VERSION ""

NS_ :

BS_:

BU_: Tester BMS VCU MCU_R MCU_F PDU_DCDC OBC IMM

BO_ 293 CombinedChargerUnit10msNo2: 20 VCU
 SG_ PowerETractSys1LimMotMax : 80|16@1+ (50,-1638300) [-1638300|1638450] "W"  MCU_R,MCU_F
 SG_ PowerETractSys1LimGenMax : 64|16@1+ (50,-1638300) [-1638300|1638450] "W"  MCU_R,MCU_F
 SG_ PowerETractSys2LimGenMax : 32|16@1+ (50,-1638300) [-1638300|1638450] "W"  MCU_R,MCU_F
 SG_ OperatingModeEANActualValue : 96|8@1+ (1,0) [0|255] ""  MCU_R,MCU_F
 SG_ PowerETractSys2LimMotMax : 48|16@1+ (50,-1638300) [-1638300|1638450] "W"  MCU_R,MCU_F
 SG_ RequestExtraBoostETractSys2 : 138|2@1+ (1,0) [0|3] ""  MCU_R,MCU_F
 SG_ RequestExtraBoostETractSys1 : 136|2@1+ (1,0) [0|3] ""  MCU_R,MCU_F

BO_ 296 BundleEAFlexrayToAECANFD10msNo1: 64 VCU
 SG_ TAR_RPM_MAX_FTAX : 336|16@1+ (0.01,0) [0|655.35] "rad/s"  MCU_R,MCU_F
 SG_ TAR_RPM_MIN_FTAX : 352|16@1+ (0.01,0) [0|655.35] "rad/s"  MCU_R,MCU_F
 SG_ ST_TAR_RPM_FTAX : 368|4@1+ (1,0) [0|15] ""  MCU_R,MCU_F
 SG_ CRC_StatusSlipThresholds : 456|8@1+ (1,0) [0|255] ""  MCU_R,MCU_F
 SG_ CHL_StatusSlipThresholds : 468|4@1+ (1,0) [0|15] ""  MCU_R,MCU_F
 SG_ StatusSlipThresholdsFrontAxle : 472|4@1+ (1,0) [0|15] ""  MCU_R,MCU_F
 SG_ StatusSlipThresholdsRearAxle : 476|4@1+ (1,0) [0|15] ""  MCU_R,MCU_F
 SG_ ALIV_StatusSlipThresholds : 464|4@1+ (1,0) [0|14] ""  MCU_R,MCU_F
 SG_ ALIV_RQ_RPM_FTAX : 328|4@1+ (1,0) [0|14] ""  MCU_R,MCU_F
 SG_ AVL_BRTORQ_WHL_FS_LH_EXT : 176|16@1+ (1,-32000) [-32000|33535] "Nm"  MCU_R,MCU_F
 SG_ AVL_BRTORQ_WHL_FS_RH_EXT : 192|16@1+ (1,-32000) [-32000|33535] "Nm"  MCU_R,MCU_F
 SG_ CHL_EXTS_ARB_INTF : 140|4@1+ (1,0) [0|15] ""  MCU_R,MCU_F
 SG_ CHL_RQ_RPM_FTAX : 332|4@1+ (1,0) [0|15] ""  MCU_R,MCU_F
 SG_ CRC_RQ_RPM_BAX : 256|8@1+ (1,0) [0|255] ""  MCU_R,MCU_F
 SG_ ALIV_EXTS_ARB_INTF : 136|4@1+ (1,0) [0|14] ""  MCU_R,MCU_F
 SG_ CRC_EXTS_ARB_INTF : 128|8@1+ (1,0) [0|255] ""  MCU_R,MCU_F
 SG_ ALIV_RQ_RPM_BAX : 264|4@1+ (1,0) [0|14] ""  MCU_R,MCU_F
 SG_ CHL_RQ_RPM_BAX : 268|4@1+ (1,0) [0|15] ""  MCU_R,MCU_F
 SG_ TAR_RPM_MAX_BAX : 272|16@1+ (0.01,0) [0|655.35] "rad/s"  MCU_R,MCU_F
 SG_ TAR_RPM_MIN_BAX : 288|16@1+ (0.01,0) [0|655.35] "rad/s"  MCU_R,MCU_F
 SG_ ST_TAR_RPM_BAX : 304|4@1+ (1,0) [0|15] ""  MCU_R,MCU_F
 SG_ TAR_STIF_SPCO : 308|4@1+ (1,0) [0|15] ""  MCU_R,MCU_F
 SG_ CRC_RQ_RPM_FTAX : 320|8@1+ (1,0) [0|255] ""  MCU_R,MCU_F
 SG_ AVL_BRTORQ_WHL_RS_RH_EXT : 160|16@1+ (1,-32000) [-32000|33535] "Nm"  MCU_R,MCU_F
 SG_ AVL_BRTORQ_WHL_RS_LH_EXT : 144|16@1+ (1,-32000) [-32000|33535] "Nm"  MCU_R,MCU_F

BO_ 297 BundleEAFlexrayToAECANFD20msNo2: 20 VCU
 SG_ CRC_ACLNX_COG : 0|8@1+ (1,0) [0|255] ""  MCU_R,MCU_F
 SG_ ALIV_ACLNY_COG : 56|4@1+ (1,0) [0|14] ""  MCU_R,MCU_F
 SG_ CRC_ACLNY_COG : 48|8@1+ (1,0) [0|255] ""  MCU_R,MCU_F
 SG_ ACLNY_COG : 64|16@1+ (0.002,-65) [-65|65] "m/s²"  MCU_R,MCU_F
 SG_ QU_ACLNY_COG : 92|4@1+ (1,0) [1|15] ""  MCU_R,MCU_F
 SG_ ALIV_ACLNX_COG : 8|4@1+ (1,0) [0|14] ""  MCU_R,MCU_F
 SG_ QU_ACLNX_COG : 44|4@1+ (1,0) [1|15] ""  MCU_R,MCU_F
 SG_ ACLNX_COG : 16|16@1+ (0.002,-65) [-65|65] "m/s²"  MCU_R,MCU_F

BO_ 314 TracEMacElectc1Time100msNo1: 32 MCU_R
 SG_ StatusETractSys1Degradation : 56|32@1+ (1,0) [0|4294967295] ""  VCU
 SG_ ALIV_TracEMacElectc1Time100msNo1 : 16|8@1+ (1,0) [0|254] ""  VCU
 SG_ TETractSys1InverterActVal : 200|8@1+ (1,-48) [-48|207] "°C"  VCU
 SG_ TETractSys1EmStatorActVal : 192|8@1+ (1,-48) [-48|207] "°C"  VCU
 SG_ ThermalStressLevelETractSys1 : 184|8@1+ (0.5,0) [0|127.5] "%"  VCU
 SG_ TETractSys1EmRotorActVal : 176|8@1+ (1,-48) [-48|207] "°C"  VCU
 SG_ StatusExtraBoostETractSys1 : 170|2@1+ (1,0) [0|3] ""  VCU
 SG_ PercentUsedExtraBoostETractSys1 : 160|10@1+ (0.1,0) [0|102.3] "%"  VCU
 SG_ TETractSys1GbxOilActVal : 208|8@1+ (1,-48) [-48|207] "°C"  VCU
 SG_ WhlRatElAxlEtractSys1ActVal : 144|16@1+ (0.001,0) [0|65.535] ""  VCU
 SG_ StatusETractSys1LossActive : 124|4@1+ (1,0) [0|15] ""  VCU
 SG_ OpModETractSys1ActVal : 116|8@1+ (1,0) [0|255] ""  VCU
 SG_ StatusETractSys1CoolingActVal : 112|4@1+ (1,0) [0|15] ""  VCU
 SG_ TETractSys1CoolantWaterInpActVal : 104|8@1+ (1,-48) [-48|207] "°C"  VCU
 SG_ ActStatMeclLossesGbxETractSys1 : 88|12@1+ (1,0) [0|4095] "W"  VCU
 SG_ StatusETractSys1Error : 24|32@1+ (1,0) [0|4294967295] ""  VCU
 SG_ PowerETractSys1MaximumLossActive : 128|10@1+ (50,0) [0|51150] "W"  VCU
 SG_ CRC_TracEMacElectc1Time100msNo1 : 0|16@1+ (1,0) [0|65535] ""  VCU

BO_ 326 TracEMacElectc2Time100msNo1: 32 MCU_F
 SG_ CRC_TracEMacElectc2Time100msNo1 : 0|16@1+ (1,0) [0|65535] ""  VCU
 SG_ StatusETractSys2Degradation : 56|32@1+ (1,0) [0|4294967295] ""  VCU
 SG_ ALIV_TracEMacElectc2Time100msNo1 : 16|8@1+ (1,0) [0|254] ""  VCU
 SG_ StatusETractSys2Error : 24|32@1+ (1,0) [0|4294967295] ""  VCU
 SG_ ActStatMeclLossesGbxETractSys2 : 88|12@1+ (1,0) [0|4095] "W"  VCU
 SG_ TETractSys2CoolantWaterInpActVal : 104|8@1+ (1,-48) [-48|207] "°C"  VCU
 SG_ OpModETractSys2ActVal : 116|8@1+ (1,0) [0|255] ""  VCU
 SG_ StatusETractSys2LossActive : 124|4@1+ (1,0) [0|15] ""  VCU
 SG_ PowerETractSys2MaximumLossActive : 128|10@1+ (50,0) [0|51150] "W"  VCU
 SG_ WhlRatElAxlEtractSys2ActVal : 144|16@1+ (0.001,0) [0|65.535] ""  VCU
 SG_ PercentUsedExtraBoostETractSys2 : 160|10@1+ (0.1,0) [0|102.3] "%"  VCU
 SG_ StatusETractSys2CoolingActVal : 112|4@1+ (1,0) [0|15] ""  VCU
 SG_ TETractSys2EmRotorActVal : 176|8@1+ (1,-48) [-48|207] "°C"  VCU
 SG_ ThermalStressLevelETractSys2 : 184|8@1+ (0.5,0) [0|127.5] "%"  VCU
 SG_ TETractSys2EmStatorActVal : 192|8@1+ (1,-48) [-48|207] "°C"  VCU
 SG_ TETractSys2InverterActVal : 200|8@1+ (1,-48) [-48|207] "°C"  VCU
 SG_ TETractSys2GbxOilActVal : 208|8@1+ (1,-48) [-48|207] "°C"  VCU
 SG_ StatusExtraBoostETractSys2 : 170|2@1+ (1,0) [0|3] ""  VCU

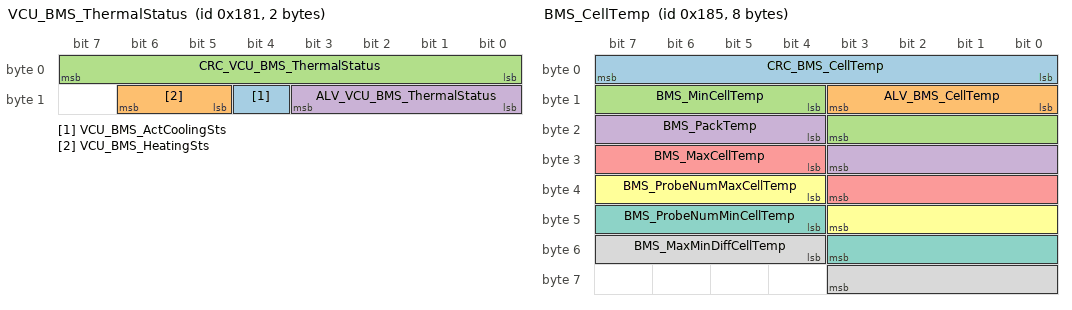
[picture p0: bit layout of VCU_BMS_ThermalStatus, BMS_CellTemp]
BO_ 385 VCU_BMS_ThermalStatus: 2 VCU
 SG_ VCU_BMS_ActCoolingSts : 12|1@1+ (1,0) [0|1] ""  BMS
 SG_ VCU_BMS_HeatingSts : 13|2@1+ (1,0) [0|3] ""  BMS
 SG_ CRC_VCU_BMS_ThermalStatus : 0|8@1+ (1,0) [0|255] ""  BMS
 SG_ ALV_VCU_BMS_ThermalStatus : 8|4@1+ (1,0) [0|14] ""  BMS

BO_ 389 BMS_CellTemp: 8 BMS
 SG_ CRC_BMS_CellTemp : 0|8@1+ (1,0) [0|255] ""  VCU
 SG_ ALV_BMS_CellTemp : 8|4@1+ (1,0) [0|14] ""  VCU
 SG_ BMS_MinCellTemp : 12|8@1+ (1,-40) [-40|215] "°C"  VCU
 SG_ BMS_PackTemp : 20|8@1+ (1,-40) [-40|215] "°C"  VCU
 SG_ BMS_MaxCellTemp : 28|8@1+ (1,-40) [-40|215] "°C"  VCU
 SG_ BMS_ProbeNumMaxCellTemp : 36|8@1+ (1,0) [0|255] ""  VCU
 SG_ BMS_ProbeNumMinCellTemp : 44|8@1+ (1,0) [0|255] ""  VCU
 SG_ BMS_MaxMinDiffCellTemp : 52|8@1+ (1,-40) [-40|215] "°C"  VCU

BO_ 394 BMS_CellTempMeas: 64 BMS
 SG_ BMS_CellTemp41 : 492|12@1+ (0.1,-40) [-40|215] "°C"  VCU
 SG_ BMS_CellTemp40 : 480|12@1+ (0.1,-40) [-40|215] "°C"  VCU
 SG_ BMS_CellTemp39 : 468|12@1+ (0.1,-40) [-40|215] "°C"  VCU
 SG_ BMS_CellTemp38 : 456|12@1+ (0.1,-40) [-40|215] "°C"  VCU
 SG_ BMS_CellTemp37 : 444|12@1+ (0.1,-40) [-40|215] "°C"  VCU
 SG_ BMS_CellTemp8 : 96|12@1+ (0.1,-40) [-40|215] "°C"  VCU
 SG_ BMS_CellTemp6 : 72|12@1+ (0.1,-40) [-40|215] "°C"  VCU
 SG_ BMS_CellTemp7 : 84|12@1+ (0.1,-40) [-40|215] "°C"  VCU
 SG_ BMS_CellTemp5 : 60|12@1+ (0.1,-40) [-40|215] "°C"  VCU
 SG_ ALV_BMS_CellTempMeas : 8|4@1+ (1,0) [0|14] ""  VCU
 SG_ BMS_CellTemp2 : 24|12@1+ (0.1,-40) [-40|215] "°C"  VCU
 SG_ BMS_CellTemp1 : 12|12@1+ (0.1,-40) [-40|215] "°C"  VCU
 SG_ CRC_BMS_CellTempMeas : 0|8@1+ (1,0) [0|255] ""  VCU
 SG_ BMS_CellTemp9 : 108|12@1+ (0.1,-40) [-40|215] "°C"  VCU
 SG_ BMS_CellTemp4 : 48|12@1+ (0.1,-40) [-40|215] "°C"  VCU
 SG_ BMS_CellTemp10 : 120|12@1+ (0.1,-40) [-40|215] "°C"  VCU
 SG_ BMS_CellTemp3 : 36|12@1+ (0.1,-40) [-40|215] "°C"  VCU
 SG_ BMS_CellTemp12 : 144|12@1+ (0.1,-40) [-40|215] "°C"  VCU
 SG_ BMS_CellTemp11 : 132|12@1+ (0.1,-40) [-40|215] "°C"  VCU
 SG_ BMS_CellTemp36 : 432|12@1+ (0.1,-40) [-40|215] "°C"  VCU
 SG_ BMS_CellTemp35 : 420|12@1+ (0.1,-40) [-40|215] "°C"  VCU
 SG_ BMS_CellTemp34 : 408|12@1+ (0.1,-40) [-40|215] "°C"  VCU
 SG_ BMS_CellTemp33 : 396|12@1+ (0.1,-40) [-40|215] "°C"  VCU
 SG_ BMS_CellTemp32 : 384|12@1+ (0.1,-40) [-40|215] "°C"  VCU
 SG_ BMS_CellTemp31 : 372|12@1+ (0.1,-40) [-40|215] "°C"  VCU
 SG_ BMS_CellTemp30 : 360|12@1+ (0.1,-40) [-40|215] "°C"  VCU
 SG_ BMS_CellTemp28 : 336|12@1+ (0.1,-40) [-40|215] "°C"  VCU
 SG_ BMS_CellTemp27 : 324|12@1+ (0.1,-40) [-40|215] "°C"  VCU
 SG_ BMS_CellTemp26 : 312|12@1+ (0.1,-40) [-40|215] "°C"  VCU
 SG_ BMS_CellTemp25 : 300|12@1+ (0.1,-40) [-40|215] "°C"  VCU
 SG_ BMS_CellTemp24 : 288|12@1+ (0.1,-40) [-40|215] "°C"  VCU
 SG_ BMS_CellTemp29 : 348|12@1+ (0.1,-40) [-40|215] "°C"  VCU
 SG_ BMS_CellTemp22 : 264|12@1+ (0.1,-40) [-40|215] "°C"  VCU
 SG_ BMS_CellTemp13 : 156|12@1+ (0.1,-40) [-40|215] "°C"  VCU
 SG_ BMS_CellTemp23 : 276|12@1+ (0.1,-40) [-40|215] "°C"  VCU
 SG_ BMS_CellTemp15 : 180|12@1+ (0.1,-40) [-40|215] "°C"  VCU
 SG_ BMS_CellTemp16 : 192|12@1+ (0.1,-40) [-40|215] "°C"  VCU
 SG_ BMS_CellTemp17 : 204|12@1+ (0.1,-40) [-40|215] "°C"  VCU
 SG_ BMS_CellTemp18 : 216|12@1+ (0.1,-40) [-40|215] "°C"  VCU
 SG_ BMS_CellTemp14 : 168|12@1+ (0.1,-40) [-40|215] "°C"  VCU
 SG_ BMS_CellTemp19 : 228|12@1+ (0.1,-40) [-40|215] "°C"  VCU
 SG_ BMS_CellTemp20 : 240|12@1+ (0.1,-40) [-40|215] "°C"  VCU
 SG_ BMS_CellTemp21 : 252|12@1+ (0.1,-40) [-40|215] "°C"  VCU

BO_ 399 BMS_CellVolMeas1: 48 BMS
 SG_ BMS_CellVol18 : 182|10@1+ (0.005,0) [0|5] "V"  VCU
 SG_ BMS_CellVol19 : 192|10@1+ (0.005,0) [0|5] "V"  VCU
 SG_ BMS_CellVol20 : 202|10@1+ (0.005,0) [0|5] "V"  VCU
 SG_ BMS_CellVol21 : 212|10@1+ (0.005,0) [0|5] "V"  VCU
 SG_ BMS_CellVol22 : 222|10@1+ (0.005,0) [0|5] "V"  VCU
 SG_ BMS_CellVol23 : 232|10@1+ (0.005,0) [0|5] "V"  VCU
 SG_ BMS_CellVol24 : 242|10@1+ (0.005,0) [0|5] "V"  VCU
 SG_ BMS_CellVol25 : 252|10@1+ (0.005,0) [0|5] "V"  VCU
 SG_ BMS_CellVol26 : 262|10@1+ (0.005,0) [0|5] "V"  VCU
 SG_ BMS_CellVol28 : 282|10@1+ (0.005,0) [0|5] "V"  VCU
 SG_ BMS_CellVol17 : 172|10@1+ (0.005,0) [0|5] "V"  VCU
 SG_ BMS_CellVol27 : 272|10@1+ (0.005,0) [0|5] "V"  VCU
 SG_ BMS_CellVol29 : 292|10@1+ (0.005,0) [0|5] "V"  VCU
 SG_ BMS_CellVol16 : 162|10@1+ (0.005,0) [0|5] "V"  VCU
 SG_ CRC_BMS_CellVolMeas : 0|8@1+ (1,0) [0|255] ""  VCU
 SG_ BMS_CellVol14 : 142|10@1+ (0.005,0) [0|5] "V"  VCU
 SG_ BMS_CellVol13 : 132|10@1+ (0.005,0) [0|5] "V"  VCU
 SG_ BMS_CellVol8 : 82|10@1+ (0.005,0) [0|5] "V"  VCU
 SG_ BMS_CellVol7 : 72|10@1+ (0.005,0) [0|5] "V"  VCU
 SG_ BMS_CellVol6 : 62|10@1+ (0.005,0) [0|5] "V"  VCU
 SG_ BMS_CellVol5 : 52|10@1+ (0.005,0) [0|5] "V"  VCU
 SG_ BMS_CellVol4 : 42|10@1+ (0.005,0) [0|5] "V"  VCU
 SG_ BMS_CellVol3 : 32|10@1+ (0.005,0) [0|5] "V"  VCU
 SG_ BMS_CellVol2 : 22|10@1+ (0.005,0) [0|5] "V"  VCU
 SG_ BMS_CellVol1 : 12|10@1+ (0.005,0) [0|5] "V"  VCU
 SG_ ALV_BMS_CellVolMeas : 8|4@1+ (1,0) [0|14] ""  VCU
 SG_ BMS_CellVol12 : 122|10@1+ (0.005,0) [0|5] "V"  VCU
 SG_ BMS_CellVol11 : 112|10@1+ (0.005,0) [0|5] "V"  VCU
 SG_ BMS_CellVol30 : 302|10@1+ (0.005,0) [0|5] "V"  VCU
 SG_ BMS_CellVol15 : 152|10@1+ (0.005,0) [0|5] "V"  VCU
 SG_ BMS_CellVol9 : 92|10@1+ (0.005,0) [0|5] "V"  VCU
 SG_ BMS_CellVol10 : 102|10@1+ (0.005,0) [0|5] "V"  VCU

BO_ 404 BMS_CellVolMeas2: 48 BMS
 SG_ BMS_CellVol56 : 262|10@1+ (0.005,0) [0|5] "V"  VCU
 SG_ BMS_CellVol38 : 82|10@1+ (0.005,0) [0|5] "V"  VCU
 SG_ BMS_CellVol37 : 72|10@1+ (0.005,0) [0|5] "V"  VCU
 SG_ BMS_CellVol36 : 62|10@1+ (0.005,0) [0|5] "V"  VCU
 SG_ BMS_CellVol35 : 52|10@1+ (0.005,0) [0|5] "V"  VCU
 SG_ BMS_CellVol34 : 42|10@1+ (0.005,0) [0|5] "V"  VCU
 SG_ BMS_CellVol33 : 32|10@1+ (0.005,0) [0|5] "V"  VCU
 SG_ BMS_CellVol32 : 22|10@1+ (0.005,0) [0|5] "V"  VCU
 SG_ BMS_CellVol31 : 12|10@1+ (0.005,0) [0|5] "V"  VCU
 SG_ ALV_BMS_CellVolMeas2 : 8|4@1+ (1,0) [0|14] ""  VCU
 SG_ CRC_BMS_CellVolMeas2 : 0|8@1+ (1,0) [0|255] ""  VCU
 SG_ BMS_CellVol59 : 292|10@1+ (0.005,0) [0|5] "V"  VCU
 SG_ BMS_CellVol60 : 302|10@1+ (0.005,0) [0|5] "V"  VCU
 SG_ BMS_CellVol61 : 312|10@1+ (0.005,0) [0|5] "V"  VCU
 SG_ BMS_CellVol62 : 322|10@1+ (0.005,0) [0|5] "V"  VCU
 SG_ BMS_CellVol57 : 272|10@1+ (0.005,0) [0|5] "V"  VCU
 SG_ BMS_CellVol39 : 92|10@1+ (0.005,0) [0|5] "V"  VCU
 SG_ BMS_CellVol40 : 102|10@1+ (0.005,0) [0|5] "V"  VCU
 SG_ BMS_CellVol42 : 122|10@1+ (0.005,0) [0|5] "V"  VCU
 SG_ BMS_CellVol49 : 192|10@1+ (0.005,0) [0|5] "V"  VCU
 SG_ BMS_CellVol53 : 232|10@1+ (0.005,0) [0|5] "V"  VCU
 SG_ BMS_CellVol52 : 222|10@1+ (0.005,0) [0|5] "V"  VCU
 SG_ BMS_CellVol51 : 212|10@1+ (0.005,0) [0|5] "V"  VCU
 SG_ BMS_CellVol50 : 202|10@1+ (0.005,0) [0|5] "V"  VCU
 SG_ BMS_CellVol48 : 182|10@1+ (0.005,0) [0|5] "V"  VCU
 SG_ BMS_CellVol46 : 162|10@1+ (0.005,0) [0|5] "V"  VCU
 SG_ BMS_CellVol47 : 172|10@1+ (0.005,0) [0|5] "V"  VCU
 SG_ BMS_CellVol44 : 142|10@1+ (0.005,0) [0|5] "V"  VCU
 SG_ BMS_CellVol43 : 132|10@1+ (0.005,0) [0|5] "V"  VCU
 SG_ BMS_CellVol58 : 282|10@1+ (0.005,0) [0|5] "V"  VCU
 SG_ BMS_CellVol41 : 112|10@1+ (0.005,0) [0|5] "V"  VCU
 SG_ BMS_CellVol55 : 252|10@1+ (0.005,0) [0|5] "V"  VCU
 SG_ BMS_CellVol45 : 152|10@1+ (0.005,0) [0|5] "V"  VCU
 SG_ BMS_CellVol54 : 242|10@1+ (0.005,0) [0|5] "V"  VCU

BO_ 405 OBC_Status: 20 OBC
 SG_ OBC_VCU_iDC : 120|11@1+ (0.1,-102.3) [-102.3|102.4] "Amps"  VCU
 SG_ OBC_VCU_vAC_L2 : 72|9@1+ (1,0) [0|511] "Volts"  VCU
 SG_ OBC_VCU_vAC_L1 : 40|9@1+ (1,0) [0|511] "Volts"  VCU
 SG_ OBC_VCU_iAC_L3 : 88|11@1+ (0.1,-102.3) [-102.3|102.4] "Amps"  VCU
 SG_ OBC_VCU_vDC : 131|10@1+ (1,0) [0|1023] "Volts"  VCU
 SG_ OBC_VCU_vAC_L3 : 104|9@1+ (1,0) [0|511] "Volts"  VCU
 SG_ OBC_VCU_iAC_L1 : 24|11@1+ (0.1,-102.3) [-102.3|102.4] "Amps"  VCU
 SG_ OBC_Max_Current_Out : 8|12@1+ (0.1,0) [0|409.5] "Amps"  VCU
 SG_ OBC_VCU_Status : 0|2@1+ (1,0) [0|3] ""  VCU
 SG_ OBC_VCU_iAC_L2 : 56|11@1+ (0.1,-102.3) [-102.3|102.4] "Amps"  VCU

BO_ 409 BMS_CellVolMeas3: 64 BMS
 SG_ BMS_CellVol82 : 202|10@1+ (0.005,0) [0|5] "V"  VCU
 SG_ BMS_CellVol86 : 242|10@1+ (0.005,0) [0|5] "V"  VCU
 SG_ BMS_CellVol83 : 212|10@1+ (0.005,0) [0|5] "V"  VCU
 SG_ BMS_CellVol84 : 222|10@1+ (0.005,0) [0|5] "V"  VCU
 SG_ BMS_CellVol87 : 252|10@1+ (0.005,0) [0|5] "V"  VCU
 SG_ BMS_CellVol94 : 322|10@1+ (0.005,0) [0|5] "V"  VCU
 SG_ BMS_CellVol89 : 272|10@1+ (0.005,0) [0|5] "V"  VCU
 SG_ BMS_CellVol90 : 282|10@1+ (0.005,0) [0|5] "V"  VCU
 SG_ BMS_CellVol91 : 292|10@1+ (0.005,0) [0|5] "V"  VCU
 SG_ BMS_CellVol92 : 302|10@1+ (0.005,0) [0|5] "V"  VCU
 SG_ BMS_CellVol93 : 312|10@1+ (0.005,0) [0|5] "V"  VCU
 SG_ BMS_CellVol81 : 192|10@1+ (0.005,0) [0|5] "V"  VCU
 SG_ BMS_CellVol88 : 262|10@1+ (0.005,0) [0|5] "V"  VCU
 SG_ BMS_CellVol80 : 182|10@1+ (0.005,0) [0|5] "V"  VCU
 SG_ BMS_CellVol85 : 232|10@1+ (0.005,0) [0|5] "V"  VCU
 SG_ BMS_CellVol78 : 162|10@1+ (0.005,0) [0|5] "V"  VCU
 SG_ BMS_CellVol70 : 82|10@1+ (0.005,0) [0|5] "V"  VCU
 SG_ BMS_CellVol67 : 52|10@1+ (0.005,0) [0|5] "V"  VCU
 SG_ BMS_CellVol79 : 172|10@1+ (0.005,0) [0|5] "V"  VCU
 SG_ BMS_CellVol66 : 42|10@1+ (0.005,0) [0|5] "V"  VCU
 SG_ BMS_CellVol65 : 32|10@1+ (0.005,0) [0|5] "V"  VCU
 SG_ BMS_CellVol64 : 22|10@1+ (0.005,0) [0|5] "V"  VCU
 SG_ BMS_CellVol63 : 12|10@1+ (0.005,0) [0|5] "V"  VCU
 SG_ ALV_BMS_CellVolMeas3 : 8|4@1+ (1,0) [0|14] ""  VCU
 SG_ BMS_CellVol69 : 72|10@1+ (0.005,0) [0|5] "V"  VCU
 SG_ CRC_BMS_CellVolMeas3 : 0|8@1+ (1,0) [0|255] ""  VCU
 SG_ BMS_CellVol71 : 92|10@1+ (0.005,0) [0|5] "V"  VCU
 SG_ BMS_CellVol68 : 62|10@1+ (0.005,0) [0|5] "V"  VCU
 SG_ BMS_CellVol73 : 112|10@1+ (0.005,0) [0|5] "V"  VCU
 SG_ BMS_CellVol75 : 132|10@1+ (0.005,0) [0|5] "V"  VCU
 SG_ BMS_CellVol72 : 102|10@1+ (0.005,0) [0|5] "V"  VCU
 SG_ BMS_CellVol77 : 152|10@1+ (0.005,0) [0|5] "V"  VCU
 SG_ BMS_CellVol74 : 122|10@1+ (0.005,0) [0|5] "V"  VCU
 SG_ BMS_CellVol76 : 142|10@1+ (0.005,0) [0|5] "V"  VCU
 SG_ BMS_CellVol95 : 332|10@1+ (0.005,0) [0|5] "V"  VCU
 SG_ BMS_CellVol96 : 342|10@1+ (0.005,0) [0|5] "V"  VCU
 SG_ BMS_CellVol97 : 352|10@1+ (0.005,0) [0|5] "V"  VCU
 SG_ BMS_CellVol98 : 362|10@1+ (0.005,0) [0|5] "V"  VCU
 SG_ BMS_CellVol99 : 372|10@1+ (0.005,0) [0|5] "V"  VCU
 SG_ BMS_CellVol100 : 382|10@1+ (0.005,0) [0|5] "V"  VCU
 SG_ BMS_CellVol101 : 392|10@1+ (0.005,0) [0|5] "V"  VCU
 SG_ BMS_CellVol102 : 402|10@1+ (0.005,0) [0|5] "V"  VCU
 SG_ BMS_CellVol103 : 412|10@1+ (0.005,0) [0|5] "V"  VCU
 SG_ BMS_CellVol104 : 422|10@1+ (0.005,0) [0|5] "V"  VCU
 SG_ BMS_CellVol105 : 432|10@1+ (0.005,0) [0|5] "V"  VCU
 SG_ BMS_CellVol106 : 442|10@1+ (0.005,0) [0|5] "V"  VCU
 SG_ BMS_CellVol107 : 452|10@1+ (0.005,0) [0|5] "V"  VCU
 SG_ BMS_CellVol108 : 462|10@1+ (0.005,0) [0|5] "V"  VCU

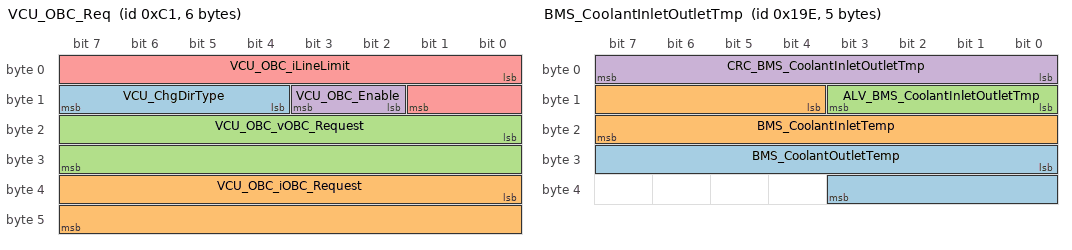
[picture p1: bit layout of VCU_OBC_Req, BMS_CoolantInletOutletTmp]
BO_ 193 VCU_OBC_Req: 6 VCU
 SG_ VCU_ChgDirType : 12|4@1+ (1,0) [0|15] ""  OBC
 SG_ VCU_OBC_iOBC_Request : 32|16@1+ (0.0625,0) [0|4095.9375] "Amps"  OBC
 SG_ VCU_OBC_vOBC_Request : 16|16@1+ (0.0625,0) [0|4095.9375] "Volts"  OBC
 SG_ VCU_OBC_Enable : 10|2@1+ (1,0) [0|3] ""  OBC
 SG_ VCU_OBC_iLineLimit : 0|10@1+ (0.0625,0) [0|63.9375] "Amps"  OBC

BO_ 414 BMS_CoolantInletOutletTmp: 5 BMS
 SG_ BMS_CoolantOutletTemp : 24|12@1+ (0.1,-40) [-40|255] "°C"  VCU
 SG_ BMS_CoolantInletTemp : 12|12@1+ (0.1,-40) [-40|255] "°C"  VCU
 SG_ ALV_BMS_CoolantInletOutletTmp : 8|4@1+ (1,0) [0|14] ""  VCU
 SG_ CRC_BMS_CoolantInletOutletTmp : 0|8@1+ (1,0) [0|255] ""  VCU

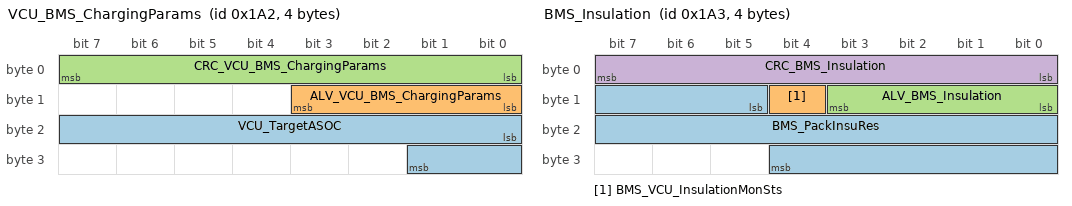
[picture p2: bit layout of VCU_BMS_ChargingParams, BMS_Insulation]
BO_ 418 VCU_BMS_ChargingParams: 4 VCU
 SG_ VCU_TargetASOC : 16|10@1+ (0.1,0) [0|100] "%"  BMS
 SG_ ALV_VCU_BMS_ChargingParams : 8|4@1+ (1,0) [0|14] ""  BMS
 SG_ CRC_VCU_BMS_ChargingParams : 0|8@1+ (1,0) [0|255] ""  BMS

BO_ 419 BMS_Insulation: 4 BMS
 SG_ BMS_PackInsuRes : 13|16@1+ (1,0) [0|60000] "kOhm"  VCU
 SG_ BMS_VCU_InsulationMonSts : 12|1@1+ (1,0) [0|1] ""  VCU
 SG_ ALV_BMS_Insulation : 8|4@1+ (1,0) [0|14] ""  VCU
 SG_ CRC_BMS_Insulation : 0|8@1+ (1,0) [0|255] ""  VCU

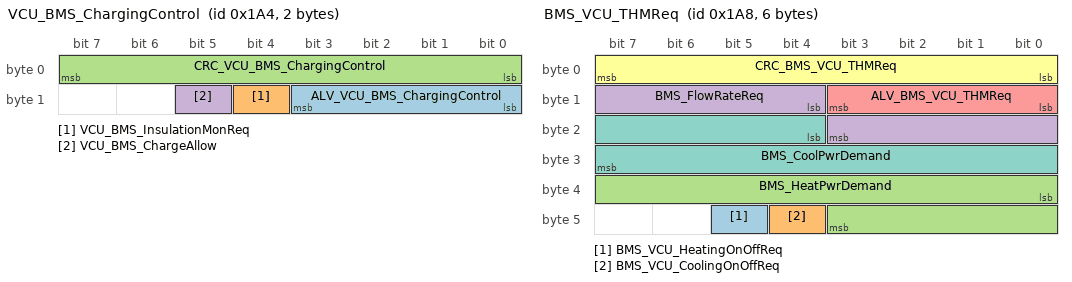
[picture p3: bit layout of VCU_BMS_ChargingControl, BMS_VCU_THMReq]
BO_ 420 VCU_BMS_ChargingControl: 2 VCU
 SG_ ALV_VCU_BMS_ChargingControl : 8|4@1+ (1,0) [0|14] ""  BMS
 SG_ VCU_BMS_InsulationMonReq : 12|1@1+ (1,0) [0|1] ""  BMS
 SG_ CRC_VCU_BMS_ChargingControl : 0|8@1+ (1,0) [0|255] ""  BMS
 SG_ VCU_BMS_ChargeAllow : 13|1@1+ (1,0) [0|1] ""  BMS

BO_ 424 BMS_VCU_THMReq: 6 BMS
 SG_ BMS_VCU_HeatingOnOffReq : 45|1@1+ (1,0) [0|1] ""  VCU
 SG_ BMS_VCU_CoolingOnOffReq : 44|1@1+ (1,0) [0|1] ""  VCU
 SG_ BMS_HeatPwrDemand : 32|12@1+ (0.1,0) [0|25.5] "kW"  VCU
 SG_ BMS_FlowRateReq : 12|8@1+ (1,0) [0|255] "l/min"  VCU
 SG_ ALV_BMS_VCU_THMReq : 8|4@1+ (1,0) [0|14] ""  VCU
 SG_ CRC_BMS_VCU_THMReq : 0|8@1+ (1,0) [0|255] ""  VCU
 SG_ BMS_CoolPwrDemand : 20|12@1+ (0.1,0) [0|25.5] "kW"  VCU

BO_ 429 BMS_VolMeas: 12 BMS
 SG_ BMS_MaxCellVol : 44|16@1+ (0.001,0) [0|5] "V"  VCU
 SG_ BMS_MinCellVol : 28|16@1+ (0.001,0) [0|5] "V"  VCU
 SG_ BMS_CellNumMaxCellVol : 20|8@1+ (1,0) [0|112] ""  VCU
 SG_ BMS_CellNumMinCellVol : 12|8@1+ (1,0) [0|112] ""  VCU
 SG_ ALV_BMS_VolMeas : 8|4@1+ (1,0) [0|14] ""  VCU
 SG_ CRC_BMS_VolMeas : 0|8@1+ (1,0) [0|255] ""  VCU
 SG_ BMS_MaxMinDiffCellVol : 60|16@1+ (0.001,0) [0|5] "V"  VCU

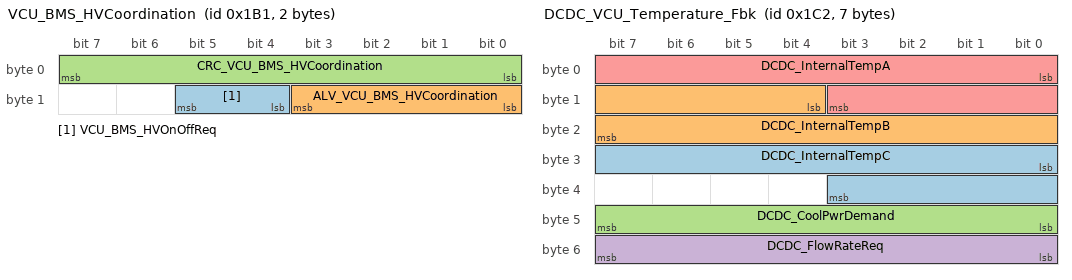
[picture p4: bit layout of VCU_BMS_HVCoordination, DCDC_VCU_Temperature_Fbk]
BO_ 433 VCU_BMS_HVCoordination: 2 VCU
 SG_ VCU_BMS_HVOnOffReq : 12|2@1+ (1,0) [0|3] ""  BMS
 SG_ ALV_VCU_BMS_HVCoordination : 8|4@1+ (1,0) [0|14] ""  BMS
 SG_ CRC_VCU_BMS_HVCoordination : 0|8@1+ (1,0) [0|255] ""  BMS

BO_ 450 DCDC_VCU_Temperature_Fbk: 7 PDU_DCDC
 SG_ DCDC_InternalTempC : 24|12@1+ (0.1,-100) [-100|309.5] "°C"  VCU
 SG_ DCDC_InternalTempB : 12|12@1+ (0.1,-100) [-100|309.5] "°C"  VCU
 SG_ DCDC_CoolPwrDemand : 40|8@1+ (0.01,0) [0|2.55] "kW"  VCU
 SG_ DCDC_FlowRateReq : 48|8@1+ (1,0) [0|31] "l/min"  VCU
 SG_ DCDC_InternalTempA : 0|12@1+ (0.1,-100) [-100|309.5] "°C"  VCU

BO_ 490 Kilometerstand_2: 8 VCU
 SG_ MILE_KM_TOT : 0|32@1+ (0.001,0) [0|4294967.295] "km"  MCU_R,MCU_F

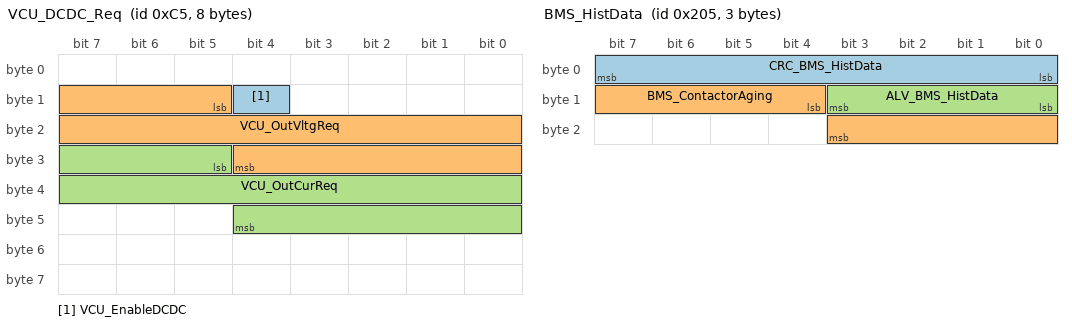
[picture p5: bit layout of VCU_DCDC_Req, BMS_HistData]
BO_ 197 VCU_DCDC_Req: 8 VCU
 SG_ VCU_EnableDCDC : 12|1@1+ (1,0) [0|1] ""  PDU_DCDC
 SG_ VCU_OutVltgReq : 13|16@1+ (0.0625,0) [0|4095.9375] "V"  PDU_DCDC
 SG_ VCU_OutCurReq : 29|16@1+ (0.1,0) [0|6553.5] "A"  PDU_DCDC

BO_ 517 BMS_HistData: 3 BMS
 SG_ CRC_BMS_HistData : 0|8@1+ (1,0) [0|255] ""  VCU
 SG_ BMS_ContactorAging : 12|8@1+ (1,0) [0|100] "%"  VCU
 SG_ ALV_BMS_HistData : 8|4@1+ (1,0) [0|14] ""  VCU

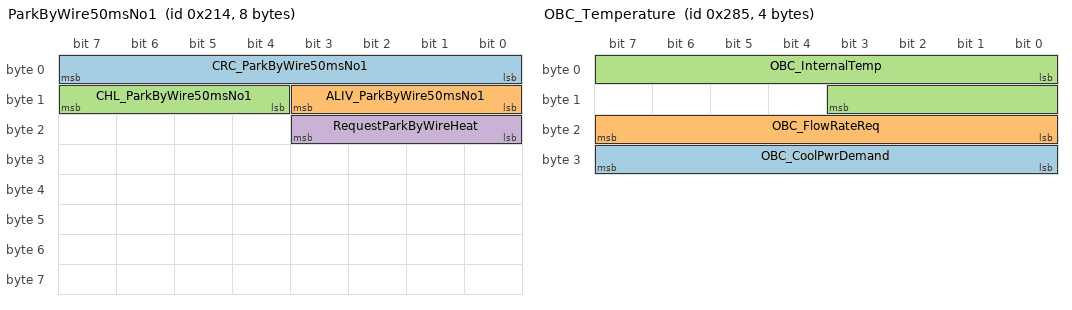
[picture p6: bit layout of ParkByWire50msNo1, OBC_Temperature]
BO_ 532 ParkByWire50msNo1: 8 VCU
 SG_ CRC_ParkByWire50msNo1 : 0|8@1+ (1,0) [0|255] ""  MCU_R,MCU_F
 SG_ ALIV_ParkByWire50msNo1 : 8|4@1+ (1,0) [0|14] ""  MCU_R,MCU_F
 SG_ CHL_ParkByWire50msNo1 : 12|4@1+ (1,0) [0|15] ""  MCU_R,MCU_F
 SG_ RequestParkByWireHeat : 16|4@1+ (1,0) [0|15] ""  MCU_R,MCU_F

BO_ 630 FZZSTD: 8 VCU
 SG_ ST_ENERG_FZM : 16|4@1+ (1,0) [0|15] ""  MCU_R,MCU_F
 SG_ ST_ILK_ERRM_FZM : 56|2@1+ (1,0) [0|3] ""  MCU_R,MCU_F

BO_ 632 STAT_ANHAENGER: 8 VCU
 SG_ ST_TRAI : 0|2@1+ (1,0) [0|3] ""  MCU_R,MCU_F

BO_ 645 OBC_Temperature: 4 OBC
 SG_ OBC_CoolPwrDemand : 24|8@1+ (0.1,0) [0|25.5] "Kw"  VCU
 SG_ OBC_FlowRateReq : 16|8@1+ (1,0) [0|31] "l/min"  VCU
 SG_ OBC_InternalTemp : 0|12@1+ (0.1,-50) [-50|359.5] "°C"  VCU

BO_ 749 A_TEMP: 2 VCU
 SG_ TEMP_EX : 0|8@1+ (0.5,-40) [-40|87.5] "°C"  BMS,MCU_R,MCU_F

BO_ 811 DMEBK100: 24 VCU
 SG_ ActValVolFlowCoolantETractSys1 : 80|8@1+ (20,0) [0|5100] "l/h"  MCU_R,MCU_F
 SG_ ActValVolFlowCoolantETractSys2 : 56|8@1+ (20,0) [0|5100] "l/h"  MCU_R,MCU_F

BO_ 832 CombinedChargerUnit100msNo1: 12 VCU
 SG_ ALIV_CombinedChargerUnit100msNo1 : 16|8@1+ (1,0) [0|254] ""  MCU_R,MCU_F
 SG_ RequestPowerETractSys1Loss : 48|10@1+ (50,0) [0|51150] "W"  MCU_R,MCU_F
 SG_ CRC_CombinedChargerUnit100msNo1 : 0|16@1+ (1,0) [0|65535] ""  MCU_R,MCU_F
 SG_ RequestPowerETractSys2Loss : 58|10@1+ (50,0) [0|51150] "W"  MCU_R,MCU_F

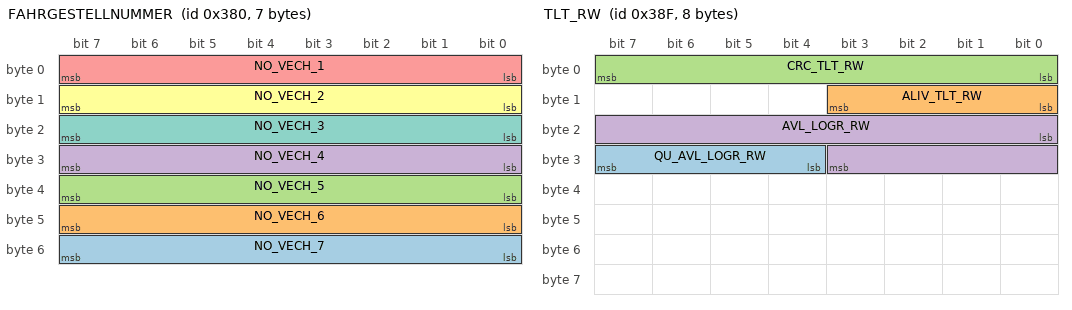
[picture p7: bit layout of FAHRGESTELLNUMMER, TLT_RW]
BO_ 896 FAHRGESTELLNUMMER: 7 VCU
 SG_ NO_VECH_7 : 48|8@1+ (1,0) [0|255] ""  MCU_R,MCU_F
 SG_ NO_VECH_6 : 40|8@1+ (1,0) [0|255] ""  MCU_R,MCU_F
 SG_ NO_VECH_5 : 32|8@1+ (1,0) [0|255] ""  MCU_R,MCU_F
 SG_ NO_VECH_4 : 24|8@1+ (1,0) [0|255] ""  MCU_R,MCU_F
 SG_ NO_VECH_1 : 0|8@1+ (1,0) [0|255] ""  MCU_R,MCU_F
 SG_ NO_VECH_2 : 8|8@1+ (1,0) [0|255] ""  MCU_R,MCU_F
 SG_ NO_VECH_3 : 16|8@1+ (1,0) [0|255] ""  MCU_R,MCU_F

BO_ 911 TLT_RW: 8 VCU
 SG_ QU_AVL_LOGR_RW : 28|4@1+ (1,0) [1|15] ""  MCU_R,MCU_F
 SG_ ALIV_TLT_RW : 8|4@1+ (1,0) [0|14] ""  MCU_R,MCU_F
 SG_ CRC_TLT_RW : 0|8@1+ (1,0) [0|255] ""  MCU_R,MCU_F
 SG_ AVL_LOGR_RW : 16|12@1+ (0.05,-64) [-64|140.75] "°"  MCU_R,MCU_F

BO_ 1052 KILOMETERSTAND: 8 VCU
 SG_ MILE_KM : 0|24@1+ (1,0) [0|16777215] "km"  MCU_R,MCU_F

BO_ 1090 RELATIVZEIT: 6 VCU
 SG_ T_SEC_COU_REL : 0|32@1+ (1,0) [0|4294967295] "s"  MCU_R,MCU_F

BO_ 1107 HighVoltageStorage200msNo1: 4 BMS
 SG_ StsDisconnectingSwtHighVoltStorg : 26|6@1+ (1,0) [0|63] ""  VCU,MCU_R,MCU_F
 SG_ StatusServiceDisconnectionPlug : 24|2@1+ (1,0) [1|3] ""  VCU,MCU_R,MCU_F

BO_ 1120 EnergyStorageMeasurementValues: 8 VCU
 SG_ EnergyStorageClamp30VoltageValue : 16|16@1+ (0.001,0) [0|65.535] "V"  MCU_R,MCU_F

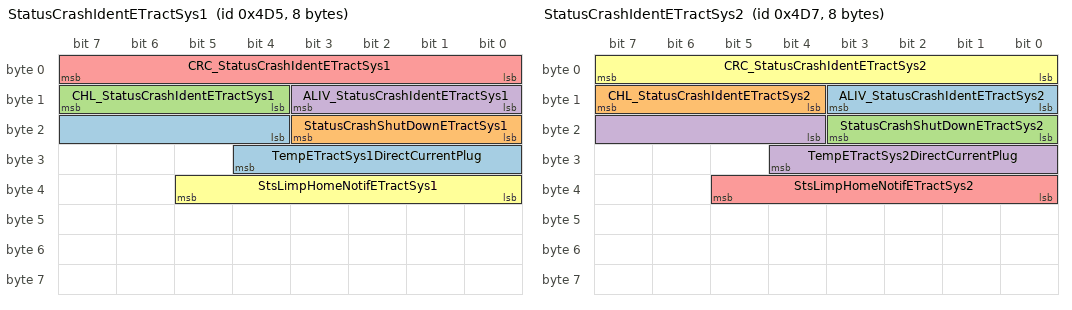
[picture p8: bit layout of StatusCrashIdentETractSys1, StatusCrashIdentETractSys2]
BO_ 1237 StatusCrashIdentETractSys1: 8 MCU_R
 SG_ TempETractSys1DirectCurrentPlug : 20|9@1+ (0.5,-40) [-40|215.5] "°C"  VCU
 SG_ StatusCrashShutDownETractSys1 : 16|4@1+ (1,0) [0|15] ""  VCU
 SG_ CHL_StatusCrashIdentETractSys1 : 12|4@1+ (1,0) [0|15] ""  VCU
 SG_ ALIV_StatusCrashIdentETractSys1 : 8|4@1+ (1,0) [0|14] ""  VCU
 SG_ CRC_StatusCrashIdentETractSys1 : 0|8@1+ (1,0) [0|255] ""  VCU
 SG_ StsLimpHomeNotifETractSys1 : 32|6@1+ (1,0) [0|63] ""  VCU

BO_ 1239 StatusCrashIdentETractSys2: 8 MCU_F
 SG_ ALIV_StatusCrashIdentETractSys2 : 8|4@1+ (1,0) [0|14] ""  VCU
 SG_ CHL_StatusCrashIdentETractSys2 : 12|4@1+ (1,0) [0|15] ""  VCU
 SG_ StatusCrashShutDownETractSys2 : 16|4@1+ (1,0) [0|15] ""  VCU
 SG_ TempETractSys2DirectCurrentPlug : 20|9@1+ (0.5,-40) [-40|215.5] "°C"  VCU
 SG_ StsLimpHomeNotifETractSys2 : 32|6@1+ (1,0) [0|63] ""  VCU
 SG_ CRC_StatusCrashIdentETractSys2 : 0|8@1+ (1,0) [0|255] ""  VCU

BO_ 1272 CombinedChargerUnit1000msNo1: 24 VCU
 SG_ TemperatureCoolantOutput : 44|12@1+ (0.1,-40) [-40|369.5] "°C"  MCU_R,MCU_F

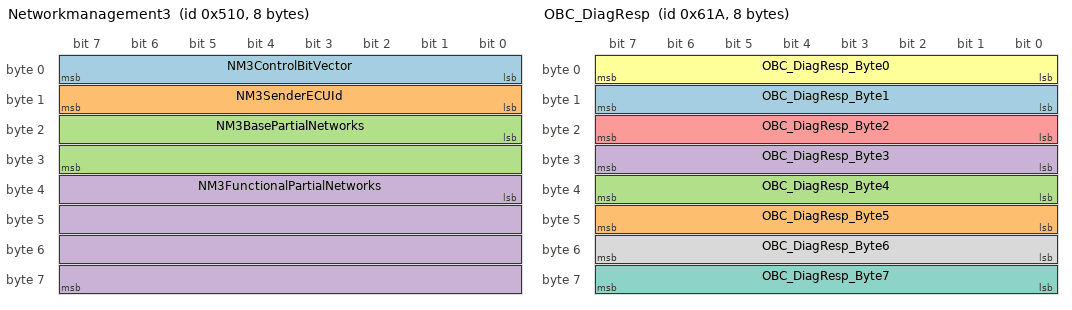
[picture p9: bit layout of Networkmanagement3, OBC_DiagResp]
BO_ 1296 Networkmanagement3: 8 VCU
 SG_ NM3ControlBitVector : 0|8@1+ (1,0) [64|255] ""  MCU_R,MCU_F
 SG_ NM3SenderECUId : 8|8@1+ (1,0) [0|255] ""  MCU_R,MCU_F
 SG_ NM3BasePartialNetworks : 16|16@1+ (1,0) [0|65535] ""  MCU_R,MCU_F
 SG_ NM3FunctionalPartialNetworks : 32|32@1+ (1,0) [0|4294967295] ""  MCU_R,MCU_F

BO_ 1562 OBC_DiagResp: 8 OBC
 SG_ OBC_DiagResp_Byte1 : 8|8@1+ (1,0) [0|255] ""  Tester
 SG_ OBC_DiagResp_Byte5 : 40|8@1+ (1,0) [0|255] ""  Tester
 SG_ OBC_DiagResp_Byte4 : 32|8@1+ (1,0) [0|255] ""  Tester
 SG_ OBC_DiagResp_Byte3 : 24|8@1+ (1,0) [0|255] ""  Tester
 SG_ OBC_DiagResp_Byte2 : 16|8@1+ (1,0) [0|255] ""  Tester
 SG_ OBC_DiagResp_Byte0 : 0|8@1+ (1,0) [0|255] ""  Tester
 SG_ OBC_DiagResp_Byte7 : 56|8@1+ (1,0) [0|255] ""  Tester
 SG_ OBC_DiagResp_Byte6 : 48|8@1+ (1,0) [0|255] ""  Tester

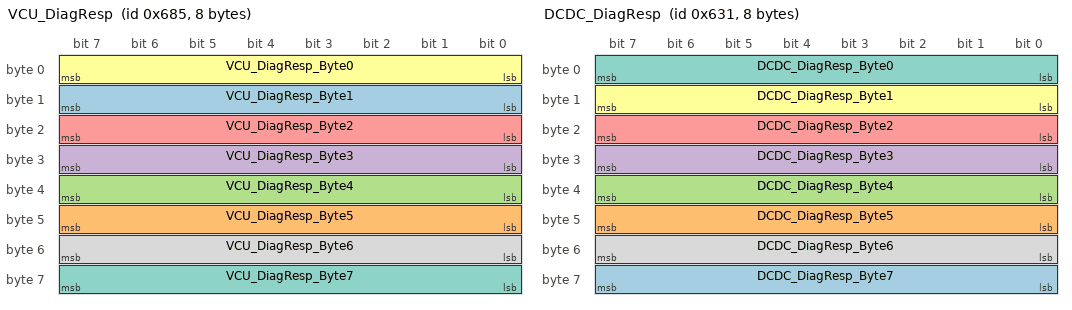
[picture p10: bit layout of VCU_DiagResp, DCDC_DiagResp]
BO_ 1669 VCU_DiagResp: 8 VCU
 SG_ VCU_DiagResp_Byte1 : 8|8@1+ (1,0) [0|255] ""  Tester
 SG_ VCU_DiagResp_Byte5 : 40|8@1+ (1,0) [0|255] ""  Tester
 SG_ VCU_DiagResp_Byte4 : 32|8@1+ (1,0) [0|255] ""  Tester
 SG_ VCU_DiagResp_Byte3 : 24|8@1+ (1,0) [0|255] ""  Tester
 SG_ VCU_DiagResp_Byte2 : 16|8@1+ (1,0) [0|255] ""  Tester
 SG_ VCU_DiagResp_Byte0 : 0|8@1+ (1,0) [0|255] ""  Tester
 SG_ VCU_DiagResp_Byte7 : 56|8@1+ (1,0) [0|255] ""  Tester
 SG_ VCU_DiagResp_Byte6 : 48|8@1+ (1,0) [0|255] ""  Tester

BO_ 1585 DCDC_DiagResp: 8 PDU_DCDC
 SG_ DCDC_DiagResp_Byte7 : 56|8@1+ (1,0) [0|255] ""  Tester
 SG_ DCDC_DiagResp_Byte5 : 40|8@1+ (1,0) [0|255] ""  Tester
 SG_ DCDC_DiagResp_Byte4 : 32|8@1+ (1,0) [0|255] ""  Tester
 SG_ DCDC_DiagResp_Byte3 : 24|8@1+ (1,0) [0|255] ""  Tester
 SG_ DCDC_DiagResp_Byte2 : 16|8@1+ (1,0) [0|255] ""  Tester
 SG_ DCDC_DiagResp_Byte1 : 8|8@1+ (1,0) [0|255] ""  Tester
 SG_ DCDC_DiagResp_Byte0 : 0|8@1+ (1,0) [0|255] ""  Tester
 SG_ DCDC_DiagResp_Byte6 : 48|8@1+ (1,0) [0|255] ""  Tester

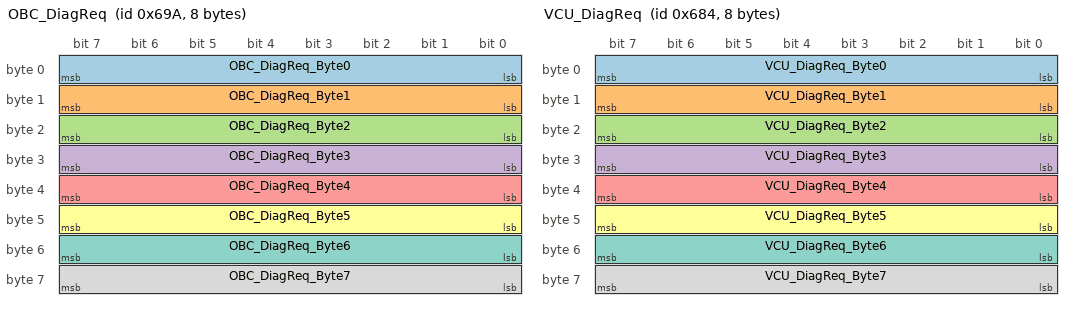
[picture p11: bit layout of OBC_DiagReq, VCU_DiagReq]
BO_ 1690 OBC_DiagReq: 8 Tester
 SG_ OBC_DiagReq_Byte0 : 0|8@1+ (1,0) [0|255] ""  OBC
 SG_ OBC_DiagReq_Byte1 : 8|8@1+ (1,0) [0|255] ""  OBC
 SG_ OBC_DiagReq_Byte2 : 16|8@1+ (1,0) [0|255] ""  OBC
 SG_ OBC_DiagReq_Byte3 : 24|8@1+ (1,0) [0|255] ""  OBC
 SG_ OBC_DiagReq_Byte4 : 32|8@1+ (1,0) [0|255] ""  OBC
 SG_ OBC_DiagReq_Byte5 : 40|8@1+ (1,0) [0|255] ""  OBC
 SG_ OBC_DiagReq_Byte6 : 48|8@1+ (1,0) [0|255] ""  OBC
 SG_ OBC_DiagReq_Byte7 : 56|8@1+ (1,0) [0|255] ""  OBC

BO_ 1668 VCU_DiagReq: 8 Tester
 SG_ VCU_DiagReq_Byte0 : 0|8@1+ (1,0) [0|255] ""  VCU
 SG_ VCU_DiagReq_Byte1 : 8|8@1+ (1,0) [0|255] ""  VCU
 SG_ VCU_DiagReq_Byte2 : 16|8@1+ (1,0) [0|255] ""  VCU
 SG_ VCU_DiagReq_Byte3 : 24|8@1+ (1,0) [0|255] ""  VCU
 SG_ VCU_DiagReq_Byte4 : 32|8@1+ (1,0) [0|255] ""  VCU
 SG_ VCU_DiagReq_Byte5 : 40|8@1+ (1,0) [0|255] ""  VCU
 SG_ VCU_DiagReq_Byte6 : 48|8@1+ (1,0) [0|255] ""  VCU
 SG_ VCU_DiagReq_Byte7 : 56|8@1+ (1,0) [0|255] ""  VCU

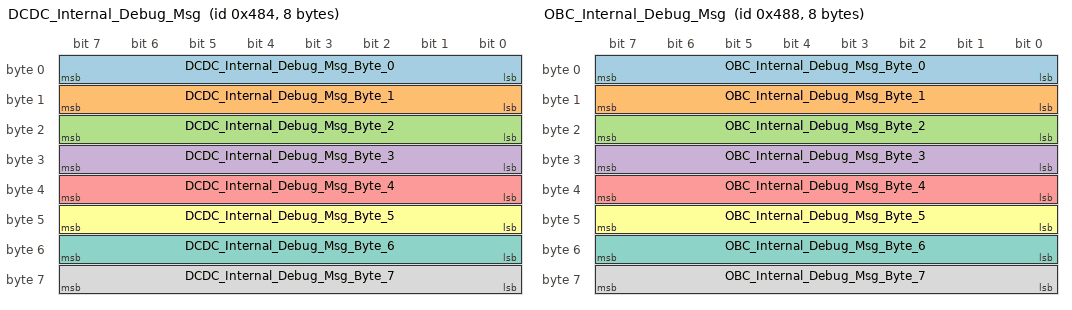
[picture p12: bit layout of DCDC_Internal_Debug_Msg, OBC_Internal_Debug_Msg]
BO_ 1156 DCDC_Internal_Debug_Msg: 8 PDU_DCDC
 SG_ DCDC_Internal_Debug_Msg_Byte_0 : 0|8@1+ (1,0) [0|255] ""  Tester
 SG_ DCDC_Internal_Debug_Msg_Byte_1 : 8|8@1+ (1,0) [0|255] ""  Tester
 SG_ DCDC_Internal_Debug_Msg_Byte_2 : 16|8@1+ (1,0) [0|255] ""  Tester
 SG_ DCDC_Internal_Debug_Msg_Byte_3 : 24|8@1+ (1,0) [0|255] ""  Tester
 SG_ DCDC_Internal_Debug_Msg_Byte_4 : 32|8@1+ (1,0) [0|255] ""  Tester
 SG_ DCDC_Internal_Debug_Msg_Byte_5 : 40|8@1+ (1,0) [0|255] ""  Tester
 SG_ DCDC_Internal_Debug_Msg_Byte_6 : 48|8@1+ (1,0) [0|255] ""  Tester
 SG_ DCDC_Internal_Debug_Msg_Byte_7 : 56|8@1+ (1,0) [0|255] ""  Tester

BO_ 1160 OBC_Internal_Debug_Msg: 8 OBC
 SG_ OBC_Internal_Debug_Msg_Byte_0 : 0|8@1+ (1,0) [0|255] ""  Tester
 SG_ OBC_Internal_Debug_Msg_Byte_1 : 8|8@1+ (1,0) [0|255] ""  Tester
 SG_ OBC_Internal_Debug_Msg_Byte_2 : 16|8@1+ (1,0) [0|255] ""  Tester
 SG_ OBC_Internal_Debug_Msg_Byte_3 : 24|8@1+ (1,0) [0|255] ""  Tester
 SG_ OBC_Internal_Debug_Msg_Byte_4 : 32|8@1+ (1,0) [0|255] ""  Tester
 SG_ OBC_Internal_Debug_Msg_Byte_5 : 40|8@1+ (1,0) [0|255] ""  Tester
 SG_ OBC_Internal_Debug_Msg_Byte_6 : 48|8@1+ (1,0) [0|255] ""  Tester
 SG_ OBC_Internal_Debug_Msg_Byte_7 : 56|8@1+ (1,0) [0|255] ""  Tester

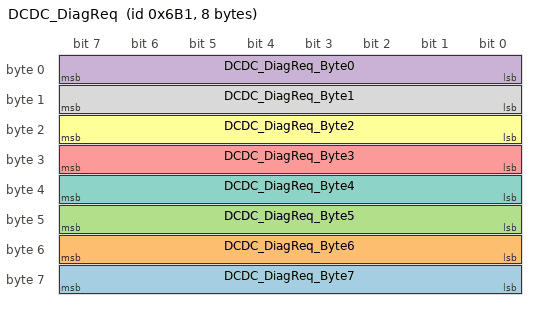
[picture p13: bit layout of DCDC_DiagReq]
BO_ 1713 DCDC_DiagReq: 8 Tester
 SG_ DCDC_DiagReq_Byte7 : 56|8@1+ (1,0) [0|255] ""  PDU_DCDC
 SG_ DCDC_DiagReq_Byte6 : 48|8@1+ (1,0) [0|255] ""  PDU_DCDC
 SG_ DCDC_DiagReq_Byte5 : 40|8@1+ (1,0) [0|255] ""  PDU_DCDC
 SG_ DCDC_DiagReq_Byte0 : 0|8@1+ (1,0) [0|255] ""  PDU_DCDC
 SG_ DCDC_DiagReq_Byte3 : 24|8@1+ (1,0) [0|255] ""  PDU_DCDC
 SG_ DCDC_DiagReq_Byte2 : 16|8@1+ (1,0) [0|255] ""  PDU_DCDC
 SG_ DCDC_DiagReq_Byte4 : 32|8@1+ (1,0) [0|255] ""  PDU_DCDC
 SG_ DCDC_DiagReq_Byte1 : 8|8@1+ (1,0) [0|255] ""  PDU_DCDC

CM_ BO_ 293 "-";
CM_ SG_ 293 PowerETractSys1LimMotMax "Maximum approved motorized electric power of electric machine system 1.
Fixed Value = 1638300";
CM_ SG_ 293 PowerETractSys1LimGenMax "Maximum approved regenerative electric power of electric machine system 1.
Fixed Value = 0";
CM_ SG_ 293 PowerETractSys2LimGenMax "Maximum approved regenerative electric power of electric machine system 2.,
Fixed Value = 0";
CM_ SG_ 293 OperatingModeEANActualValue "Actual operating mode of complete electric drive system. This signal is used for the drive network. For control units that are not from the drive network, the signal ST_MOT_DRV is provided.";
CM_ SG_ 293 PowerETractSys2LimMotMax "Maximum approved motorized electric power of electric machine system 2.
Fixed Value = 1638300";
CM_ SG_ 293 RequestExtraBoostETractSys2 "Additional torque as torque boost, requested for electric machine system 2 (ExtraBoost in PowerMode).
Fixed Value = 0";
CM_ SG_ 293 RequestExtraBoostETractSys1 "Additional torque as torque boost, requested for electric machine system 1 (ExtraBoost in PowerMode).
Fixed Value = 0";
CM_ BO_ 296 "-";
CM_ SG_ 296 TAR_RPM_MAX_FTAX "Maximum wheel speed at the front axle.
The wheel speed of the front axle is the mean value of the wheel speed front left and the wheel speed front right.
Fixed Value = 40000";
CM_ SG_ 296 TAR_RPM_MIN_FTAX "Minimum wheel speed at the front axle.
The wheel speed of the front axle is the mean value of the wheel speed front left and the wheel speed front right.
Fixed Value = 0";
CM_ SG_ 296 ST_TAR_RPM_FTAX "With this status, the limits to the minimum and maximum wheel speed limit for the front axle can be activated or deactivated.
Fixed Value = 0";
CM_ SG_ 296 CRC_StatusSlipThresholds "This signal contains the CRC checksum for the extended standard application CRC validation according to application profile 1C E2E Protection (Autosar SWS 428). 
The application data ID (12 bit) 886 (dez) = 0376 (hex) is assigned to the signal. ";
CM_ SG_ 296 CHL_StatusSlipThresholds "This signal explicitly contains the value of the extension ID = 3 (dez) = 3 (hex)  for the extended CRC validation according to Autosar_SWS_E2ELibrary profile 1C.
Fixed Value = 3";
CM_ SG_ 296 StatusSlipThresholdsFrontAxle "Slip status of front axle. This information is relevant for deactivation of comfort functions (i. e. ASD) and for functional safety.
Fixed Value = 0";
CM_ SG_ 296 StatusSlipThresholdsRearAxle "Slip status of rear axle. This information is relevant for deactivation of comfort functions (i. e. ASD) and for functional safety.
Fixed Value = 0";
CM_ SG_ 296 ALIV_StatusSlipThresholds "Standard protection alive counter as defined in the on-board data communication requirements specification.";
CM_ SG_ 296 ALIV_RQ_RPM_FTAX "Standard alive counter validation as per definition in the requirements specification Allgemeine Bordnetzkommunikation.";
CM_ SG_ 296 AVL_BRTORQ_WHL_FS_LH_EXT "Current wheel-related friction braking torque of the DSC control unit. 
A negative braking torque corresponds to friction force against the vehicle movement.
Fixed Value = 0";
CM_ SG_ 296 AVL_BRTORQ_WHL_FS_RH_EXT "Current wheel-related friction braking torque of the DSC control unit. 
A negative braking torque corresponds to friction force against the vehicle movement.
Fixed Value = 0";
CM_ SG_ 296 CHL_EXTS_ARB_INTF "This signal explicitly contains the value of the extension ID = 4 (dec) = 4 (hex) for the extended CRC validation according to Autosar_SWS_E2ELibrary profile 1C.
FÝxed Value = 0";
CM_ SG_ 296 CHL_RQ_RPM_FTAX "This signal explicitly contains the value of the extension ID = 7 (dec) = 7 (hex) for the extended CRC validation according to Autosar_SWS_E2ELibrary profile 1C.
Fixed Value = 7";
CM_ SG_ 296 CRC_RQ_RPM_BAX "This signal contains the CRC checksum for the extended standard application CRC validation according to application profile 1C E2E Protection (Autosar SWS 428). 
The application data ID (12 bit) 1584 (dec) = 630 (hex) is assigned to the signal. ";
CM_ SG_ 296 ALIV_EXTS_ARB_INTF "Standard alive counter validation as per definition in the requirements specification Allgemeine Bordnetzkommunikation.";
CM_ SG_ 296 CRC_EXTS_ARB_INTF "This signal contains the CRC checksum for the extended standard application CRC validation according to application profile 1C E2E Protection (AutoSar SWS 428).
The application data ID (12 Bit) 1192 (dec) = 4A8 (hex) is assigned to the signal.";
CM_ SG_ 296 ALIV_RQ_RPM_BAX "Standard alive counter validation as per definition in the requirements specification Allgemeine Bordnetzkommunikation.";
CM_ SG_ 296 CHL_RQ_RPM_BAX "This signal explicitly contains the value of the extension ID = 6 (dec) = 6 (hex) for the extended CRC validation according to Autosar_SWS_E2ELibrary profile 1C.
Fixed Value = 6";
CM_ SG_ 296 TAR_RPM_MAX_BAX "Maximum wheel speed at the rear axle.
The wheel speed of the rear axle is the mean value of the wheel speed rear left and the wheel speed rear right.
Fixed Value = 40000";
CM_ SG_ 296 TAR_RPM_MIN_BAX "Minimum wheel speed at the rear axle.
Fixed Value = 0";
CM_ SG_ 296 ST_TAR_RPM_BAX "With this status, the limits to the minimum and maximum wheel speed limit for the rear axle can be activated or deactivated.
Fixed Value = 0";
CM_ SG_ 296 TAR_STIF_SPCO "Standardized value for the regulator stiffness. Valid for all speed regulators on the EA side.
Fixed Value = 5";
CM_ SG_ 296 CRC_RQ_RPM_FTAX "This signal contains the CRC checksum for the extended standard application CRC validation according to application profile 1C E2E Protection (Autosar SWS 428). The application data ID (12 bit) 1839 (dec) = 72F (hex) is assigned to the signal.";
CM_ SG_ 296 AVL_BRTORQ_WHL_RS_RH_EXT "Current wheel-related friction braking torque of the DSC control unit. 
A negative braking torque corresponds to friction force against the vehicle movement.
Fixed Value = 0";
CM_ SG_ 296 AVL_BRTORQ_WHL_RS_LH_EXT "Current wheel-related friction braking torque of the DSC control unit. 
A negative braking torque corresponds to friction force against the vehicle movement.";
CM_ BO_ 297 "-";
CM_ SG_ 297 CRC_ACLNX_COG "Standard application CRC validation 
This signal uses the application CRC ID = 29 (dec)";
CM_ SG_ 297 CRC_ACLNY_COG "Standard application CRC validation 
This signal uses the application CRC ID = 31 (dec)";
CM_ SG_ 297 ACLNY_COG "Lateral acceleration in the vehicle's center of gravity.";
CM_ SG_ 297 QU_ACLNY_COG "Extended status qualifier for the signal Querbeschleunigung_Schwerpunkt.
Fixed Value = 3";
CM_ SG_ 297 QU_ACLNX_COG "Extended status qualifier for the signal Längsbeschleunigung_Schwerpunkt.
Fixed Value = 3";
CM_ SG_ 297 ACLNX_COG "Longitudinal acceleration in the vehicle's center of gravity.";
CM_ BO_ 314 "-";
CM_ SG_ 314 StatusETractSys1Degradation "Actual derating status of electric machine system 1.
Invalid value = 4294967295";
CM_ SG_ 314 ALIV_TracEMacElectc1Time100msNo1 "Standard protection alive counter as defined in the on-board data communication requirements specification.";
CM_ SG_ 314 TETractSys1InverterActVal "Actual temperature of the inverter of electric machine system 1.";
CM_ SG_ 314 TETractSys1EmStatorActVal "Actual temperature of the electric motor of electric machine system 1.";
CM_ SG_ 314 ThermalStressLevelETractSys1 "Consolidated standardized temperature of the electric machine system 1 that is used as thermal utilization for the strategic degradation and ABK display.";
CM_ SG_ 314 TETractSys1EmRotorActVal "Current absolute temperature of the rotor of the electric machine in electric machine system 1.";
CM_ SG_ 314 StatusExtraBoostETractSys1 "Actual ExtraBoost status in electric machine system 1.";
CM_ SG_ 314 PercentUsedExtraBoostETractSys1 "Electric machine system 1 communicates a damage signal as a percentage.  The percentage of total possible power mode service life that is consumed is transmitted.";
CM_ SG_ 314 TETractSys1GbxOilActVal "Actual oil temperature of the internal transmission of electric machine system 1.";
CM_ SG_ 314 WhlRatElAxlEtractSys1ActVal "Overall ratio (transmission and differential gear) on the electrical axle driven by electric machine system 1.";
CM_ SG_ 314 StatusETractSys1LossActive "Actual trimming status of electric machine system 1.";
CM_ SG_ 314 OpModETractSys1ActVal "Actual operating mode of electric machine system 1
The event-based portion does not have to be sent by TEE1.";
CM_ SG_ 314 StatusETractSys1CoolingActVal "Thermal utilization status of electric machine system 1 that is used by thermal management to calculate the coolant request.";
CM_ SG_ 314 TETractSys1CoolantWaterInpActVal "Actual coolant temperature at the outlet of the cooling circuit of electric machine system 1.";
CM_ SG_ 314 ActStatMeclLossesGbxETractSys1 "Mechanical power loss of the integrated transmission in electric traction system 1.";
CM_ SG_ 314 StatusETractSys1Error "Actual error status of electric machine system 1.

Bit 17, bitrange 19 - 22 and 25 - 31 are being used for test- and debugging reasons and are not being documented in the message catalogue.";
CM_ SG_ 314 PowerETractSys1MaximumLossActive "Maximum possible power loss of electric machine system 1.";
CM_ SG_ 314 CRC_TracEMacElectc1Time100msNo1 "This signal contains the CRC checksum for the extended standard protection with application CRC according to application profile 5 E2E Autosar protection.

The signal uses the application data ID (16 bit) 25(dez) = 0019 (hex).";
CM_ BO_ 326 "-";
CM_ SG_ 326 CRC_TracEMacElectc2Time100msNo1 "This signal contains the CRC checksum for the extended standard protection with application CRC according to application profile 5 E2E Autosar protection.

The signal uses the application data ID (16 bit) 26(dez) = 001A (hex).";
CM_ SG_ 326 StatusETractSys2Degradation "Actual derating status of electric machine system 2.
Invalid value = 4294967295";
CM_ SG_ 326 ALIV_TracEMacElectc2Time100msNo1 "Standard protection alive counter as defined in the on-board data communication requirements specification.";
CM_ SG_ 326 StatusETractSys2Error "Actual error status of electric machine system 2.

Bit 17, bitrange 19 - 22 and 25 - 31 are being used for test- and debugging reasons and are not being documented in the message catalogue.
Invalid value = 4294967295";
CM_ SG_ 326 ActStatMeclLossesGbxETractSys2 "Mechanical power loss of the integrated transmission in electric traction system 2.";
CM_ SG_ 326 TETractSys2CoolantWaterInpActVal "Actual coolant temperature at the outlet of the cooling circuit of electric machine system 2.";
CM_ SG_ 326 OpModETractSys2ActVal "Actual operating mode of electric machin system 2
The event-based portion does not have to be sent by TEE2.";
CM_ SG_ 326 StatusETractSys2LossActive "Actual trimming status of electric machine system 2.";
CM_ SG_ 326 PowerETractSys2MaximumLossActive "Maximum possible power loss of electric machine system 2.";
CM_ SG_ 326 WhlRatElAxlEtractSys2ActVal "Overall ratio (transmission and differential gear) on the electrical axle driven by electric machine system 2.";
CM_ SG_ 326 PercentUsedExtraBoostETractSys2 "Electric machine system 2 communicates a damage signal as a percentage.  The percentage of total possible power mode service life that is consumed is transmitted. ";
CM_ SG_ 326 StatusETractSys2CoolingActVal "Thermal utilization status of electric machine system 2 that is used by thermal management to calculate the coolant request.";
CM_ SG_ 326 TETractSys2EmRotorActVal "Current absolute temperature of the rotor of the electric machine in electric machine system 2.";
CM_ SG_ 326 ThermalStressLevelETractSys2 "Consolidated standardized temperature of electric machine system 2 that is used as thermal utilization for the strategic degradation and ABK display.";
CM_ SG_ 326 TETractSys2EmStatorActVal "Actual temperature of the electric motor of electric machine system 2.";
CM_ SG_ 326 TETractSys2InverterActVal "Actual temperature of the inverter of electric machine system 2.";
CM_ SG_ 326 TETractSys2GbxOilActVal "Actual oil temperature of the internal transmission of electric machine system 2.";
CM_ SG_ 326 StatusExtraBoostETractSys2 "Actual ExtraBoost status in electric machine system 2.";
CM_ BO_ 385 "-";
CM_ SG_ 385 VCU_BMS_ActCoolingSts "Signal from VCU that inform that the active cooling was already turned ON";
CM_ SG_ 385 VCU_BMS_HeatingSts "Signal from VCU that inform that the heating was already turned ON";
CM_ SG_ 385 CRC_VCU_BMS_ThermalStatus "Checksum";
CM_ SG_ 385 ALV_VCU_BMS_ThermalStatus "Alive Counter";
CM_ BO_ 389 "-";
CM_ SG_ 389 CRC_BMS_CellTemp "Checksum";
CM_ SG_ 389 ALV_BMS_CellTemp "Alive Counter";
CM_ SG_ 389 BMS_MinCellTemp "Min Cell Temperature ";
CM_ SG_ 389 BMS_PackTemp "Pack Temperature ";
CM_ SG_ 389 BMS_MaxCellTemp "Max Cell Temperature ";
CM_ SG_ 389 BMS_ProbeNumMaxCellTemp "Probe Number Of Max Cell Temperature ";
CM_ SG_ 389 BMS_ProbeNumMinCellTemp "Probe Number Of Min Cell Temperature ";
CM_ SG_ 389 BMS_MaxMinDiffCellTemp "Max And Min Cell Temperature Differences ";
CM_ BO_ 394 "-";
CM_ SG_ 394 BMS_CellTemp41 "Cell temperature of sensor 36";
CM_ SG_ 394 BMS_CellTemp40 "Cell temperature of sensor 36";
CM_ SG_ 394 BMS_CellTemp39 "Cell temperature of sensor 36";
CM_ SG_ 394 BMS_CellTemp38 "Cell temperature of sensor 36";
CM_ SG_ 394 BMS_CellTemp37 "Cell temperature of sensor 36";
CM_ SG_ 394 BMS_CellTemp8 "Cell temperature of sensor 8";
CM_ SG_ 394 BMS_CellTemp6 "Cell temperature of sensor 6";
CM_ SG_ 394 BMS_CellTemp7 "Cell temperature of sensor 7";
CM_ SG_ 394 BMS_CellTemp5 "Cell temperature of sensor 5";
CM_ SG_ 394 ALV_BMS_CellTempMeas "Alive counter";
CM_ SG_ 394 BMS_CellTemp2 "Cell temperature of sensor 2";
CM_ SG_ 394 BMS_CellTemp1 "Cell temperature of sensor 1";
CM_ SG_ 394 CRC_BMS_CellTempMeas "Checksum";
CM_ SG_ 394 BMS_CellTemp9 "Cell temperature of sensor 9";
CM_ SG_ 394 BMS_CellTemp4 "Cell temperature of sensor 4";
CM_ SG_ 394 BMS_CellTemp10 "Cell temperature of sensor 10";
CM_ SG_ 394 BMS_CellTemp3 "Cell temperature of sensor 3";
CM_ SG_ 394 BMS_CellTemp12 "Cell temperature of sensor 12";
CM_ SG_ 394 BMS_CellTemp11 "Cell temperature of sensor 11";
CM_ SG_ 394 BMS_CellTemp36 "Cell temperature of sensor 36";
CM_ SG_ 394 BMS_CellTemp35 "Cell temperature of sensor 35";
CM_ SG_ 394 BMS_CellTemp34 "Cell temperature of sensor 34";
CM_ SG_ 394 BMS_CellTemp33 "Cell temperature of sensor 33";
CM_ SG_ 394 BMS_CellTemp32 "Cell temperature of sensor 32";
CM_ SG_ 394 BMS_CellTemp31 "Cell temperature of sensor 31";
CM_ SG_ 394 BMS_CellTemp30 "Cell temperature of sensor 30";
CM_ SG_ 394 BMS_CellTemp28 "Cell temperature of sensor 28";
CM_ SG_ 394 BMS_CellTemp27 "Cell temperature of sensor 27";
CM_ SG_ 394 BMS_CellTemp26 "Cell temperature of sensor 26";
CM_ SG_ 394 BMS_CellTemp25 "Cell temperature of sensor 25";
CM_ SG_ 394 BMS_CellTemp24 "Cell temperature of sensor 24";
CM_ SG_ 394 BMS_CellTemp29 "Cell temperature of sensor 29";
CM_ SG_ 394 BMS_CellTemp22 "Cell temperature of sensor 22";
CM_ SG_ 394 BMS_CellTemp13 "Cell temperature of sensor 13";
CM_ SG_ 394 BMS_CellTemp23 "Cell temperature of sensor 23";
CM_ SG_ 394 BMS_CellTemp15 "Cell temperature of sensor 15";
CM_ SG_ 394 BMS_CellTemp16 "Cell temperature of sensor 16";
CM_ SG_ 394 BMS_CellTemp17 "Cell temperature of sensor 17";
CM_ SG_ 394 BMS_CellTemp18 "Cell temperature of sensor 18";
CM_ SG_ 394 BMS_CellTemp14 "Cell temperature of sensor 14";
CM_ SG_ 394 BMS_CellTemp19 "Cell temperature of sensor 19";
CM_ SG_ 394 BMS_CellTemp20 "Cell temperature of sensor 20";
CM_ SG_ 394 BMS_CellTemp21 "Cell temperature of sensor 21";
CM_ BO_ 399 "-";
CM_ SG_ 399 BMS_CellVol18 "Voltage of cell 18
Invalid Value = 5.115V";
CM_ SG_ 399 BMS_CellVol19 "Voltage of cell 19
Invalid Value = 5.115V";
CM_ SG_ 399 BMS_CellVol20 "Voltage of cell 20
Invalid Value = 5.115V";
CM_ SG_ 399 BMS_CellVol21 "Voltage of cell 21
Invalid Value = 5.115V";
CM_ SG_ 399 BMS_CellVol22 "Voltage of cell 22
Invalid Value = 5.115V";
CM_ SG_ 399 BMS_CellVol23 "Voltage of cell 23
Invalid Value = 5.115V";
CM_ SG_ 399 BMS_CellVol24 "Voltage of cell 24
Invalid Value = 5.115V";
CM_ SG_ 399 BMS_CellVol25 "Voltage of cell 25
Invalid Value = 5.115V";
CM_ SG_ 399 BMS_CellVol26 "Voltage of cell 26
Invalid Value = 5.115V";
CM_ SG_ 399 BMS_CellVol28 "Voltage of cell 28
Invalid Value = 5.115V";
CM_ SG_ 399 BMS_CellVol17 "Voltage of cell 17
Invalid Value = 5.115V";
CM_ SG_ 399 BMS_CellVol27 "Voltage of cell 27
Invalid Value = 5.115V";
CM_ SG_ 399 BMS_CellVol29 "Voltage of cell 29
Invalid Value = 5.115V";
CM_ SG_ 399 BMS_CellVol16 "Voltage of cell 16
Invalid Value = 5.115V";
CM_ SG_ 399 CRC_BMS_CellVolMeas "Checksum";
CM_ SG_ 399 BMS_CellVol14 "Voltage of cell 14
Invalid Value = 5.115V";
CM_ SG_ 399 BMS_CellVol13 "Voltage of cell 13
Invalid Value = 5.115V";
CM_ SG_ 399 BMS_CellVol8 "Voltage of cell 8
Invalid Value = 5.115V";
CM_ SG_ 399 BMS_CellVol7 "Voltage of cell 7
Invalid Value = 5.115V";
CM_ SG_ 399 BMS_CellVol6 "Voltage of cell 6
Invalid Value = 5.115V";
CM_ SG_ 399 BMS_CellVol5 "Voltage of cell 5
Invalid Value = 5.115V";
CM_ SG_ 399 BMS_CellVol4 "Voltage of cell 4
Invalid Value = 5.115V";
CM_ SG_ 399 BMS_CellVol3 "Voltage of cell 3
Invalid Value = 5.115V";
CM_ SG_ 399 BMS_CellVol2 "Voltage of cell 2
Invalid Value = 5.115V";
CM_ SG_ 399 BMS_CellVol1 "Voltage of cell 1
Invalid Value = 5.115V";
CM_ SG_ 399 ALV_BMS_CellVolMeas "Alive counter";
CM_ SG_ 399 BMS_CellVol12 "Voltage of cell 12
Invalid Value = 5.115V
";
CM_ SG_ 399 BMS_CellVol11 "Voltage of cell 11
Invalid Value = 5.115V";
CM_ SG_ 399 BMS_CellVol30 "Voltage of cell 30
Invalid Value = 5.115V";
CM_ SG_ 399 BMS_CellVol15 "Voltage of cell 15
Invalid Value = 5.115V";
CM_ SG_ 399 BMS_CellVol9 "Voltage of cell 9
Invalid Value = 5.115V";
CM_ SG_ 399 BMS_CellVol10 "Voltage of cell 10
Invalid Value = 5.115V";
CM_ BO_ 404 "-";
CM_ SG_ 404 BMS_CellVol56 "Voltage of cell 56
Invalid Value = 5.115V";
CM_ SG_ 404 BMS_CellVol38 "Voltage of cell 38
Invalid Value = 5.115V";
CM_ SG_ 404 BMS_CellVol37 "Voltage of cell 37
Invalid Value = 5.115V";
CM_ SG_ 404 BMS_CellVol36 "Voltage of cell 36
Invalid Value = 5.115V";
CM_ SG_ 404 BMS_CellVol35 "Voltage of cell 35
Invalid Value = 5.115V";
CM_ SG_ 404 BMS_CellVol34 "Voltage of cell 34
Invalid Value = 5.115V";
CM_ SG_ 404 BMS_CellVol33 "Voltage of cell 33
Invalid Value = 5.115V";
CM_ SG_ 404 BMS_CellVol32 "Voltage of cell 32
Invalid Value = 5.115V";
CM_ SG_ 404 BMS_CellVol31 "Voltage of cell 31
Invalid Value = 5.115V";
CM_ SG_ 404 ALV_BMS_CellVolMeas2 "Alive counter";
CM_ SG_ 404 CRC_BMS_CellVolMeas2 "Checksum";
CM_ SG_ 404 BMS_CellVol59 "Voltage of cell 59
Invalid Value = 5.115V";
CM_ SG_ 404 BMS_CellVol60 "Voltage of cell 60
Invalid Value = 5.115V";
CM_ SG_ 404 BMS_CellVol61 "Voltage of cell 61
Invalid Value = 5.115V";
CM_ SG_ 404 BMS_CellVol62 "Voltage of cell 62
Invalid Value = 5.115V";
CM_ SG_ 404 BMS_CellVol57 "Voltage of cell 57
Invalid Value = 5.115V";
CM_ SG_ 404 BMS_CellVol39 "Voltage of cell 39
Invalid Value = 5.115V";
CM_ SG_ 404 BMS_CellVol40 "Voltage of cell 40
Invalid Value = 5.115V";
CM_ SG_ 404 BMS_CellVol42 "Voltage of cell 42
Invalid Value = 5.115V";
CM_ SG_ 404 BMS_CellVol49 "Voltage of cell 49
Invalid Value = 5.115V";
CM_ SG_ 404 BMS_CellVol53 "Voltage of cell 53
Invalid Value = 5.115V";
CM_ SG_ 404 BMS_CellVol52 "Voltage of cell 52
Invalid Value = 5.115V";
CM_ SG_ 404 BMS_CellVol51 "Voltage of cell 51
Invalid Value = 5.115V";
CM_ SG_ 404 BMS_CellVol50 "Voltage of cell 50
Invalid Value = 5.115V";
CM_ SG_ 404 BMS_CellVol48 "Voltage of cell 48
Invalid Value = 5.115V";
CM_ SG_ 404 BMS_CellVol46 "Voltage of cell 46
Invalid Value = 5.115V";
CM_ SG_ 404 BMS_CellVol47 "Voltage of cell 47
Invalid Value = 5.115V";
CM_ SG_ 404 BMS_CellVol44 "Voltage of cell 44
Invalid Value = 5.115V";
CM_ SG_ 404 BMS_CellVol43 "Voltage of cell 43
Invalid Value = 5.115V";
CM_ SG_ 404 BMS_CellVol58 "Voltage of cell 58
Invalid Value = 5.115V";
CM_ SG_ 404 BMS_CellVol41 "Voltage of cell 41
Invalid Value = 5.115V";
CM_ SG_ 404 BMS_CellVol55 "Voltage of cell 55
Invalid Value = 5.115V";
CM_ SG_ 404 BMS_CellVol45 "Voltage of cell 45
Invalid Value = 5.115V";
CM_ SG_ 404 BMS_CellVol54 "Voltage of cell 54
Invalid Value = 5.115V";
CM_ BO_ 405 "-";
CM_ SG_ 405 OBC_VCU_iDC "OBC measured output current on OBC output";
CM_ SG_ 405 OBC_VCU_vAC_L2 "OBC measured voltage on AC input phase L3";
CM_ SG_ 405 OBC_VCU_vAC_L1 "OBC measured voltage on AC input phase L1";
CM_ SG_ 405 OBC_VCU_iAC_L3 "OBC measured current on AC input phase L3";
CM_ SG_ 405 OBC_VCU_vDC "OBC measured bus voltage at OBC output";
CM_ SG_ 405 OBC_VCU_vAC_L3 "OBC measured voltage on AC input phase L2";
CM_ SG_ 405 OBC_VCU_iAC_L1 "OBC measured current on AC input phase L1";
CM_ SG_ 405 OBC_Max_Current_Out "Maximum current OBC can output";
CM_ SG_ 405 OBC_VCU_Status "Current status of OBC";
CM_ SG_ 405 OBC_VCU_iAC_L2 "OBC measured current on AC input phase L2";
CM_ BO_ 409 "-";
CM_ SG_ 409 BMS_CellVol82 "Voltage of cell 82
Invalid Value = 5.115V";
CM_ SG_ 409 BMS_CellVol86 "Voltage of cell 86
Invalid Value = 5.115V";
CM_ SG_ 409 BMS_CellVol83 "Voltage of cell 83
Invalid Value = 5.115V";
CM_ SG_ 409 BMS_CellVol84 "Voltage of cell 84
Invalid Value = 5.115V";
CM_ SG_ 409 BMS_CellVol87 "Voltage of cell 87
Invalid Value = 5.115V";
CM_ SG_ 409 BMS_CellVol94 "Voltage of cell 94
Invalid Value = 5.115V";
CM_ SG_ 409 BMS_CellVol89 "Voltage of cell 89
Invalid Value = 5.115V";
CM_ SG_ 409 BMS_CellVol90 "Voltage of cell 90
Invalid Value = 5.115V";
CM_ SG_ 409 BMS_CellVol91 "Voltage of cell 91
Invalid Value = 5.115V";
CM_ SG_ 409 BMS_CellVol92 "Voltage of cell 92
Invalid Value = 5.115V";
CM_ SG_ 409 BMS_CellVol93 "Voltage of cell 93
Invalid Value = 5.115V";
CM_ SG_ 409 BMS_CellVol81 "Voltage of cell 81
Invalid Value = 5.115V";
CM_ SG_ 409 BMS_CellVol88 "Voltage of cell 88
Invalid Value = 5.115V";
CM_ SG_ 409 BMS_CellVol80 "Voltage of cell 80
Invalid Value = 5.115V";
CM_ SG_ 409 BMS_CellVol85 "Voltage of cell 85
Invalid Value = 5.115V";
CM_ SG_ 409 BMS_CellVol78 "Voltage of cell 78
Invalid Value = 5.115V";
CM_ SG_ 409 BMS_CellVol70 "Voltage of cell 70
Invalid Value = 5.115V";
CM_ SG_ 409 BMS_CellVol67 "Voltage of cell 67
Invalid Value = 5.115V";
CM_ SG_ 409 BMS_CellVol79 "Voltage of cell 79
Invalid Value = 5.115V";
CM_ SG_ 409 BMS_CellVol66 "Voltage of cell 66
Invalid Value = 5.115V";
CM_ SG_ 409 BMS_CellVol65 "Voltage of cell 65
Invalid Value = 5.115V";
CM_ SG_ 409 BMS_CellVol64 "Voltage of cell 64
Invalid Value = 5.115V";
CM_ SG_ 409 BMS_CellVol63 "Voltage of cell 63
Invalid Value = 5.115V";
CM_ SG_ 409 ALV_BMS_CellVolMeas3 "Alive counter";
CM_ SG_ 409 BMS_CellVol69 "Voltage of cell 69
Invalid Value = 5.115V";
CM_ SG_ 409 CRC_BMS_CellVolMeas3 "Checksum";
CM_ SG_ 409 BMS_CellVol71 "Voltage of cell 71
Invalid Value = 5.115V";
CM_ SG_ 409 BMS_CellVol68 "Voltage of cell 68
Invalid Value = 5.115V";
CM_ SG_ 409 BMS_CellVol73 "Voltage of cell 73
Invalid Value = 5.115V";
CM_ SG_ 409 BMS_CellVol75 "Voltage of cell 75
Invalid Value = 5.115V";
CM_ SG_ 409 BMS_CellVol72 "Voltage of cell 72
Invalid Value = 5.115V";
CM_ SG_ 409 BMS_CellVol77 "Voltage of cell 77
Invalid Value = 5.115V";
CM_ SG_ 409 BMS_CellVol74 "Voltage of cell 74
Invalid Value = 5.115V";
CM_ SG_ 409 BMS_CellVol76 "Voltage of cell 76
Invalid Value = 5.115V";
CM_ SG_ 409 BMS_CellVol100 "Voltage of cell 100
Invalid Value = 5.115V";
CM_ SG_ 409 BMS_CellVol101 "Voltage of cell 101
Invalid Value = 5.115V";
CM_ SG_ 409 BMS_CellVol102 "Voltage of cell 102
Invalid Value = 5.115V";
CM_ SG_ 409 BMS_CellVol103 "Voltage of cell 103
Invalid Value = 5.115V";
CM_ SG_ 409 BMS_CellVol104 "Voltage of cell 104
Invalid Value = 5.115V";
CM_ SG_ 409 BMS_CellVol105 "Voltage of cell 105
Invalid Value = 5.115V";
CM_ SG_ 409 BMS_CellVol106 "Voltage of cell 106
Invalid Value = 5.115V";
CM_ SG_ 409 BMS_CellVol107 "Voltage of cell 107
Invalid Value = 5.115V";
CM_ SG_ 409 BMS_CellVol108 "Voltage of cell 108
Invalid Value = 5.115V";
CM_ BO_ 193 "-";
CM_ SG_ 193 VCU_ChgDirType "Charging Direction Type (Charging or Discharging)";
CM_ SG_ 193 VCU_OBC_iOBC_Request "OBC current output requested by VCU";
CM_ SG_ 193 VCU_OBC_vOBC_Request "OBC voltage output requested by VCU";
CM_ SG_ 193 VCU_OBC_Enable "Requests OBC to turn on by VCU";
CM_ SG_ 193 VCU_OBC_iLineLimit "AC line current limit";
CM_ BO_ 414 "-";
CM_ SG_ 414 BMS_CoolantOutletTemp "Temperature of Battery Coolant Outlet";
CM_ SG_ 414 BMS_CoolantInletTemp "Temperature of Battery Coolant Inlet";
CM_ SG_ 414 ALV_BMS_CoolantInletOutletTmp "Alive counter";
CM_ SG_ 414 CRC_BMS_CoolantInletOutletTmp "Checksum";
CM_ BO_ 418 "-";
CM_ SG_ 418 VCU_TargetASOC "Target SOC for charging.";
CM_ SG_ 418 ALV_VCU_BMS_ChargingParams "Alive Counter";
CM_ SG_ 418 CRC_VCU_BMS_ChargingParams "Checksum";
CM_ BO_ 419 "-";
CM_ SG_ 419 BMS_PackInsuRes "Minimum value of BCU_PosInsuRes and BCU_NegInsuRes";
CM_ SG_ 419 BMS_VCU_InsulationMonSts "Feedback for the Insulation Monitoring signal ";
CM_ SG_ 419 ALV_BMS_Insulation "Alive counter";
CM_ SG_ 419 CRC_BMS_Insulation "Checksum";
CM_ BO_ 420 "-";
CM_ SG_ 420 ALV_VCU_BMS_ChargingControl "Alive Counter";
CM_ SG_ 420 VCU_BMS_InsulationMonReq "Can Message To Turn On/Off The Ýnsulation Resistance Measurement";
CM_ SG_ 420 CRC_VCU_BMS_ChargingControl "Checksum";
CM_ SG_ 420 VCU_BMS_ChargeAllow "The Flag Of Vcu Allows Bms Charging";
CM_ BO_ 424 "-";
CM_ SG_ 424 BMS_VCU_HeatingOnOffReq "Heating on and off request ";
CM_ SG_ 424 BMS_VCU_CoolingOnOffReq "Cooling on and off request";
CM_ SG_ 424 BMS_HeatPwrDemand "Requesting The Heating Power Required For The Battery Pack ";
CM_ SG_ 424 BMS_FlowRateReq "Flow Rate Required";
CM_ SG_ 424 ALV_BMS_VCU_THMReq "Alive Counter";
CM_ SG_ 424 CRC_BMS_VCU_THMReq "Checksum";
CM_ SG_ 424 BMS_CoolPwrDemand "Requesting The Cooling Power Required For The Battery Pack ";
CM_ BO_ 429 "-";
CM_ SG_ 429 BMS_MaxCellVol "Max Cell Voltage of the complete pack";
CM_ SG_ 429 BMS_MinCellVol "Min Cell Voltage of the complete pack";
CM_ SG_ 429 BMS_CellNumMaxCellVol "Cell Number of Max Cell Voltage ";
CM_ SG_ 429 BMS_CellNumMinCellVol "Cell Number of Min Cell Voltage ";
CM_ SG_ 429 ALV_BMS_VolMeas "Alive counter";
CM_ SG_ 429 CRC_BMS_VolMeas "Checksum";
CM_ SG_ 429 BMS_MaxMinDiffCellVol "Max and min cell voltage differences";
CM_ BO_ 433 "-";
CM_ SG_ 433 VCU_BMS_HVOnOffReq "Bms Decides Whether To Close Or Disconnect The Primary And Negative Relays By Judging This Command";
CM_ SG_ 433 ALV_VCU_BMS_HVCoordination "Alive Counter";
CM_ SG_ 433 CRC_VCU_BMS_HVCoordination "Checksum";
CM_ BO_ 450 "-";
CM_ SG_ 450 DCDC_InternalTempC "Reported DCDC internal temperature";
CM_ SG_ 450 DCDC_InternalTempB "Reported DCDC internal temperature";
CM_ SG_ 450 DCDC_CoolPwrDemand "Cooling Power requested by DCDC";
CM_ SG_ 450 DCDC_FlowRateReq "Flow rate required for DCDC
";
CM_ SG_ 450 DCDC_InternalTempA "Reported DCDC internal temperature";
CM_ BO_ 490 "-";
CM_ SG_ 490 MILE_KM_TOT "Using this signal, the odometer is sent. 
Invalid value= 4294967.295";
CM_ BO_ 197 "-";
CM_ SG_ 197 VCU_EnableDCDC "Enable request";
CM_ BO_ 517 "-";
CM_ SG_ 517 CRC_BMS_HistData "Checksum";
CM_ SG_ 517 BMS_ContactorAging "Aging Condition Of Contactors : Pre-Charge && Positive && Negative Contactors";
CM_ SG_ 517 ALV_BMS_HistData "Alive Counter";
CM_ BO_ 532 "-";
CM_ SG_ 532 CRC_ParkByWire50msNo1 "This signal contains the CRC for the extended standard app CRC validation according to app profile 1C E2E Protection (SWS 428). The signal uses application data ID (12 bit) 2727 (dec) = AA7 (hex). The application CRC ID consists of two parts";
CM_ SG_ 532 ALIV_ParkByWire50msNo1 "Standard alive counter validation as per definition in the requirements specification Allgemeine Bordnetzkommunikation.";
CM_ SG_ 532 CHL_ParkByWire50msNo1 "This signal explicitly contains the value of the extension ID = 10 (dec) = A (hex) for the extended standard validation application CRC and corresponds to bit 8-11 of the application data ID (CRC ID) from CRC_ParkByWire50msNo1.
Fixed Value = 10";
CM_ SG_ 532 RequestParkByWireHeat "Parking lock request";
CM_ BO_ 630 "-";
CM_ SG_ 630 ST_ENERG_FZM "The Status_Energie_FZM (ST_ENERG_FZM) signal is calculated from the Status_Energie_Powermanagement (ST_ENERG_PWMG) signal.
Fixed Value = 1";
CM_ SG_ 630 ST_ILK_ERRM_FZM "Fixed Value = 0";
CM_ BO_ 632 "-";
CM_ SG_ 632 ST_TRAI "This parameter / signal indicates if a trailer is really connected or not.
Fixed Value = 0";
CM_ BO_ 645 "-";
CM_ SG_ 645 OBC_CoolPwrDemand "Cooling Power requested by OBC
Invalid Value = 25.5";
CM_ SG_ 645 OBC_FlowRateReq "Flow rate required for OBC";
CM_ SG_ 645 OBC_InternalTemp "Reported OBC internal temperature";
CM_ BO_ 749 "-";
CM_ SG_ 749 TEMP_EX "Here the processed (= filtered) ambient temperature is made available to all other bus subscribers.";
CM_ BO_ 811 "-";
CM_ SG_ 811 ActValVolFlowCoolantETractSys1 "Current coolant flow of the E-machine system 1.
Fixed Value = 600";
CM_ SG_ 811 ActValVolFlowCoolantETractSys2 "Current coolant flow of the E-machine system 2.
Fixed Value = 600";
CM_ BO_ 832 "-";
CM_ SG_ 832 ALIV_CombinedChargerUnit100msNo1 "Standard alive counter validation as per definition in the requirements specification Allgemeine Bordnetzkommunikation.";
CM_ SG_ 832 RequestPowerETractSys1Loss "Minimum power loss requested by electric machine system 1 (trimming).
Fixed Value = 0";
CM_ SG_ 832 CRC_CombinedChargerUnit100msNo1 "This signal contains the CRC for the standard validation with application CRC-16 (E2E profile 5) according to the definition in requirements specification Bordnetzkommunikation. 
The signal uses application data ID (16 bits) 118 (dec) = 0076 (hex).";
CM_ SG_ 832 RequestPowerETractSys2Loss "Minimum power loss requested by electric machine system 2 (trimming).
Fixed Value = 0";
CM_ BO_ 896 "-";
CM_ SG_ 896 NO_VECH_7 "This signal contains the seventh to last digit of the vehicle identification number. (The individual digits are coded in ASCII characters.)
Bit 0: LSB, Bit 7: MSB
Fixed Value = 48";
CM_ SG_ 896 NO_VECH_6 "This signal contains the seventh to last digit of the vehicle identification number. (The individual digits are coded in ASCII characters.)
Bit 0: LSB, Bit 7: MSB
Fixed Value = 48";
CM_ SG_ 896 NO_VECH_5 "This signal contains the seventh to last digit of the vehicle identification number. (The individual digits are coded in ASCII characters.)
Bit 0: LSB, Bit 7: MSB
Fixed Value = 48";
CM_ SG_ 896 NO_VECH_4 "This signal contains the seventh to last digit of the vehicle identification number. (The individual digits are coded in ASCII characters.)
Bit 0: LSB, Bit 7: MSB
Fixed Value = 48";
CM_ SG_ 896 NO_VECH_1 "This signal contains the seventh to last digit of the vehicle identification number. (The individual digits are coded in ASCII characters.)
Bit 0: LSB, Bit 7: MSB
Fixed Value = 48";
CM_ SG_ 896 NO_VECH_2 "This signal contains the seventh to last digit of the vehicle identification number. (The individual digits are coded in ASCII characters.)
Bit 0: LSB, Bit 7: MSB
Fixed Value = 48";
CM_ SG_ 896 NO_VECH_3 "This signal contains the seventh to last digit of the vehicle identification number. (The individual digits are coded in ASCII characters.)
Bit 0: LSB, Bit 7: MSB
Fixed Value = 48";
CM_ BO_ 911 "-";
CM_ SG_ 911 QU_AVL_LOGR_RW "Extended status qualifier for the signal Ist_Längsneigung_Fahrbahn.
Fixed Value = 2";
CM_ SG_ 911 CRC_TLT_RW "This signal uses the application CRC ID = 53 (dec)";
CM_ SG_ 911 AVL_LOGR_RW "Estimated longitudinal incline of the driving surface. This value is determined based on driving-dynamic measurands using a vehicle model.
Fixed Value = 0
Invalid value = 140.75";
CM_ BO_ 1052 "-";
CM_ SG_ 1052 MILE_KM "The indicated value of the odometer is made available to other nodes.
Fixed Value = 0";
CM_ BO_ 1090 "-";
CM_ SG_ 1090 T_SEC_COU_REL "This counter counts the seconds synchronously with the system / vehicle clock.
Invalid value = 4294967295
";
CM_ BO_ 1107 "-";
CM_ SG_ 1107 StsDisconnectingSwtHighVoltStorg "Status of the disconnecting elements in the high voltage battery incl. status for the stuck welded contactor.";
CM_ SG_ 1107 StatusServiceDisconnectionPlug "Status of the service disconnector: plugged in or not plugged in
Fixed Value = 2";
CM_ BO_ 1120 "-";
CM_ SG_ 1120 EnergyStorageClamp30VoltageValue "Current voltage of low voltage battery for use in the OBD range (Kl30 voltage).";
CM_ BO_ 1237 "-";
CM_ SG_ 1237 TempETractSys1DirectCurrentPlug "Current temperature of the connecting wire of electric machine 1.";
CM_ SG_ 1237 StatusCrashShutDownETractSys1 "Applies to differential crash signal C+/C hardware interface";
CM_ SG_ 1237 CHL_StatusCrashIdentETractSys1 "This signal explicitly contains the value of the extension ID = 12 (dec) = C (hex) for the extended CRC validation according to Autosar_SWS_E2ELibrary profile 1C.
Fixed Value = 12";
CM_ SG_ 1237 ALIV_StatusCrashIdentETractSys1 "Standard alive counter validation as per definition in the requirements specification Allgemeine Bordnetzkommunikation.";
CM_ SG_ 1237 CRC_StatusCrashIdentETractSys1 "This signal contains the CRC checksum for the extended standard application CRC validation according to application profile 1C E2E Protection (AutoSar SWS 428).
The application data ID (12 bits) 3242 (dec) = CAA (hex) is assigned to the signal.";
CM_ SG_ 1237 StsLimpHomeNotifETractSys1 "Status of the presence of an LimpHomeMode-relevant CCM in electric machine system 1.";
CM_ BO_ 1239 "-";
CM_ SG_ 1239 ALIV_StatusCrashIdentETractSys2 "Standard alive counter validation as per definition in the requirements specification Allgemeine Bordnetzkommunikation.";
CM_ SG_ 1239 CHL_StatusCrashIdentETractSys2 "This signal explicitly contains the value of the extension ID = 12 (dec) = C (hex) for the extended CRC validation according to Autosar_SWS_E2ELibrary profile 1C.
Fixed Value = 12";
CM_ SG_ 1239 StatusCrashShutDownETractSys2 "Applies to differential crash signal C+/C hardware interface";
CM_ SG_ 1239 TempETractSys2DirectCurrentPlug "Current temperature of the connecting wire of electric machine 2.";
CM_ SG_ 1239 StsLimpHomeNotifETractSys2 "Status of the presence of an eNotlauf-relevant CCM in electric machine system 2.";
CM_ SG_ 1239 CRC_StatusCrashIdentETractSys2 "This signal contains the CRC checksum for the extended standard application CRC validation according to application profile 1C E2E Protection (AutoSar SWS 428).
The application data ID (12 bits) 3241 (dec) = CA9 (hex) is assigned to the signal.";
CM_ BO_ 1272 "-";
CM_ SG_ 1272 TemperatureCoolantOutput "The signal contains the coolant temperature at the radiator outlet (sensor S5 measured on VCU).";
CM_ BO_ 1296 "-";
CM_ SG_ 1296 NM3ControlBitVector "Using this signal, the control bit vector specified in AUTOSAR NM is transmitted. For BMW, only bit 6 (Partial Network Information Bit) is relevant; all other bits shall be set to 0.";
CM_ SG_ 1296 NM3SenderECUId "This signal contains the diagnostic address of the sending electronic control unit (Source Node Identifier).";
CM_ SG_ 1296 NM3BasePartialNetworks "In the AUTOSAR system template, the signals NM3BasePartialNetworks and NM3FunctionalPartialNetworks are extracted as a signal of six bytes in size.";
CM_ SG_ 1296 NM3FunctionalPartialNetworks "
In the AUTOSAR system template, the signals NM3BasePartialNetworks and NM3FunctionalPartialNetworks are extracted as a signal of six bytes in size.";
CM_ BO_ 1562 "-";
CM_ SG_ 1562 OBC_DiagResp_Byte1 "Diagnostic signal Data response";
CM_ SG_ 1562 OBC_DiagResp_Byte5 "Diagnostic signal Data response";
CM_ SG_ 1562 OBC_DiagResp_Byte4 "Diagnostic signal Data response";
CM_ SG_ 1562 OBC_DiagResp_Byte3 "Diagnostic signal Data response";
CM_ SG_ 1562 OBC_DiagResp_Byte2 "Diagnostic signal Data response";
CM_ SG_ 1562 OBC_DiagResp_Byte0 "Diagnostic signal Data response";
CM_ SG_ 1562 OBC_DiagResp_Byte7 "Diagnostic signal Data response";
CM_ SG_ 1562 OBC_DiagResp_Byte6 "Diagnostic signal Data response";
CM_ BO_ 1669 "Diagnostic signal Data response";
CM_ SG_ 1669 VCU_DiagResp_Byte1 "Diagnostic signal Data response";
CM_ SG_ 1669 VCU_DiagResp_Byte5 "Diagnostic signal Data response";
CM_ SG_ 1669 VCU_DiagResp_Byte4 "Diagnostic signal Data response";
CM_ SG_ 1669 VCU_DiagResp_Byte3 "Diagnostic signal Data response";
CM_ SG_ 1669 VCU_DiagResp_Byte2 "Diagnostic signal Data response";
CM_ SG_ 1669 VCU_DiagResp_Byte0 "Diagnostic signal Data response";
CM_ SG_ 1669 VCU_DiagResp_Byte7 "Diagnostic signal Data response";
CM_ SG_ 1669 VCU_DiagResp_Byte6 "Diagnostic signal Data response";
CM_ BO_ 1585 "-";
CM_ SG_ 1585 DCDC_DiagResp_Byte7 "Diagnostic signal Data response";
CM_ SG_ 1585 DCDC_DiagResp_Byte5 "Diagnostic signal Data response";
CM_ SG_ 1585 DCDC_DiagResp_Byte4 "Diagnostic signal Data response";
CM_ SG_ 1585 DCDC_DiagResp_Byte3 "Diagnostic signal Data response";
CM_ SG_ 1585 DCDC_DiagResp_Byte2 "Diagnostic signal Data response";
CM_ SG_ 1585 DCDC_DiagResp_Byte1 "Diagnostic signal Data response";
CM_ SG_ 1585 DCDC_DiagResp_Byte0 "Diagnostic signal Data response";
CM_ SG_ 1585 DCDC_DiagResp_Byte6 "Diagnostic signal Data response";
CM_ BO_ 1690 "-";
CM_ SG_ 1690 OBC_DiagReq_Byte0 "Diagnostic signal Data request";
CM_ SG_ 1690 OBC_DiagReq_Byte1 "Diagnostic signal Data request";
CM_ SG_ 1690 OBC_DiagReq_Byte2 "Diagnostic signal Data request";
CM_ SG_ 1690 OBC_DiagReq_Byte3 "Diagnostic signal Data request";
CM_ SG_ 1690 OBC_DiagReq_Byte4 "Diagnostic signal Data request";
CM_ SG_ 1690 OBC_DiagReq_Byte5 "Diagnostic signal Data request";
CM_ SG_ 1690 OBC_DiagReq_Byte6 "Diagnostic signal Data request";
CM_ SG_ 1690 OBC_DiagReq_Byte7 "Diagnostic signal Data request";
CM_ BO_ 1668 "Diagnostic signal Data request";
CM_ SG_ 1668 VCU_DiagReq_Byte0 "Diagnostic signal Data request";
CM_ SG_ 1668 VCU_DiagReq_Byte1 "Diagnostic signal Data request";
CM_ SG_ 1668 VCU_DiagReq_Byte2 "Diagnostic signal Data request";
CM_ SG_ 1668 VCU_DiagReq_Byte3 "Diagnostic signal Data request";
CM_ SG_ 1668 VCU_DiagReq_Byte4 "Diagnostic signal Data request";
CM_ SG_ 1668 VCU_DiagReq_Byte5 "Diagnostic signal Data request";
CM_ SG_ 1668 VCU_DiagReq_Byte6 "Diagnostic signal Data request";
CM_ SG_ 1668 VCU_DiagReq_Byte7 "Diagnostic signal Data request";
CM_ BO_ 1713 "-";
CM_ SG_ 1713 DCDC_DiagReq_Byte7 "Diagnostic signal Data request";
CM_ SG_ 1713 DCDC_DiagReq_Byte6 "Diagnostic signal Data request";
CM_ SG_ 1713 DCDC_DiagReq_Byte5 "Diagnostic signal Data request";
CM_ SG_ 1713 DCDC_DiagReq_Byte0 "Diagnostic signal Data request";
CM_ SG_ 1713 DCDC_DiagReq_Byte3 "Diagnostic signal Data request";
CM_ SG_ 1713 DCDC_DiagReq_Byte2 "Diagnostic signal Data request";
CM_ SG_ 1713 DCDC_DiagReq_Byte4 "Diagnostic signal Data request";
CM_ SG_ 1713 DCDC_DiagReq_Byte1 "Diagnostic signal Data request";
BA_DEF_ SG_  "SigFixedValue" STRING ;
BA_DEF_ BO_  "GenMsgNrOfRepetition" INT 0 0;
BA_DEF_ BO_  "GenMsgILSupport" ENUM  "No","Yes";
BA_DEF_ BO_  "VFrameFormat" ENUM  "StandardCAN","ExtendedCAN","reserved","reserved","reserved","reserved","reserved","reserved","reserved","reserved","reserved","reserved","reserved","reserved","StandardCAN_FD","ExtendedCAN_FD";
BA_DEF_ BO_  "GenMsgSendType" ENUM  "Cyclic","NotUsed","NotUsed","NotUsed","NotUsed","NotUsed","NotUsed","IfActive","NoMsgSendType","NotUsed";
BA_DEF_ SG_  "GenSigSendType" ENUM  "Cyclic","OnWrite","OnWriteWithCyclic","OnChange","OnChangeWithCyclic","IfActive","IfActiveWithCyclic","NoSigSendType";
BA_DEF_ BO_  "GenMsgCycleTime" INT 0 0;
BA_DEF_ BO_  "GenMsgCycleTimeFast" INT 0 100000;
BA_DEF_ BO_  "DiagResponse" ENUM  "No","Yes";
BA_DEF_ BO_  "DiagRequest" ENUM  "No","Yes";
BA_DEF_ SG_  "CycleTime" INT 0 0;
BA_DEF_ SG_  "GenSigTimeoutTime" INT 0 0;
BA_DEF_ SG_  "InvalidValue" INT 0 2147483647;
BA_DEF_ SG_  "GenSigStartValue" INT 0 0;
BA_DEF_DEF_  "SigFixedValue" "NoFixedValue";
BA_DEF_DEF_  "GenMsgNrOfRepetition" 0;
BA_DEF_DEF_  "GenMsgILSupport" "Yes";
BA_DEF_DEF_  "VFrameFormat" "StandardCAN";
BA_DEF_DEF_  "GenMsgSendType" "NoMsgSendType";
BA_DEF_DEF_  "GenSigSendType" "Cyclic";
BA_DEF_DEF_  "GenMsgCycleTime" 0;
BA_DEF_DEF_  "GenMsgCycleTimeFast" 0;
BA_DEF_DEF_  "DiagResponse" "No";
BA_DEF_DEF_  "DiagRequest" "No";
BA_DEF_DEF_  "CycleTime" 0;
BA_DEF_DEF_  "GenSigTimeoutTime" 0;
BA_DEF_DEF_  "InvalidValue" 0;
BA_DEF_DEF_  "GenSigStartValue" 0;
BA_ "GenMsgCycleTime" BO_ 293 10;
BA_ "GenMsgSendType" BO_ 293 0;
BA_ "VFrameFormat" BO_ 293 14;
BA_ "GenMsgCycleTime" BO_ 296 10;
BA_ "GenMsgSendType" BO_ 296 0;
BA_ "VFrameFormat" BO_ 296 14;
BA_ "GenMsgCycleTime" BO_ 297 20;
BA_ "GenMsgSendType" BO_ 297 0;
BA_ "VFrameFormat" BO_ 297 14;
BA_ "GenMsgCycleTime" BO_ 314 100;
BA_ "GenMsgSendType" BO_ 314 0;
BA_ "VFrameFormat" BO_ 314 14;
BA_ "GenMsgCycleTime" BO_ 326 100;
BA_ "GenMsgSendType" BO_ 326 0;
BA_ "VFrameFormat" BO_ 326 14;
BA_ "GenMsgCycleTime" BO_ 385 100;
BA_ "GenMsgSendType" BO_ 385 0;
BA_ "VFrameFormat" BO_ 385 14;
BA_ "GenMsgCycleTime" BO_ 389 100;
BA_ "GenMsgSendType" BO_ 389 0;
BA_ "VFrameFormat" BO_ 389 14;
BA_ "GenMsgCycleTime" BO_ 394 100;
BA_ "GenMsgSendType" BO_ 394 0;
BA_ "VFrameFormat" BO_ 394 14;
BA_ "GenMsgCycleTime" BO_ 399 100;
BA_ "GenMsgSendType" BO_ 399 0;
BA_ "VFrameFormat" BO_ 399 14;
BA_ "GenMsgCycleTime" BO_ 404 100;
BA_ "GenMsgSendType" BO_ 404 0;
BA_ "VFrameFormat" BO_ 404 14;
BA_ "GenMsgCycleTime" BO_ 405 100;
BA_ "GenMsgSendType" BO_ 405 0;
BA_ "VFrameFormat" BO_ 405 14;
BA_ "GenMsgCycleTime" BO_ 409 100;
BA_ "GenMsgSendType" BO_ 409 0;
BA_ "VFrameFormat" BO_ 409 14;
BA_ "GenMsgCycleTime" BO_ 193 10;
BA_ "GenMsgSendType" BO_ 193 0;
BA_ "VFrameFormat" BO_ 193 14;
BA_ "GenMsgCycleTime" BO_ 414 100;
BA_ "GenMsgSendType" BO_ 414 0;
BA_ "VFrameFormat" BO_ 414 14;
BA_ "GenMsgCycleTime" BO_ 418 100;
BA_ "GenMsgSendType" BO_ 418 0;
BA_ "VFrameFormat" BO_ 418 14;
BA_ "GenMsgCycleTime" BO_ 419 100;
BA_ "GenMsgSendType" BO_ 419 0;
BA_ "VFrameFormat" BO_ 419 14;
BA_ "GenMsgCycleTime" BO_ 420 100;
BA_ "GenMsgSendType" BO_ 420 0;
BA_ "VFrameFormat" BO_ 420 14;
BA_ "GenMsgCycleTime" BO_ 424 100;
BA_ "GenMsgSendType" BO_ 424 0;
BA_ "VFrameFormat" BO_ 424 14;
BA_ "GenMsgCycleTime" BO_ 429 100;
BA_ "GenMsgSendType" BO_ 429 0;
BA_ "VFrameFormat" BO_ 429 14;
BA_ "GenMsgCycleTime" BO_ 433 100;
BA_ "GenMsgSendType" BO_ 433 0;
BA_ "VFrameFormat" BO_ 433 14;
BA_ "GenMsgCycleTime" BO_ 450 100;
BA_ "GenMsgSendType" BO_ 450 0;
BA_ "VFrameFormat" BO_ 450 14;
BA_ "GenMsgCycleTime" BO_ 490 300;
BA_ "GenMsgSendType" BO_ 490 0;
BA_ "VFrameFormat" BO_ 490 14;
BA_ "GenMsgCycleTime" BO_ 197 10;
BA_ "GenMsgSendType" BO_ 197 0;
BA_ "VFrameFormat" BO_ 197 14;
BA_ "GenMsgCycleTime" BO_ 517 200;
BA_ "GenMsgSendType" BO_ 517 0;
BA_ "VFrameFormat" BO_ 517 14;
BA_ "GenMsgCycleTime" BO_ 532 50;
BA_ "GenMsgSendType" BO_ 532 0;
BA_ "VFrameFormat" BO_ 532 14;
BA_ "GenMsgCycleTime" BO_ 630 5000;
BA_ "GenMsgSendType" BO_ 630 0;
BA_ "VFrameFormat" BO_ 630 14;
BA_ "GenMsgCycleTime" BO_ 632 5000;
BA_ "GenMsgSendType" BO_ 632 0;
BA_ "VFrameFormat" BO_ 632 14;
BA_ "GenMsgCycleTime" BO_ 645 500;
BA_ "GenMsgSendType" BO_ 645 0;
BA_ "VFrameFormat" BO_ 645 14;
BA_ "GenMsgCycleTime" BO_ 749 1000;
BA_ "GenMsgSendType" BO_ 749 0;
BA_ "VFrameFormat" BO_ 749 14;
BA_ "GenMsgCycleTime" BO_ 811 100;
BA_ "GenMsgSendType" BO_ 811 0;
BA_ "VFrameFormat" BO_ 811 14;
BA_ "GenMsgCycleTime" BO_ 832 100;
BA_ "GenMsgSendType" BO_ 832 0;
BA_ "VFrameFormat" BO_ 832 14;
BA_ "GenMsgCycleTimeFast" BO_ 896 100;
BA_ "GenMsgNrOfRepetition" BO_ 896 1;
BA_ "VFrameFormat" BO_ 896 14;
BA_ "GenMsgCycleTime" BO_ 911 100;
BA_ "GenMsgSendType" BO_ 911 0;
BA_ "VFrameFormat" BO_ 911 14;
BA_ "GenMsgCycleTime" BO_ 1052 10000;
BA_ "GenMsgSendType" BO_ 1052 0;
BA_ "VFrameFormat" BO_ 1052 14;
BA_ "GenMsgCycleTime" BO_ 1090 1000;
BA_ "GenMsgSendType" BO_ 1090 0;
BA_ "VFrameFormat" BO_ 1090 14;
BA_ "GenMsgCycleTime" BO_ 1107 200;
BA_ "GenMsgSendType" BO_ 1107 0;
BA_ "VFrameFormat" BO_ 1107 14;
BA_ "GenMsgCycleTime" BO_ 1120 200;
BA_ "GenMsgSendType" BO_ 1120 0;
BA_ "VFrameFormat" BO_ 1120 14;
BA_ "GenMsgCycleTime" BO_ 1237 1000;
BA_ "GenMsgSendType" BO_ 1237 0;
BA_ "VFrameFormat" BO_ 1237 14;
BA_ "GenMsgCycleTime" BO_ 1239 1000;
BA_ "GenMsgSendType" BO_ 1239 0;
BA_ "VFrameFormat" BO_ 1239 14;
BA_ "GenMsgCycleTime" BO_ 1272 1000;
BA_ "GenMsgSendType" BO_ 1272 0;
BA_ "VFrameFormat" BO_ 1272 14;
BA_ "GenMsgCycleTime" BO_ 1296 100;
BA_ "GenMsgSendType" BO_ 1296 0;
BA_ "VFrameFormat" BO_ 1296 14;
BA_ "DiagResponse" BO_ 1562 1;
BA_ "VFrameFormat" BO_ 1562 14;
BA_ "DiagResponse" BO_ 1669 1;
BA_ "VFrameFormat" BO_ 1669 14;
BA_ "DiagResponse" BO_ 1585 1;
BA_ "VFrameFormat" BO_ 1585 14;
BA_ "DiagRequest" BO_ 1690 1;
BA_ "VFrameFormat" BO_ 1690 14;
BA_ "DiagRequest" BO_ 1668 1;
BA_ "VFrameFormat" BO_ 1668 14;
BA_ "GenMsgCycleTime" BO_ 1156 100;
BA_ "GenMsgSendType" BO_ 1156 0;
BA_ "VFrameFormat" BO_ 1156 14;
BA_ "GenMsgCycleTime" BO_ 1160 100;
BA_ "GenMsgSendType" BO_ 1160 0;
BA_ "VFrameFormat" BO_ 1160 14;
BA_ "DiagRequest" BO_ 1713 1;
BA_ "VFrameFormat" BO_ 1713 14;
BA_ "CycleTime" SG_ 293 PowerETractSys1LimMotMax 10;
BA_ "GenSigTimeoutTime" SG_ 293 PowerETractSys1LimMotMax 50;
BA_ "InvalidValue" SG_ 293 PowerETractSys1LimMotMax 65535;
BA_ "GenSigStartValue" SG_ 293 PowerETractSys1LimMotMax 65535;
BA_ "SigFixedValue" SG_ 293 PowerETractSys1LimMotMax "1638300";
BA_ "CycleTime" SG_ 293 PowerETractSys1LimGenMax 10;
BA_ "GenSigTimeoutTime" SG_ 293 PowerETractSys1LimGenMax 50;
BA_ "InvalidValue" SG_ 293 PowerETractSys1LimGenMax 65535;
BA_ "GenSigStartValue" SG_ 293 PowerETractSys1LimGenMax 65535;
BA_ "SigFixedValue" SG_ 293 PowerETractSys1LimGenMax "-1638300";
BA_ "CycleTime" SG_ 293 PowerETractSys2LimGenMax 10;
BA_ "GenSigTimeoutTime" SG_ 293 PowerETractSys2LimGenMax 50;
BA_ "InvalidValue" SG_ 293 PowerETractSys2LimGenMax 65535;
BA_ "GenSigStartValue" SG_ 293 PowerETractSys2LimGenMax 65535;
BA_ "SigFixedValue" SG_ 293 PowerETractSys2LimGenMax "-1638300";
BA_ "CycleTime" SG_ 293 OperatingModeEANActualValue 10;
BA_ "GenSigTimeoutTime" SG_ 293 OperatingModeEANActualValue 50;
BA_ "InvalidValue" SG_ 293 OperatingModeEANActualValue 255;
BA_ "CycleTime" SG_ 293 PowerETractSys2LimMotMax 10;
BA_ "GenSigTimeoutTime" SG_ 293 PowerETractSys2LimMotMax 50;
BA_ "InvalidValue" SG_ 293 PowerETractSys2LimMotMax 65535;
BA_ "GenSigStartValue" SG_ 293 PowerETractSys2LimMotMax 65535;
BA_ "SigFixedValue" SG_ 293 PowerETractSys2LimMotMax "1638300";
BA_ "SigFixedValue" SG_ 293 RequestExtraBoostETractSys2 "0";
BA_ "CycleTime" SG_ 293 RequestExtraBoostETractSys2 10;
BA_ "GenSigTimeoutTime" SG_ 293 RequestExtraBoostETractSys2 50;
BA_ "InvalidValue" SG_ 293 RequestExtraBoostETractSys2 3;
BA_ "GenSigStartValue" SG_ 293 RequestExtraBoostETractSys2 3;
BA_ "SigFixedValue" SG_ 293 RequestExtraBoostETractSys1 "0";
BA_ "CycleTime" SG_ 293 RequestExtraBoostETractSys1 10;
BA_ "GenSigTimeoutTime" SG_ 293 RequestExtraBoostETractSys1 50;
BA_ "InvalidValue" SG_ 293 RequestExtraBoostETractSys1 3;
BA_ "GenSigStartValue" SG_ 293 RequestExtraBoostETractSys1 3;
BA_ "SigFixedValue" SG_ 296 TAR_RPM_MAX_FTAX "400";
BA_ "CycleTime" SG_ 296 TAR_RPM_MAX_FTAX 10;
BA_ "GenSigTimeoutTime" SG_ 296 TAR_RPM_MAX_FTAX 50;
BA_ "InvalidValue" SG_ 296 TAR_RPM_MAX_FTAX 65535;
BA_ "GenSigStartValue" SG_ 296 TAR_RPM_MAX_FTAX 65535;
BA_ "SigFixedValue" SG_ 296 TAR_RPM_MIN_FTAX "0";
BA_ "CycleTime" SG_ 296 TAR_RPM_MIN_FTAX 10;
BA_ "GenSigTimeoutTime" SG_ 296 TAR_RPM_MIN_FTAX 50;
BA_ "InvalidValue" SG_ 296 TAR_RPM_MIN_FTAX 65535;
BA_ "GenSigStartValue" SG_ 296 TAR_RPM_MIN_FTAX 65535;
BA_ "SigFixedValue" SG_ 296 ST_TAR_RPM_FTAX "0";
BA_ "CycleTime" SG_ 296 ST_TAR_RPM_FTAX 10;
BA_ "GenSigTimeoutTime" SG_ 296 ST_TAR_RPM_FTAX 50;
BA_ "InvalidValue" SG_ 296 ST_TAR_RPM_FTAX 15;
BA_ "GenSigStartValue" SG_ 296 ST_TAR_RPM_FTAX 15;
BA_ "CycleTime" SG_ 296 CRC_StatusSlipThresholds 10;
BA_ "GenSigTimeoutTime" SG_ 296 CRC_StatusSlipThresholds 50;
BA_ "InvalidValue" SG_ 296 CRC_StatusSlipThresholds 255;
BA_ "GenSigStartValue" SG_ 296 CRC_StatusSlipThresholds 255;
BA_ "SigFixedValue" SG_ 296 CHL_StatusSlipThresholds "3";
BA_ "CycleTime" SG_ 296 CHL_StatusSlipThresholds 10;
BA_ "GenSigTimeoutTime" SG_ 296 CHL_StatusSlipThresholds 50;
BA_ "InvalidValue" SG_ 296 CHL_StatusSlipThresholds 15;
BA_ "GenSigStartValue" SG_ 296 CHL_StatusSlipThresholds 15;
BA_ "SigFixedValue" SG_ 296 StatusSlipThresholdsFrontAxle "0";
BA_ "CycleTime" SG_ 296 StatusSlipThresholdsFrontAxle 10;
BA_ "GenSigTimeoutTime" SG_ 296 StatusSlipThresholdsFrontAxle 50;
BA_ "InvalidValue" SG_ 296 StatusSlipThresholdsFrontAxle 15;
BA_ "GenSigStartValue" SG_ 296 StatusSlipThresholdsFrontAxle 15;
BA_ "SigFixedValue" SG_ 296 StatusSlipThresholdsRearAxle "0";
BA_ "CycleTime" SG_ 296 StatusSlipThresholdsRearAxle 10;
BA_ "GenSigTimeoutTime" SG_ 296 StatusSlipThresholdsRearAxle 50;
BA_ "InvalidValue" SG_ 296 StatusSlipThresholdsRearAxle 15;
BA_ "GenSigStartValue" SG_ 296 StatusSlipThresholdsRearAxle 15;
BA_ "CycleTime" SG_ 296 ALIV_StatusSlipThresholds 10;
BA_ "GenSigTimeoutTime" SG_ 296 ALIV_StatusSlipThresholds 50;
BA_ "InvalidValue" SG_ 296 ALIV_StatusSlipThresholds 15;
BA_ "CycleTime" SG_ 296 ALIV_RQ_RPM_FTAX 10;
BA_ "GenSigTimeoutTime" SG_ 296 ALIV_RQ_RPM_FTAX 50;
BA_ "InvalidValue" SG_ 296 ALIV_RQ_RPM_FTAX 15;
BA_ "SigFixedValue" SG_ 296 AVL_BRTORQ_WHL_FS_LH_EXT "0";
BA_ "CycleTime" SG_ 296 AVL_BRTORQ_WHL_FS_LH_EXT 10;
BA_ "GenSigTimeoutTime" SG_ 296 AVL_BRTORQ_WHL_FS_LH_EXT 50;
BA_ "InvalidValue" SG_ 296 AVL_BRTORQ_WHL_FS_LH_EXT 65535;
BA_ "GenSigStartValue" SG_ 296 AVL_BRTORQ_WHL_FS_LH_EXT 65535;
BA_ "SigFixedValue" SG_ 296 AVL_BRTORQ_WHL_FS_RH_EXT "0";
BA_ "CycleTime" SG_ 296 AVL_BRTORQ_WHL_FS_RH_EXT 10;
BA_ "GenSigTimeoutTime" SG_ 296 AVL_BRTORQ_WHL_FS_RH_EXT 50;
BA_ "InvalidValue" SG_ 296 AVL_BRTORQ_WHL_FS_RH_EXT 65535;
BA_ "GenSigStartValue" SG_ 296 AVL_BRTORQ_WHL_FS_RH_EXT 65535;
BA_ "SigFixedValue" SG_ 296 CHL_EXTS_ARB_INTF "0";
BA_ "CycleTime" SG_ 296 CHL_EXTS_ARB_INTF 10;
BA_ "GenSigTimeoutTime" SG_ 296 CHL_EXTS_ARB_INTF 50;
BA_ "InvalidValue" SG_ 296 CHL_EXTS_ARB_INTF 15;
BA_ "GenSigStartValue" SG_ 296 CHL_EXTS_ARB_INTF 15;
BA_ "SigFixedValue" SG_ 296 CHL_RQ_RPM_FTAX "7";
BA_ "CycleTime" SG_ 296 CHL_RQ_RPM_FTAX 10;
BA_ "GenSigTimeoutTime" SG_ 296 CHL_RQ_RPM_FTAX 50;
BA_ "InvalidValue" SG_ 296 CHL_RQ_RPM_FTAX 15;
BA_ "GenSigStartValue" SG_ 296 CHL_RQ_RPM_FTAX 15;
BA_ "CycleTime" SG_ 296 CRC_RQ_RPM_BAX 10;
BA_ "GenSigTimeoutTime" SG_ 296 CRC_RQ_RPM_BAX 50;
BA_ "InvalidValue" SG_ 296 CRC_RQ_RPM_BAX 255;
BA_ "GenSigStartValue" SG_ 296 CRC_RQ_RPM_BAX 255;
BA_ "CycleTime" SG_ 296 ALIV_EXTS_ARB_INTF 10;
BA_ "GenSigTimeoutTime" SG_ 296 ALIV_EXTS_ARB_INTF 50;
BA_ "InvalidValue" SG_ 296 ALIV_EXTS_ARB_INTF 15;
BA_ "SigFixedValue" SG_ 296 CRC_EXTS_ARB_INTF "0";
BA_ "CycleTime" SG_ 296 CRC_EXTS_ARB_INTF 10;
BA_ "GenSigTimeoutTime" SG_ 296 CRC_EXTS_ARB_INTF 50;
BA_ "InvalidValue" SG_ 296 CRC_EXTS_ARB_INTF 255;
BA_ "GenSigStartValue" SG_ 296 CRC_EXTS_ARB_INTF 255;
BA_ "CycleTime" SG_ 296 ALIV_RQ_RPM_BAX 10;
BA_ "GenSigTimeoutTime" SG_ 296 ALIV_RQ_RPM_BAX 50;
BA_ "InvalidValue" SG_ 296 ALIV_RQ_RPM_BAX 15;
BA_ "SigFixedValue" SG_ 296 CHL_RQ_RPM_BAX "6";
BA_ "CycleTime" SG_ 296 CHL_RQ_RPM_BAX 10;
BA_ "GenSigTimeoutTime" SG_ 296 CHL_RQ_RPM_BAX 50;
BA_ "InvalidValue" SG_ 296 CHL_RQ_RPM_BAX 15;
BA_ "GenSigStartValue" SG_ 296 CHL_RQ_RPM_BAX 15;
BA_ "SigFixedValue" SG_ 296 TAR_RPM_MAX_BAX "400";
BA_ "CycleTime" SG_ 296 TAR_RPM_MAX_BAX 10;
BA_ "GenSigTimeoutTime" SG_ 296 TAR_RPM_MAX_BAX 50;
BA_ "InvalidValue" SG_ 296 TAR_RPM_MAX_BAX 65535;
BA_ "GenSigStartValue" SG_ 296 TAR_RPM_MAX_BAX 65535;
BA_ "SigFixedValue" SG_ 296 TAR_RPM_MIN_BAX "0";
BA_ "CycleTime" SG_ 296 TAR_RPM_MIN_BAX 10;
BA_ "GenSigTimeoutTime" SG_ 296 TAR_RPM_MIN_BAX 50;
BA_ "InvalidValue" SG_ 296 TAR_RPM_MIN_BAX 65535;
BA_ "GenSigStartValue" SG_ 296 TAR_RPM_MIN_BAX 65535;
BA_ "SigFixedValue" SG_ 296 ST_TAR_RPM_BAX "0";
BA_ "CycleTime" SG_ 296 ST_TAR_RPM_BAX 10;
BA_ "GenSigTimeoutTime" SG_ 296 ST_TAR_RPM_BAX 50;
BA_ "InvalidValue" SG_ 296 ST_TAR_RPM_BAX 15;
BA_ "GenSigStartValue" SG_ 296 ST_TAR_RPM_BAX 15;
BA_ "SigFixedValue" SG_ 296 TAR_STIF_SPCO "5";
BA_ "CycleTime" SG_ 296 TAR_STIF_SPCO 10;
BA_ "GenSigTimeoutTime" SG_ 296 TAR_STIF_SPCO 50;
BA_ "InvalidValue" SG_ 296 TAR_STIF_SPCO 15;
BA_ "GenSigStartValue" SG_ 296 TAR_STIF_SPCO 15;
BA_ "CycleTime" SG_ 296 CRC_RQ_RPM_FTAX 10;
BA_ "GenSigTimeoutTime" SG_ 296 CRC_RQ_RPM_FTAX 50;
BA_ "InvalidValue" SG_ 296 CRC_RQ_RPM_FTAX 255;
BA_ "GenSigStartValue" SG_ 296 CRC_RQ_RPM_FTAX 255;
BA_ "SigFixedValue" SG_ 296 AVL_BRTORQ_WHL_RS_RH_EXT "0";
BA_ "CycleTime" SG_ 296 AVL_BRTORQ_WHL_RS_RH_EXT 10;
BA_ "GenSigTimeoutTime" SG_ 296 AVL_BRTORQ_WHL_RS_RH_EXT 50;
BA_ "InvalidValue" SG_ 296 AVL_BRTORQ_WHL_RS_RH_EXT 65535;
BA_ "GenSigStartValue" SG_ 296 AVL_BRTORQ_WHL_RS_RH_EXT 65535;
BA_ "CycleTime" SG_ 296 AVL_BRTORQ_WHL_RS_LH_EXT 10;
BA_ "GenSigTimeoutTime" SG_ 296 AVL_BRTORQ_WHL_RS_LH_EXT 50;
BA_ "InvalidValue" SG_ 296 AVL_BRTORQ_WHL_RS_LH_EXT 65535;
BA_ "GenSigStartValue" SG_ 296 AVL_BRTORQ_WHL_RS_LH_EXT 65535;
BA_ "CycleTime" SG_ 297 CRC_ACLNX_COG 20;
BA_ "GenSigTimeoutTime" SG_ 297 CRC_ACLNX_COG 100;
BA_ "InvalidValue" SG_ 297 CRC_ACLNX_COG 255;
BA_ "GenSigStartValue" SG_ 297 CRC_ACLNX_COG 255;
BA_ "CycleTime" SG_ 297 ALIV_ACLNY_COG 20;
BA_ "GenSigTimeoutTime" SG_ 297 ALIV_ACLNY_COG 100;
BA_ "InvalidValue" SG_ 297 ALIV_ACLNY_COG 15;
BA_ "CycleTime" SG_ 297 CRC_ACLNY_COG 20;
BA_ "GenSigTimeoutTime" SG_ 297 CRC_ACLNY_COG 100;
BA_ "InvalidValue" SG_ 297 CRC_ACLNY_COG 255;
BA_ "GenSigStartValue" SG_ 297 CRC_ACLNY_COG 255;
BA_ "CycleTime" SG_ 297 ACLNY_COG 20;
BA_ "GenSigTimeoutTime" SG_ 297 ACLNY_COG 100;
BA_ "InvalidValue" SG_ 297 ACLNY_COG 65535;
BA_ "GenSigStartValue" SG_ 297 ACLNY_COG 65000;
BA_ "SigFixedValue" SG_ 297 QU_ACLNY_COG "3";
BA_ "CycleTime" SG_ 297 QU_ACLNY_COG 20;
BA_ "GenSigTimeoutTime" SG_ 297 QU_ACLNY_COG 100;
BA_ "InvalidValue" SG_ 297 QU_ACLNY_COG 15;
BA_ "GenSigStartValue" SG_ 297 QU_ACLNY_COG 15;
BA_ "CycleTime" SG_ 297 ALIV_ACLNX_COG 20;
BA_ "GenSigTimeoutTime" SG_ 297 ALIV_ACLNX_COG 100;
BA_ "InvalidValue" SG_ 297 ALIV_ACLNX_COG 15;
BA_ "SigFixedValue" SG_ 297 QU_ACLNX_COG "3";
BA_ "CycleTime" SG_ 297 QU_ACLNX_COG 20;
BA_ "GenSigTimeoutTime" SG_ 297 QU_ACLNX_COG 100;
BA_ "InvalidValue" SG_ 297 QU_ACLNX_COG 15;
BA_ "GenSigStartValue" SG_ 297 QU_ACLNX_COG 15;
BA_ "CycleTime" SG_ 297 ACLNX_COG 20;
BA_ "GenSigTimeoutTime" SG_ 297 ACLNX_COG 100;
BA_ "InvalidValue" SG_ 297 ACLNX_COG 65535;
BA_ "GenSigStartValue" SG_ 297 ACLNX_COG 65000;
BA_ "CycleTime" SG_ 314 StatusETractSys1Degradation 100;
BA_ "GenSigTimeoutTime" SG_ 314 StatusETractSys1Degradation 500;
BA_ "GenSigStartValue" SG_ 314 StatusETractSys1Degradation 4294967295;
BA_ "CycleTime" SG_ 314 ALIV_TracEMacElectc1Time100msNo1 100;
BA_ "GenSigTimeoutTime" SG_ 314 ALIV_TracEMacElectc1Time100msNo1 500;
BA_ "InvalidValue" SG_ 314 ALIV_TracEMacElectc1Time100msNo1 255;
BA_ "CycleTime" SG_ 314 TETractSys1InverterActVal 100;
BA_ "GenSigTimeoutTime" SG_ 314 TETractSys1InverterActVal 500;
BA_ "InvalidValue" SG_ 314 TETractSys1InverterActVal 255;
BA_ "GenSigStartValue" SG_ 314 TETractSys1InverterActVal 255;
BA_ "CycleTime" SG_ 314 TETractSys1EmStatorActVal 100;
BA_ "GenSigTimeoutTime" SG_ 314 TETractSys1EmStatorActVal 500;
BA_ "InvalidValue" SG_ 314 TETractSys1EmStatorActVal 255;
BA_ "GenSigStartValue" SG_ 314 TETractSys1EmStatorActVal 255;
BA_ "CycleTime" SG_ 314 ThermalStressLevelETractSys1 100;
BA_ "GenSigTimeoutTime" SG_ 314 ThermalStressLevelETractSys1 500;
BA_ "InvalidValue" SG_ 314 ThermalStressLevelETractSys1 255;
BA_ "GenSigStartValue" SG_ 314 ThermalStressLevelETractSys1 255;
BA_ "CycleTime" SG_ 314 TETractSys1EmRotorActVal 100;
BA_ "GenSigTimeoutTime" SG_ 314 TETractSys1EmRotorActVal 500;
BA_ "InvalidValue" SG_ 314 TETractSys1EmRotorActVal 255;
BA_ "GenSigStartValue" SG_ 314 TETractSys1EmRotorActVal 255;
BA_ "CycleTime" SG_ 314 StatusExtraBoostETractSys1 100;
BA_ "GenSigTimeoutTime" SG_ 314 StatusExtraBoostETractSys1 500;
BA_ "InvalidValue" SG_ 314 StatusExtraBoostETractSys1 3;
BA_ "GenSigStartValue" SG_ 314 StatusExtraBoostETractSys1 3;
BA_ "CycleTime" SG_ 314 PercentUsedExtraBoostETractSys1 100;
BA_ "GenSigTimeoutTime" SG_ 314 PercentUsedExtraBoostETractSys1 500;
BA_ "InvalidValue" SG_ 314 PercentUsedExtraBoostETractSys1 1023;
BA_ "GenSigStartValue" SG_ 314 PercentUsedExtraBoostETractSys1 1023;
BA_ "CycleTime" SG_ 314 TETractSys1GbxOilActVal 100;
BA_ "GenSigTimeoutTime" SG_ 314 TETractSys1GbxOilActVal 500;
BA_ "InvalidValue" SG_ 314 TETractSys1GbxOilActVal 255;
BA_ "GenSigStartValue" SG_ 314 TETractSys1GbxOilActVal 255;
BA_ "CycleTime" SG_ 314 WhlRatElAxlEtractSys1ActVal 100;
BA_ "GenSigTimeoutTime" SG_ 314 WhlRatElAxlEtractSys1ActVal 500;
BA_ "InvalidValue" SG_ 314 WhlRatElAxlEtractSys1ActVal 65535;
BA_ "GenSigStartValue" SG_ 314 WhlRatElAxlEtractSys1ActVal 65535;
BA_ "CycleTime" SG_ 314 StatusETractSys1LossActive 100;
BA_ "GenSigTimeoutTime" SG_ 314 StatusETractSys1LossActive 500;
BA_ "InvalidValue" SG_ 314 StatusETractSys1LossActive 15;
BA_ "GenSigStartValue" SG_ 314 StatusETractSys1LossActive 15;
BA_ "CycleTime" SG_ 314 OpModETractSys1ActVal 100;
BA_ "GenSigTimeoutTime" SG_ 314 OpModETractSys1ActVal 500;
BA_ "InvalidValue" SG_ 314 OpModETractSys1ActVal 255;
BA_ "GenSigStartValue" SG_ 314 OpModETractSys1ActVal 255;
BA_ "CycleTime" SG_ 314 StatusETractSys1CoolingActVal 100;
BA_ "GenSigTimeoutTime" SG_ 314 StatusETractSys1CoolingActVal 500;
BA_ "InvalidValue" SG_ 314 StatusETractSys1CoolingActVal 15;
BA_ "GenSigStartValue" SG_ 314 StatusETractSys1CoolingActVal 15;
BA_ "CycleTime" SG_ 314 TETractSys1CoolantWaterInpActVal 100;
BA_ "GenSigTimeoutTime" SG_ 314 TETractSys1CoolantWaterInpActVal 500;
BA_ "InvalidValue" SG_ 314 TETractSys1CoolantWaterInpActVal 255;
BA_ "GenSigStartValue" SG_ 314 TETractSys1CoolantWaterInpActVal 255;
BA_ "CycleTime" SG_ 314 ActStatMeclLossesGbxETractSys1 100;
BA_ "GenSigTimeoutTime" SG_ 314 ActStatMeclLossesGbxETractSys1 500;
BA_ "InvalidValue" SG_ 314 ActStatMeclLossesGbxETractSys1 4095;
BA_ "GenSigStartValue" SG_ 314 ActStatMeclLossesGbxETractSys1 4095;
BA_ "CycleTime" SG_ 314 StatusETractSys1Error 100;
BA_ "GenSigTimeoutTime" SG_ 314 StatusETractSys1Error 500;
BA_ "GenSigStartValue" SG_ 314 StatusETractSys1Error 4294967295;
BA_ "CycleTime" SG_ 314 PowerETractSys1MaximumLossActive 100;
BA_ "GenSigTimeoutTime" SG_ 314 PowerETractSys1MaximumLossActive 500;
BA_ "InvalidValue" SG_ 314 PowerETractSys1MaximumLossActive 1023;
BA_ "GenSigStartValue" SG_ 314 PowerETractSys1MaximumLossActive 1023;
BA_ "CycleTime" SG_ 314 CRC_TracEMacElectc1Time100msNo1 100;
BA_ "GenSigTimeoutTime" SG_ 314 CRC_TracEMacElectc1Time100msNo1 500;
BA_ "InvalidValue" SG_ 314 CRC_TracEMacElectc1Time100msNo1 65535;
BA_ "GenSigStartValue" SG_ 314 CRC_TracEMacElectc1Time100msNo1 65535;
BA_ "CycleTime" SG_ 326 CRC_TracEMacElectc2Time100msNo1 100;
BA_ "GenSigTimeoutTime" SG_ 326 CRC_TracEMacElectc2Time100msNo1 500;
BA_ "InvalidValue" SG_ 326 CRC_TracEMacElectc2Time100msNo1 255;
BA_ "GenSigStartValue" SG_ 326 CRC_TracEMacElectc2Time100msNo1 65535;
BA_ "CycleTime" SG_ 326 StatusETractSys2Degradation 100;
BA_ "GenSigTimeoutTime" SG_ 326 StatusETractSys2Degradation 500;
BA_ "GenSigStartValue" SG_ 326 StatusETractSys2Degradation 4294967295;
BA_ "CycleTime" SG_ 326 ALIV_TracEMacElectc2Time100msNo1 100;
BA_ "GenSigTimeoutTime" SG_ 326 ALIV_TracEMacElectc2Time100msNo1 500;
BA_ "InvalidValue" SG_ 326 ALIV_TracEMacElectc2Time100msNo1 255;
BA_ "CycleTime" SG_ 326 StatusETractSys2Error 100;
BA_ "GenSigTimeoutTime" SG_ 326 StatusETractSys2Error 500;
BA_ "GenSigStartValue" SG_ 326 StatusETractSys2Error 4294967295;
BA_ "CycleTime" SG_ 326 ActStatMeclLossesGbxETractSys2 100;
BA_ "GenSigTimeoutTime" SG_ 326 ActStatMeclLossesGbxETractSys2 500;
BA_ "InvalidValue" SG_ 326 ActStatMeclLossesGbxETractSys2 4095;
BA_ "GenSigStartValue" SG_ 326 ActStatMeclLossesGbxETractSys2 4095;
BA_ "CycleTime" SG_ 326 TETractSys2CoolantWaterInpActVal 100;
BA_ "GenSigTimeoutTime" SG_ 326 TETractSys2CoolantWaterInpActVal 500;
BA_ "InvalidValue" SG_ 326 TETractSys2CoolantWaterInpActVal 255;
BA_ "GenSigStartValue" SG_ 326 TETractSys2CoolantWaterInpActVal 255;
BA_ "CycleTime" SG_ 326 OpModETractSys2ActVal 100;
BA_ "GenSigTimeoutTime" SG_ 326 OpModETractSys2ActVal 500;
BA_ "InvalidValue" SG_ 326 OpModETractSys2ActVal 255;
BA_ "GenSigStartValue" SG_ 326 OpModETractSys2ActVal 255;
BA_ "CycleTime" SG_ 326 StatusETractSys2LossActive 100;
BA_ "GenSigTimeoutTime" SG_ 326 StatusETractSys2LossActive 500;
BA_ "InvalidValue" SG_ 326 StatusETractSys2LossActive 15;
BA_ "GenSigStartValue" SG_ 326 StatusETractSys2LossActive 15;
BA_ "CycleTime" SG_ 326 PowerETractSys2MaximumLossActive 100;
BA_ "GenSigTimeoutTime" SG_ 326 PowerETractSys2MaximumLossActive 500;
BA_ "InvalidValue" SG_ 326 PowerETractSys2MaximumLossActive 1023;
BA_ "GenSigStartValue" SG_ 326 PowerETractSys2MaximumLossActive 1023;
BA_ "CycleTime" SG_ 326 WhlRatElAxlEtractSys2ActVal 100;
BA_ "GenSigTimeoutTime" SG_ 326 WhlRatElAxlEtractSys2ActVal 500;
BA_ "InvalidValue" SG_ 326 WhlRatElAxlEtractSys2ActVal 65535;
BA_ "GenSigStartValue" SG_ 326 WhlRatElAxlEtractSys2ActVal 65535;
BA_ "CycleTime" SG_ 326 PercentUsedExtraBoostETractSys2 100;
BA_ "GenSigTimeoutTime" SG_ 326 PercentUsedExtraBoostETractSys2 500;
BA_ "InvalidValue" SG_ 326 PercentUsedExtraBoostETractSys2 1023;
BA_ "GenSigStartValue" SG_ 326 PercentUsedExtraBoostETractSys2 1023;
BA_ "CycleTime" SG_ 326 StatusETractSys2CoolingActVal 100;
BA_ "GenSigTimeoutTime" SG_ 326 StatusETractSys2CoolingActVal 500;
BA_ "InvalidValue" SG_ 326 StatusETractSys2CoolingActVal 15;
BA_ "GenSigStartValue" SG_ 326 StatusETractSys2CoolingActVal 15;
BA_ "CycleTime" SG_ 326 TETractSys2EmRotorActVal 100;
BA_ "GenSigTimeoutTime" SG_ 326 TETractSys2EmRotorActVal 500;
BA_ "InvalidValue" SG_ 326 TETractSys2EmRotorActVal 255;
BA_ "GenSigStartValue" SG_ 326 TETractSys2EmRotorActVal 255;
BA_ "CycleTime" SG_ 326 ThermalStressLevelETractSys2 100;
BA_ "GenSigTimeoutTime" SG_ 326 ThermalStressLevelETractSys2 500;
BA_ "InvalidValue" SG_ 326 ThermalStressLevelETractSys2 255;
BA_ "GenSigStartValue" SG_ 326 ThermalStressLevelETractSys2 255;
BA_ "CycleTime" SG_ 326 TETractSys2EmStatorActVal 100;
BA_ "GenSigTimeoutTime" SG_ 326 TETractSys2EmStatorActVal 500;
BA_ "InvalidValue" SG_ 326 TETractSys2EmStatorActVal 255;
BA_ "GenSigStartValue" SG_ 326 TETractSys2EmStatorActVal 255;
BA_ "CycleTime" SG_ 326 TETractSys2InverterActVal 100;
BA_ "GenSigTimeoutTime" SG_ 326 TETractSys2InverterActVal 500;
BA_ "InvalidValue" SG_ 326 TETractSys2InverterActVal 255;
BA_ "GenSigStartValue" SG_ 326 TETractSys2InverterActVal 255;
BA_ "CycleTime" SG_ 326 TETractSys2GbxOilActVal 100;
BA_ "GenSigTimeoutTime" SG_ 326 TETractSys2GbxOilActVal 500;
BA_ "InvalidValue" SG_ 326 TETractSys2GbxOilActVal 255;
BA_ "GenSigStartValue" SG_ 326 TETractSys2GbxOilActVal 255;
BA_ "CycleTime" SG_ 326 StatusExtraBoostETractSys2 100;
BA_ "GenSigTimeoutTime" SG_ 326 StatusExtraBoostETractSys2 500;
BA_ "InvalidValue" SG_ 326 StatusExtraBoostETractSys2 3;
BA_ "GenSigStartValue" SG_ 326 StatusExtraBoostETractSys2 3;
BA_ "CycleTime" SG_ 385 VCU_BMS_ActCoolingSts 100;
BA_ "GenSigTimeoutTime" SG_ 385 VCU_BMS_ActCoolingSts 500;
BA_ "CycleTime" SG_ 385 VCU_BMS_HeatingSts 100;
BA_ "GenSigTimeoutTime" SG_ 385 VCU_BMS_HeatingSts 500;
BA_ "CycleTime" SG_ 385 CRC_VCU_BMS_ThermalStatus 100;
BA_ "GenSigTimeoutTime" SG_ 385 CRC_VCU_BMS_ThermalStatus 500;
BA_ "CycleTime" SG_ 385 ALV_VCU_BMS_ThermalStatus 100;
BA_ "GenSigTimeoutTime" SG_ 385 ALV_VCU_BMS_ThermalStatus 500;
BA_ "InvalidValue" SG_ 385 ALV_VCU_BMS_ThermalStatus 15;
BA_ "CycleTime" SG_ 389 CRC_BMS_CellTemp 100;
BA_ "GenSigTimeoutTime" SG_ 389 CRC_BMS_CellTemp 500;
BA_ "CycleTime" SG_ 389 ALV_BMS_CellTemp 100;
BA_ "GenSigTimeoutTime" SG_ 389 ALV_BMS_CellTemp 500;
BA_ "InvalidValue" SG_ 389 ALV_BMS_CellTemp 15;
BA_ "CycleTime" SG_ 389 BMS_MinCellTemp 100;
BA_ "GenSigTimeoutTime" SG_ 389 BMS_MinCellTemp 500;
BA_ "InvalidValue" SG_ 389 BMS_MinCellTemp 255;
BA_ "GenSigStartValue" SG_ 389 BMS_MinCellTemp 108;
BA_ "CycleTime" SG_ 389 BMS_PackTemp 100;
BA_ "GenSigTimeoutTime" SG_ 389 BMS_PackTemp 500;
BA_ "InvalidValue" SG_ 389 BMS_PackTemp 255;
BA_ "GenSigStartValue" SG_ 389 BMS_PackTemp 108;
BA_ "CycleTime" SG_ 389 BMS_MaxCellTemp 100;
BA_ "GenSigTimeoutTime" SG_ 389 BMS_MaxCellTemp 500;
BA_ "InvalidValue" SG_ 389 BMS_MaxCellTemp 255;
BA_ "GenSigStartValue" SG_ 389 BMS_MaxCellTemp 108;
BA_ "CycleTime" SG_ 389 BMS_ProbeNumMaxCellTemp 100;
BA_ "GenSigTimeoutTime" SG_ 389 BMS_ProbeNumMaxCellTemp 500;
BA_ "CycleTime" SG_ 389 BMS_ProbeNumMinCellTemp 100;
BA_ "GenSigTimeoutTime" SG_ 389 BMS_ProbeNumMinCellTemp 500;
BA_ "CycleTime" SG_ 389 BMS_MaxMinDiffCellTemp 100;
BA_ "GenSigTimeoutTime" SG_ 389 BMS_MaxMinDiffCellTemp 500;
BA_ "InvalidValue" SG_ 389 BMS_MaxMinDiffCellTemp 255;
BA_ "GenSigStartValue" SG_ 389 BMS_MaxMinDiffCellTemp 80;
BA_ "CycleTime" SG_ 394 BMS_CellTemp41 100;
BA_ "GenSigTimeoutTime" SG_ 394 BMS_CellTemp41 500;
BA_ "InvalidValue" SG_ 394 BMS_CellTemp41 1023;
BA_ "GenSigStartValue" SG_ 394 BMS_CellTemp41 680;
BA_ "CycleTime" SG_ 394 BMS_CellTemp40 100;
BA_ "GenSigTimeoutTime" SG_ 394 BMS_CellTemp40 500;
BA_ "InvalidValue" SG_ 394 BMS_CellTemp40 1023;
BA_ "GenSigStartValue" SG_ 394 BMS_CellTemp40 680;
BA_ "CycleTime" SG_ 394 BMS_CellTemp39 100;
BA_ "GenSigTimeoutTime" SG_ 394 BMS_CellTemp39 500;
BA_ "InvalidValue" SG_ 394 BMS_CellTemp39 1023;
BA_ "GenSigStartValue" SG_ 394 BMS_CellTemp39 680;
BA_ "CycleTime" SG_ 394 BMS_CellTemp38 100;
BA_ "GenSigTimeoutTime" SG_ 394 BMS_CellTemp38 500;
BA_ "InvalidValue" SG_ 394 BMS_CellTemp38 1023;
BA_ "GenSigStartValue" SG_ 394 BMS_CellTemp38 680;
BA_ "CycleTime" SG_ 394 BMS_CellTemp37 100;
BA_ "GenSigTimeoutTime" SG_ 394 BMS_CellTemp37 500;
BA_ "InvalidValue" SG_ 394 BMS_CellTemp37 1023;
BA_ "GenSigStartValue" SG_ 394 BMS_CellTemp37 680;
BA_ "CycleTime" SG_ 394 BMS_CellTemp8 100;
BA_ "GenSigTimeoutTime" SG_ 394 BMS_CellTemp8 500;
BA_ "InvalidValue" SG_ 394 BMS_CellTemp8 1023;
BA_ "GenSigStartValue" SG_ 394 BMS_CellTemp8 680;
BA_ "CycleTime" SG_ 394 BMS_CellTemp6 100;
BA_ "GenSigTimeoutTime" SG_ 394 BMS_CellTemp6 500;
BA_ "InvalidValue" SG_ 394 BMS_CellTemp6 1023;
BA_ "GenSigStartValue" SG_ 394 BMS_CellTemp6 680;
BA_ "CycleTime" SG_ 394 BMS_CellTemp7 100;
BA_ "GenSigTimeoutTime" SG_ 394 BMS_CellTemp7 500;
BA_ "InvalidValue" SG_ 394 BMS_CellTemp7 1023;
BA_ "GenSigStartValue" SG_ 394 BMS_CellTemp7 680;
BA_ "CycleTime" SG_ 394 BMS_CellTemp5 100;
BA_ "GenSigTimeoutTime" SG_ 394 BMS_CellTemp5 500;
BA_ "InvalidValue" SG_ 394 BMS_CellTemp5 1023;
BA_ "GenSigStartValue" SG_ 394 BMS_CellTemp5 680;
BA_ "CycleTime" SG_ 394 ALV_BMS_CellTempMeas 100;
BA_ "GenSigTimeoutTime" SG_ 394 ALV_BMS_CellTempMeas 500;
BA_ "InvalidValue" SG_ 394 ALV_BMS_CellTempMeas 15;
BA_ "CycleTime" SG_ 394 BMS_CellTemp2 100;
BA_ "GenSigTimeoutTime" SG_ 394 BMS_CellTemp2 500;
BA_ "InvalidValue" SG_ 394 BMS_CellTemp2 1023;
BA_ "GenSigStartValue" SG_ 394 BMS_CellTemp2 680;
BA_ "CycleTime" SG_ 394 BMS_CellTemp1 100;
BA_ "GenSigTimeoutTime" SG_ 394 BMS_CellTemp1 500;
BA_ "InvalidValue" SG_ 394 BMS_CellTemp1 1023;
BA_ "GenSigStartValue" SG_ 394 BMS_CellTemp1 680;
BA_ "CycleTime" SG_ 394 CRC_BMS_CellTempMeas 100;
BA_ "GenSigTimeoutTime" SG_ 394 CRC_BMS_CellTempMeas 500;
BA_ "CycleTime" SG_ 394 BMS_CellTemp9 100;
BA_ "GenSigTimeoutTime" SG_ 394 BMS_CellTemp9 500;
BA_ "InvalidValue" SG_ 394 BMS_CellTemp9 1023;
BA_ "GenSigStartValue" SG_ 394 BMS_CellTemp9 680;
BA_ "CycleTime" SG_ 394 BMS_CellTemp4 100;
BA_ "GenSigTimeoutTime" SG_ 394 BMS_CellTemp4 500;
BA_ "InvalidValue" SG_ 394 BMS_CellTemp4 1023;
BA_ "GenSigStartValue" SG_ 394 BMS_CellTemp4 680;
BA_ "CycleTime" SG_ 394 BMS_CellTemp10 100;
BA_ "GenSigTimeoutTime" SG_ 394 BMS_CellTemp10 500;
BA_ "InvalidValue" SG_ 394 BMS_CellTemp10 1023;
BA_ "GenSigStartValue" SG_ 394 BMS_CellTemp10 680;
BA_ "CycleTime" SG_ 394 BMS_CellTemp3 100;
BA_ "GenSigTimeoutTime" SG_ 394 BMS_CellTemp3 500;
BA_ "InvalidValue" SG_ 394 BMS_CellTemp3 1023;
BA_ "GenSigStartValue" SG_ 394 BMS_CellTemp3 680;
BA_ "CycleTime" SG_ 394 BMS_CellTemp12 100;
BA_ "GenSigTimeoutTime" SG_ 394 BMS_CellTemp12 500;
BA_ "InvalidValue" SG_ 394 BMS_CellTemp12 1023;
BA_ "GenSigStartValue" SG_ 394 BMS_CellTemp12 680;
BA_ "CycleTime" SG_ 394 BMS_CellTemp11 100;
BA_ "GenSigTimeoutTime" SG_ 394 BMS_CellTemp11 500;
BA_ "InvalidValue" SG_ 394 BMS_CellTemp11 1023;
BA_ "GenSigStartValue" SG_ 394 BMS_CellTemp11 680;
BA_ "CycleTime" SG_ 394 BMS_CellTemp36 100;
BA_ "GenSigTimeoutTime" SG_ 394 BMS_CellTemp36 500;
BA_ "InvalidValue" SG_ 394 BMS_CellTemp36 1023;
BA_ "GenSigStartValue" SG_ 394 BMS_CellTemp36 680;
BA_ "CycleTime" SG_ 394 BMS_CellTemp35 100;
BA_ "GenSigTimeoutTime" SG_ 394 BMS_CellTemp35 500;
BA_ "InvalidValue" SG_ 394 BMS_CellTemp35 1023;
BA_ "GenSigStartValue" SG_ 394 BMS_CellTemp35 680;
BA_ "CycleTime" SG_ 394 BMS_CellTemp34 100;
BA_ "GenSigTimeoutTime" SG_ 394 BMS_CellTemp34 500;
BA_ "InvalidValue" SG_ 394 BMS_CellTemp34 1023;
BA_ "GenSigStartValue" SG_ 394 BMS_CellTemp34 680;
BA_ "CycleTime" SG_ 394 BMS_CellTemp33 100;
BA_ "GenSigTimeoutTime" SG_ 394 BMS_CellTemp33 500;
BA_ "InvalidValue" SG_ 394 BMS_CellTemp33 1023;
BA_ "GenSigStartValue" SG_ 394 BMS_CellTemp33 680;
BA_ "CycleTime" SG_ 394 BMS_CellTemp32 100;
BA_ "GenSigTimeoutTime" SG_ 394 BMS_CellTemp32 500;
BA_ "InvalidValue" SG_ 394 BMS_CellTemp32 1023;
BA_ "GenSigStartValue" SG_ 394 BMS_CellTemp32 680;
BA_ "CycleTime" SG_ 394 BMS_CellTemp31 100;
BA_ "GenSigTimeoutTime" SG_ 394 BMS_CellTemp31 500;
BA_ "InvalidValue" SG_ 394 BMS_CellTemp31 1023;
BA_ "GenSigStartValue" SG_ 394 BMS_CellTemp31 680;
BA_ "CycleTime" SG_ 394 BMS_CellTemp30 100;
BA_ "GenSigTimeoutTime" SG_ 394 BMS_CellTemp30 500;
BA_ "InvalidValue" SG_ 394 BMS_CellTemp30 1023;
BA_ "GenSigStartValue" SG_ 394 BMS_CellTemp30 680;
BA_ "CycleTime" SG_ 394 BMS_CellTemp28 100;
BA_ "GenSigTimeoutTime" SG_ 394 BMS_CellTemp28 500;
BA_ "InvalidValue" SG_ 394 BMS_CellTemp28 1023;
BA_ "GenSigStartValue" SG_ 394 BMS_CellTemp28 680;
BA_ "CycleTime" SG_ 394 BMS_CellTemp27 100;
BA_ "GenSigTimeoutTime" SG_ 394 BMS_CellTemp27 500;
BA_ "InvalidValue" SG_ 394 BMS_CellTemp27 1023;
BA_ "GenSigStartValue" SG_ 394 BMS_CellTemp27 680;
BA_ "CycleTime" SG_ 394 BMS_CellTemp26 100;
BA_ "GenSigTimeoutTime" SG_ 394 BMS_CellTemp26 500;
BA_ "InvalidValue" SG_ 394 BMS_CellTemp26 1023;
BA_ "GenSigStartValue" SG_ 394 BMS_CellTemp26 680;
BA_ "CycleTime" SG_ 394 BMS_CellTemp25 100;
BA_ "GenSigTimeoutTime" SG_ 394 BMS_CellTemp25 500;
BA_ "InvalidValue" SG_ 394 BMS_CellTemp25 1023;
BA_ "GenSigStartValue" SG_ 394 BMS_CellTemp25 680;
BA_ "CycleTime" SG_ 394 BMS_CellTemp24 100;
BA_ "GenSigTimeoutTime" SG_ 394 BMS_CellTemp24 500;
BA_ "InvalidValue" SG_ 394 BMS_CellTemp24 1023;
BA_ "GenSigStartValue" SG_ 394 BMS_CellTemp24 680;
BA_ "CycleTime" SG_ 394 BMS_CellTemp29 100;
BA_ "GenSigTimeoutTime" SG_ 394 BMS_CellTemp29 500;
BA_ "InvalidValue" SG_ 394 BMS_CellTemp29 1023;
BA_ "GenSigStartValue" SG_ 394 BMS_CellTemp29 680;
BA_ "CycleTime" SG_ 394 BMS_CellTemp22 100;
BA_ "GenSigTimeoutTime" SG_ 394 BMS_CellTemp22 500;
BA_ "InvalidValue" SG_ 394 BMS_CellTemp22 1023;
BA_ "GenSigStartValue" SG_ 394 BMS_CellTemp22 680;
BA_ "CycleTime" SG_ 394 BMS_CellTemp13 100;
BA_ "GenSigTimeoutTime" SG_ 394 BMS_CellTemp13 500;
BA_ "InvalidValue" SG_ 394 BMS_CellTemp13 1023;
BA_ "GenSigStartValue" SG_ 394 BMS_CellTemp13 680;
BA_ "CycleTime" SG_ 394 BMS_CellTemp23 100;
BA_ "GenSigTimeoutTime" SG_ 394 BMS_CellTemp23 500;
BA_ "InvalidValue" SG_ 394 BMS_CellTemp23 1023;
BA_ "GenSigStartValue" SG_ 394 BMS_CellTemp23 680;
BA_ "CycleTime" SG_ 394 BMS_CellTemp15 100;
BA_ "GenSigTimeoutTime" SG_ 394 BMS_CellTemp15 500;
BA_ "InvalidValue" SG_ 394 BMS_CellTemp15 1023;
BA_ "GenSigStartValue" SG_ 394 BMS_CellTemp15 680;
BA_ "CycleTime" SG_ 394 BMS_CellTemp16 100;
BA_ "GenSigTimeoutTime" SG_ 394 BMS_CellTemp16 500;
BA_ "InvalidValue" SG_ 394 BMS_CellTemp16 1023;
BA_ "GenSigStartValue" SG_ 394 BMS_CellTemp16 680;
BA_ "CycleTime" SG_ 394 BMS_CellTemp17 100;
BA_ "GenSigTimeoutTime" SG_ 394 BMS_CellTemp17 500;
BA_ "InvalidValue" SG_ 394 BMS_CellTemp17 1023;
BA_ "GenSigStartValue" SG_ 394 BMS_CellTemp17 680;
BA_ "CycleTime" SG_ 394 BMS_CellTemp18 100;
BA_ "GenSigTimeoutTime" SG_ 394 BMS_CellTemp18 500;
BA_ "InvalidValue" SG_ 394 BMS_CellTemp18 1023;
BA_ "GenSigStartValue" SG_ 394 BMS_CellTemp18 680;
BA_ "CycleTime" SG_ 394 BMS_CellTemp14 100;
BA_ "GenSigTimeoutTime" SG_ 394 BMS_CellTemp14 500;
BA_ "InvalidValue" SG_ 394 BMS_CellTemp14 1023;
BA_ "GenSigStartValue" SG_ 394 BMS_CellTemp14 680;
BA_ "CycleTime" SG_ 394 BMS_CellTemp19 100;
BA_ "GenSigTimeoutTime" SG_ 394 BMS_CellTemp19 500;
BA_ "InvalidValue" SG_ 394 BMS_CellTemp19 1023;
BA_ "GenSigStartValue" SG_ 394 BMS_CellTemp19 680;
BA_ "CycleTime" SG_ 394 BMS_CellTemp20 100;
BA_ "GenSigTimeoutTime" SG_ 394 BMS_CellTemp20 500;
BA_ "InvalidValue" SG_ 394 BMS_CellTemp20 1023;
BA_ "GenSigStartValue" SG_ 394 BMS_CellTemp20 680;
BA_ "CycleTime" SG_ 394 BMS_CellTemp21 100;
BA_ "GenSigTimeoutTime" SG_ 394 BMS_CellTemp21 500;
BA_ "InvalidValue" SG_ 394 BMS_CellTemp21 1023;
BA_ "GenSigStartValue" SG_ 394 BMS_CellTemp21 680;
BA_ "CycleTime" SG_ 399 BMS_CellVol18 100;
BA_ "GenSigTimeoutTime" SG_ 399 BMS_CellVol18 500;
BA_ "InvalidValue" SG_ 399 BMS_CellVol18 1023;
BA_ "GenSigStartValue" SG_ 399 BMS_CellVol18 800;
BA_ "CycleTime" SG_ 399 BMS_CellVol19 100;
BA_ "GenSigTimeoutTime" SG_ 399 BMS_CellVol19 500;
BA_ "InvalidValue" SG_ 399 BMS_CellVol19 1023;
BA_ "GenSigStartValue" SG_ 399 BMS_CellVol19 800;
BA_ "CycleTime" SG_ 399 BMS_CellVol20 100;
BA_ "GenSigTimeoutTime" SG_ 399 BMS_CellVol20 500;
BA_ "InvalidValue" SG_ 399 BMS_CellVol20 1023;
BA_ "GenSigStartValue" SG_ 399 BMS_CellVol20 800;
BA_ "CycleTime" SG_ 399 BMS_CellVol21 100;
BA_ "GenSigTimeoutTime" SG_ 399 BMS_CellVol21 500;
BA_ "InvalidValue" SG_ 399 BMS_CellVol21 1023;
BA_ "GenSigStartValue" SG_ 399 BMS_CellVol21 800;
BA_ "CycleTime" SG_ 399 BMS_CellVol22 100;
BA_ "GenSigTimeoutTime" SG_ 399 BMS_CellVol22 500;
BA_ "InvalidValue" SG_ 399 BMS_CellVol22 1023;
BA_ "GenSigStartValue" SG_ 399 BMS_CellVol22 800;
BA_ "CycleTime" SG_ 399 BMS_CellVol23 100;
BA_ "GenSigTimeoutTime" SG_ 399 BMS_CellVol23 500;
BA_ "InvalidValue" SG_ 399 BMS_CellVol23 1023;
BA_ "GenSigStartValue" SG_ 399 BMS_CellVol23 800;
BA_ "CycleTime" SG_ 399 BMS_CellVol24 100;
BA_ "GenSigTimeoutTime" SG_ 399 BMS_CellVol24 500;
BA_ "InvalidValue" SG_ 399 BMS_CellVol24 1023;
BA_ "GenSigStartValue" SG_ 399 BMS_CellVol24 800;
BA_ "CycleTime" SG_ 399 BMS_CellVol25 100;
BA_ "GenSigTimeoutTime" SG_ 399 BMS_CellVol25 500;
BA_ "InvalidValue" SG_ 399 BMS_CellVol25 1023;
BA_ "GenSigStartValue" SG_ 399 BMS_CellVol25 800;
BA_ "CycleTime" SG_ 399 BMS_CellVol26 100;
BA_ "GenSigTimeoutTime" SG_ 399 BMS_CellVol26 500;
BA_ "InvalidValue" SG_ 399 BMS_CellVol26 1023;
BA_ "GenSigStartValue" SG_ 399 BMS_CellVol26 800;
BA_ "CycleTime" SG_ 399 BMS_CellVol28 100;
BA_ "GenSigTimeoutTime" SG_ 399 BMS_CellVol28 500;
BA_ "InvalidValue" SG_ 399 BMS_CellVol28 1023;
BA_ "GenSigStartValue" SG_ 399 BMS_CellVol28 800;
BA_ "CycleTime" SG_ 399 BMS_CellVol17 100;
BA_ "GenSigTimeoutTime" SG_ 399 BMS_CellVol17 500;
BA_ "InvalidValue" SG_ 399 BMS_CellVol17 1023;
BA_ "GenSigStartValue" SG_ 399 BMS_CellVol17 800;
BA_ "CycleTime" SG_ 399 BMS_CellVol27 100;
BA_ "GenSigTimeoutTime" SG_ 399 BMS_CellVol27 500;
BA_ "InvalidValue" SG_ 399 BMS_CellVol27 1023;
BA_ "GenSigStartValue" SG_ 399 BMS_CellVol27 800;
BA_ "CycleTime" SG_ 399 BMS_CellVol29 100;
BA_ "GenSigTimeoutTime" SG_ 399 BMS_CellVol29 500;
BA_ "InvalidValue" SG_ 399 BMS_CellVol29 1023;
BA_ "GenSigStartValue" SG_ 399 BMS_CellVol29 800;
BA_ "CycleTime" SG_ 399 BMS_CellVol16 100;
BA_ "GenSigTimeoutTime" SG_ 399 BMS_CellVol16 500;
BA_ "InvalidValue" SG_ 399 BMS_CellVol16 1023;
BA_ "GenSigStartValue" SG_ 399 BMS_CellVol16 800;
BA_ "CycleTime" SG_ 399 CRC_BMS_CellVolMeas 100;
BA_ "GenSigTimeoutTime" SG_ 399 CRC_BMS_CellVolMeas 500;
BA_ "CycleTime" SG_ 399 BMS_CellVol14 100;
BA_ "GenSigTimeoutTime" SG_ 399 BMS_CellVol14 500;
BA_ "InvalidValue" SG_ 399 BMS_CellVol14 1023;
BA_ "GenSigStartValue" SG_ 399 BMS_CellVol14 800;
BA_ "CycleTime" SG_ 399 BMS_CellVol13 100;
BA_ "GenSigTimeoutTime" SG_ 399 BMS_CellVol13 500;
BA_ "InvalidValue" SG_ 399 BMS_CellVol13 1023;
BA_ "GenSigStartValue" SG_ 399 BMS_CellVol13 800;
BA_ "CycleTime" SG_ 399 BMS_CellVol8 100;
BA_ "GenSigTimeoutTime" SG_ 399 BMS_CellVol8 500;
BA_ "InvalidValue" SG_ 399 BMS_CellVol8 1023;
BA_ "GenSigStartValue" SG_ 399 BMS_CellVol8 800;
BA_ "CycleTime" SG_ 399 BMS_CellVol7 100;
BA_ "GenSigTimeoutTime" SG_ 399 BMS_CellVol7 500;
BA_ "InvalidValue" SG_ 399 BMS_CellVol7 1023;
BA_ "GenSigStartValue" SG_ 399 BMS_CellVol7 800;
BA_ "CycleTime" SG_ 399 BMS_CellVol6 100;
BA_ "GenSigTimeoutTime" SG_ 399 BMS_CellVol6 500;
BA_ "InvalidValue" SG_ 399 BMS_CellVol6 1023;
BA_ "GenSigStartValue" SG_ 399 BMS_CellVol6 800;
BA_ "CycleTime" SG_ 399 BMS_CellVol5 100;
BA_ "GenSigTimeoutTime" SG_ 399 BMS_CellVol5 500;
BA_ "InvalidValue" SG_ 399 BMS_CellVol5 1023;
BA_ "GenSigStartValue" SG_ 399 BMS_CellVol5 800;
BA_ "CycleTime" SG_ 399 BMS_CellVol4 100;
BA_ "GenSigTimeoutTime" SG_ 399 BMS_CellVol4 500;
BA_ "InvalidValue" SG_ 399 BMS_CellVol4 1023;
BA_ "GenSigStartValue" SG_ 399 BMS_CellVol4 800;
BA_ "CycleTime" SG_ 399 BMS_CellVol3 100;
BA_ "GenSigTimeoutTime" SG_ 399 BMS_CellVol3 500;
BA_ "InvalidValue" SG_ 399 BMS_CellVol3 1023;
BA_ "GenSigStartValue" SG_ 399 BMS_CellVol3 800;
BA_ "CycleTime" SG_ 399 BMS_CellVol2 100;
BA_ "GenSigTimeoutTime" SG_ 399 BMS_CellVol2 500;
BA_ "InvalidValue" SG_ 399 BMS_CellVol2 1023;
BA_ "GenSigStartValue" SG_ 399 BMS_CellVol2 800;
BA_ "CycleTime" SG_ 399 BMS_CellVol1 100;
BA_ "GenSigTimeoutTime" SG_ 399 BMS_CellVol1 500;
BA_ "InvalidValue" SG_ 399 BMS_CellVol1 1023;
BA_ "GenSigStartValue" SG_ 399 BMS_CellVol1 800;
BA_ "CycleTime" SG_ 399 ALV_BMS_CellVolMeas 100;
BA_ "GenSigTimeoutTime" SG_ 399 ALV_BMS_CellVolMeas 500;
BA_ "InvalidValue" SG_ 399 ALV_BMS_CellVolMeas 15;
BA_ "CycleTime" SG_ 399 BMS_CellVol12 100;
BA_ "GenSigTimeoutTime" SG_ 399 BMS_CellVol12 500;
BA_ "InvalidValue" SG_ 399 BMS_CellVol12 1023;
BA_ "GenSigStartValue" SG_ 399 BMS_CellVol12 800;
BA_ "CycleTime" SG_ 399 BMS_CellVol11 100;
BA_ "GenSigTimeoutTime" SG_ 399 BMS_CellVol11 500;
BA_ "InvalidValue" SG_ 399 BMS_CellVol11 1023;
BA_ "GenSigStartValue" SG_ 399 BMS_CellVol11 800;
BA_ "CycleTime" SG_ 399 BMS_CellVol30 100;
BA_ "GenSigTimeoutTime" SG_ 399 BMS_CellVol30 500;
BA_ "InvalidValue" SG_ 399 BMS_CellVol30 1023;
BA_ "GenSigStartValue" SG_ 399 BMS_CellVol30 800;
BA_ "CycleTime" SG_ 399 BMS_CellVol15 100;
BA_ "GenSigTimeoutTime" SG_ 399 BMS_CellVol15 500;
BA_ "InvalidValue" SG_ 399 BMS_CellVol15 1023;
BA_ "GenSigStartValue" SG_ 399 BMS_CellVol15 800;
BA_ "CycleTime" SG_ 399 BMS_CellVol9 100;
BA_ "GenSigTimeoutTime" SG_ 399 BMS_CellVol9 500;
BA_ "InvalidValue" SG_ 399 BMS_CellVol9 1023;
BA_ "GenSigStartValue" SG_ 399 BMS_CellVol9 800;
BA_ "CycleTime" SG_ 399 BMS_CellVol10 100;
BA_ "GenSigTimeoutTime" SG_ 399 BMS_CellVol10 500;
BA_ "InvalidValue" SG_ 399 BMS_CellVol10 1023;
BA_ "GenSigStartValue" SG_ 399 BMS_CellVol10 800;
BA_ "CycleTime" SG_ 404 BMS_CellVol56 100;
BA_ "GenSigTimeoutTime" SG_ 404 BMS_CellVol56 500;
BA_ "InvalidValue" SG_ 404 BMS_CellVol56 1023;
BA_ "GenSigStartValue" SG_ 404 BMS_CellVol56 800;
BA_ "CycleTime" SG_ 404 BMS_CellVol38 100;
BA_ "GenSigTimeoutTime" SG_ 404 BMS_CellVol38 500;
BA_ "InvalidValue" SG_ 404 BMS_CellVol38 1023;
BA_ "GenSigStartValue" SG_ 404 BMS_CellVol38 800;
BA_ "CycleTime" SG_ 404 BMS_CellVol37 100;
BA_ "GenSigTimeoutTime" SG_ 404 BMS_CellVol37 500;
BA_ "InvalidValue" SG_ 404 BMS_CellVol37 1023;
BA_ "GenSigStartValue" SG_ 404 BMS_CellVol37 800;
BA_ "CycleTime" SG_ 404 BMS_CellVol36 100;
BA_ "GenSigTimeoutTime" SG_ 404 BMS_CellVol36 500;
BA_ "InvalidValue" SG_ 404 BMS_CellVol36 1023;
BA_ "GenSigStartValue" SG_ 404 BMS_CellVol36 800;
BA_ "CycleTime" SG_ 404 BMS_CellVol35 100;
BA_ "GenSigTimeoutTime" SG_ 404 BMS_CellVol35 500;
BA_ "InvalidValue" SG_ 404 BMS_CellVol35 1023;
BA_ "GenSigStartValue" SG_ 404 BMS_CellVol35 800;
BA_ "CycleTime" SG_ 404 BMS_CellVol34 100;
BA_ "GenSigTimeoutTime" SG_ 404 BMS_CellVol34 500;
BA_ "InvalidValue" SG_ 404 BMS_CellVol34 1023;
BA_ "GenSigStartValue" SG_ 404 BMS_CellVol34 800;
BA_ "CycleTime" SG_ 404 BMS_CellVol33 100;
BA_ "GenSigTimeoutTime" SG_ 404 BMS_CellVol33 500;
BA_ "InvalidValue" SG_ 404 BMS_CellVol33 1023;
BA_ "GenSigStartValue" SG_ 404 BMS_CellVol33 800;
BA_ "CycleTime" SG_ 404 BMS_CellVol32 100;
BA_ "GenSigTimeoutTime" SG_ 404 BMS_CellVol32 500;
BA_ "InvalidValue" SG_ 404 BMS_CellVol32 1023;
BA_ "GenSigStartValue" SG_ 404 BMS_CellVol32 800;
BA_ "CycleTime" SG_ 404 BMS_CellVol31 100;
BA_ "GenSigTimeoutTime" SG_ 404 BMS_CellVol31 500;
BA_ "InvalidValue" SG_ 404 BMS_CellVol31 1023;
BA_ "GenSigStartValue" SG_ 404 BMS_CellVol31 800;
BA_ "CycleTime" SG_ 404 ALV_BMS_CellVolMeas2 100;
BA_ "GenSigTimeoutTime" SG_ 404 ALV_BMS_CellVolMeas2 500;
BA_ "InvalidValue" SG_ 404 ALV_BMS_CellVolMeas2 15;
BA_ "CycleTime" SG_ 404 CRC_BMS_CellVolMeas2 100;
BA_ "GenSigTimeoutTime" SG_ 404 CRC_BMS_CellVolMeas2 500;
BA_ "CycleTime" SG_ 404 BMS_CellVol59 100;
BA_ "GenSigTimeoutTime" SG_ 404 BMS_CellVol59 500;
BA_ "InvalidValue" SG_ 404 BMS_CellVol59 1023;
BA_ "GenSigStartValue" SG_ 404 BMS_CellVol59 800;
BA_ "CycleTime" SG_ 404 BMS_CellVol60 100;
BA_ "GenSigTimeoutTime" SG_ 404 BMS_CellVol60 500;
BA_ "InvalidValue" SG_ 404 BMS_CellVol60 1023;
BA_ "GenSigStartValue" SG_ 404 BMS_CellVol60 800;
BA_ "CycleTime" SG_ 404 BMS_CellVol61 100;
BA_ "GenSigTimeoutTime" SG_ 404 BMS_CellVol61 500;
BA_ "InvalidValue" SG_ 404 BMS_CellVol61 1023;
BA_ "GenSigStartValue" SG_ 404 BMS_CellVol61 800;
BA_ "CycleTime" SG_ 404 BMS_CellVol62 100;
BA_ "GenSigTimeoutTime" SG_ 404 BMS_CellVol62 500;
BA_ "InvalidValue" SG_ 404 BMS_CellVol62 1023;
BA_ "GenSigStartValue" SG_ 404 BMS_CellVol62 800;
BA_ "CycleTime" SG_ 404 BMS_CellVol57 100;
BA_ "GenSigTimeoutTime" SG_ 404 BMS_CellVol57 500;
BA_ "InvalidValue" SG_ 404 BMS_CellVol57 1023;
BA_ "GenSigStartValue" SG_ 404 BMS_CellVol57 800;
BA_ "CycleTime" SG_ 404 BMS_CellVol39 100;
BA_ "GenSigTimeoutTime" SG_ 404 BMS_CellVol39 500;
BA_ "InvalidValue" SG_ 404 BMS_CellVol39 1023;
BA_ "GenSigStartValue" SG_ 404 BMS_CellVol39 800;
BA_ "CycleTime" SG_ 404 BMS_CellVol40 100;
BA_ "GenSigTimeoutTime" SG_ 404 BMS_CellVol40 500;
BA_ "InvalidValue" SG_ 404 BMS_CellVol40 1023;
BA_ "GenSigStartValue" SG_ 404 BMS_CellVol40 800;
BA_ "CycleTime" SG_ 404 BMS_CellVol42 100;
BA_ "GenSigTimeoutTime" SG_ 404 BMS_CellVol42 500;
BA_ "InvalidValue" SG_ 404 BMS_CellVol42 1023;
BA_ "GenSigStartValue" SG_ 404 BMS_CellVol42 800;
BA_ "CycleTime" SG_ 404 BMS_CellVol49 100;
BA_ "GenSigTimeoutTime" SG_ 404 BMS_CellVol49 500;
BA_ "InvalidValue" SG_ 404 BMS_CellVol49 1023;
BA_ "GenSigStartValue" SG_ 404 BMS_CellVol49 800;
BA_ "CycleTime" SG_ 404 BMS_CellVol53 100;
BA_ "GenSigTimeoutTime" SG_ 404 BMS_CellVol53 500;
BA_ "InvalidValue" SG_ 404 BMS_CellVol53 1023;
BA_ "GenSigStartValue" SG_ 404 BMS_CellVol53 800;
BA_ "CycleTime" SG_ 404 BMS_CellVol52 100;
BA_ "GenSigTimeoutTime" SG_ 404 BMS_CellVol52 500;
BA_ "InvalidValue" SG_ 404 BMS_CellVol52 1023;
BA_ "GenSigStartValue" SG_ 404 BMS_CellVol52 800;
BA_ "CycleTime" SG_ 404 BMS_CellVol51 100;
BA_ "GenSigTimeoutTime" SG_ 404 BMS_CellVol51 500;
BA_ "InvalidValue" SG_ 404 BMS_CellVol51 1023;
BA_ "GenSigStartValue" SG_ 404 BMS_CellVol51 800;
BA_ "CycleTime" SG_ 404 BMS_CellVol50 100;
BA_ "GenSigTimeoutTime" SG_ 404 BMS_CellVol50 500;
BA_ "InvalidValue" SG_ 404 BMS_CellVol50 1023;
BA_ "GenSigStartValue" SG_ 404 BMS_CellVol50 800;
BA_ "CycleTime" SG_ 404 BMS_CellVol48 100;
BA_ "GenSigTimeoutTime" SG_ 404 BMS_CellVol48 500;
BA_ "InvalidValue" SG_ 404 BMS_CellVol48 1023;
BA_ "GenSigStartValue" SG_ 404 BMS_CellVol48 800;
BA_ "CycleTime" SG_ 404 BMS_CellVol46 100;
BA_ "GenSigTimeoutTime" SG_ 404 BMS_CellVol46 500;
BA_ "InvalidValue" SG_ 404 BMS_CellVol46 1023;
BA_ "GenSigStartValue" SG_ 404 BMS_CellVol46 800;
BA_ "CycleTime" SG_ 404 BMS_CellVol47 100;
BA_ "GenSigTimeoutTime" SG_ 404 BMS_CellVol47 500;
BA_ "InvalidValue" SG_ 404 BMS_CellVol47 1023;
BA_ "GenSigStartValue" SG_ 404 BMS_CellVol47 800;
BA_ "CycleTime" SG_ 404 BMS_CellVol44 100;
BA_ "GenSigTimeoutTime" SG_ 404 BMS_CellVol44 500;
BA_ "InvalidValue" SG_ 404 BMS_CellVol44 1023;
BA_ "GenSigStartValue" SG_ 404 BMS_CellVol44 800;
BA_ "CycleTime" SG_ 404 BMS_CellVol43 100;
BA_ "GenSigTimeoutTime" SG_ 404 BMS_CellVol43 500;
BA_ "InvalidValue" SG_ 404 BMS_CellVol43 1023;
BA_ "GenSigStartValue" SG_ 404 BMS_CellVol43 800;
BA_ "CycleTime" SG_ 404 BMS_CellVol58 100;
BA_ "GenSigTimeoutTime" SG_ 404 BMS_CellVol58 500;
BA_ "InvalidValue" SG_ 404 BMS_CellVol58 1023;
BA_ "GenSigStartValue" SG_ 404 BMS_CellVol58 800;
BA_ "CycleTime" SG_ 404 BMS_CellVol41 100;
BA_ "GenSigTimeoutTime" SG_ 404 BMS_CellVol41 500;
BA_ "InvalidValue" SG_ 404 BMS_CellVol41 1023;
BA_ "GenSigStartValue" SG_ 404 BMS_CellVol41 800;
BA_ "CycleTime" SG_ 404 BMS_CellVol55 100;
BA_ "GenSigTimeoutTime" SG_ 404 BMS_CellVol55 500;
BA_ "InvalidValue" SG_ 404 BMS_CellVol55 1023;
BA_ "GenSigStartValue" SG_ 404 BMS_CellVol55 800;
BA_ "CycleTime" SG_ 404 BMS_CellVol45 100;
BA_ "GenSigTimeoutTime" SG_ 404 BMS_CellVol45 500;
BA_ "InvalidValue" SG_ 404 BMS_CellVol45 1023;
BA_ "GenSigStartValue" SG_ 404 BMS_CellVol45 800;
BA_ "CycleTime" SG_ 404 BMS_CellVol54 100;
BA_ "GenSigTimeoutTime" SG_ 404 BMS_CellVol54 500;
BA_ "InvalidValue" SG_ 404 BMS_CellVol54 1023;
BA_ "GenSigStartValue" SG_ 404 BMS_CellVol54 800;
BA_ "GenSigTimeoutTime" SG_ 405 OBC_VCU_iDC 500;
BA_ "CycleTime" SG_ 405 OBC_VCU_iDC 100;
BA_ "GenSigStartValue" SG_ 405 OBC_VCU_iDC 1023;
BA_ "InvalidValue" SG_ 405 OBC_VCU_iDC 2047;
BA_ "GenSigTimeoutTime" SG_ 405 OBC_VCU_vAC_L2 500;
BA_ "CycleTime" SG_ 405 OBC_VCU_vAC_L2 100;
BA_ "InvalidValue" SG_ 405 OBC_VCU_vAC_L2 511;
BA_ "GenSigTimeoutTime" SG_ 405 OBC_VCU_vAC_L1 500;
BA_ "CycleTime" SG_ 405 OBC_VCU_vAC_L1 100;
BA_ "InvalidValue" SG_ 405 OBC_VCU_vAC_L1 511;
BA_ "GenSigTimeoutTime" SG_ 405 OBC_VCU_iAC_L3 500;
BA_ "CycleTime" SG_ 405 OBC_VCU_iAC_L3 100;
BA_ "GenSigStartValue" SG_ 405 OBC_VCU_iAC_L3 1023;
BA_ "InvalidValue" SG_ 405 OBC_VCU_iAC_L3 2047;
BA_ "GenSigTimeoutTime" SG_ 405 OBC_VCU_vDC 500;
BA_ "CycleTime" SG_ 405 OBC_VCU_vDC 100;
BA_ "InvalidValue" SG_ 405 OBC_VCU_vDC 1023;
BA_ "GenSigTimeoutTime" SG_ 405 OBC_VCU_vAC_L3 500;
BA_ "CycleTime" SG_ 405 OBC_VCU_vAC_L3 100;
BA_ "InvalidValue" SG_ 405 OBC_VCU_vAC_L3 511;
BA_ "GenSigTimeoutTime" SG_ 405 OBC_VCU_iAC_L1 500;
BA_ "CycleTime" SG_ 405 OBC_VCU_iAC_L1 100;
BA_ "GenSigStartValue" SG_ 405 OBC_VCU_iAC_L1 1023;
BA_ "InvalidValue" SG_ 405 OBC_VCU_iAC_L1 2047;
BA_ "GenSigTimeoutTime" SG_ 405 OBC_Max_Current_Out 500;
BA_ "CycleTime" SG_ 405 OBC_Max_Current_Out 100;
BA_ "InvalidValue" SG_ 405 OBC_Max_Current_Out 4095;
BA_ "GenSigTimeoutTime" SG_ 405 OBC_VCU_Status 500;
BA_ "CycleTime" SG_ 405 OBC_VCU_Status 100;
BA_ "InvalidValue" SG_ 405 OBC_VCU_Status 3;
BA_ "GenSigTimeoutTime" SG_ 405 OBC_VCU_iAC_L2 500;
BA_ "CycleTime" SG_ 405 OBC_VCU_iAC_L2 100;
BA_ "GenSigStartValue" SG_ 405 OBC_VCU_iAC_L2 1023;
BA_ "InvalidValue" SG_ 405 OBC_VCU_iAC_L2 2047;
BA_ "CycleTime" SG_ 409 BMS_CellVol82 100;
BA_ "GenSigTimeoutTime" SG_ 409 BMS_CellVol82 500;
BA_ "InvalidValue" SG_ 409 BMS_CellVol82 1023;
BA_ "GenSigStartValue" SG_ 409 BMS_CellVol82 800;
BA_ "CycleTime" SG_ 409 BMS_CellVol86 100;
BA_ "GenSigTimeoutTime" SG_ 409 BMS_CellVol86 500;
BA_ "InvalidValue" SG_ 409 BMS_CellVol86 1023;
BA_ "GenSigStartValue" SG_ 409 BMS_CellVol86 800;
BA_ "CycleTime" SG_ 409 BMS_CellVol83 100;
BA_ "GenSigTimeoutTime" SG_ 409 BMS_CellVol83 500;
BA_ "InvalidValue" SG_ 409 BMS_CellVol83 1023;
BA_ "GenSigStartValue" SG_ 409 BMS_CellVol83 800;
BA_ "CycleTime" SG_ 409 BMS_CellVol84 100;
BA_ "GenSigTimeoutTime" SG_ 409 BMS_CellVol84 500;
BA_ "InvalidValue" SG_ 409 BMS_CellVol84 1023;
BA_ "GenSigStartValue" SG_ 409 BMS_CellVol84 800;
BA_ "CycleTime" SG_ 409 BMS_CellVol87 100;
BA_ "GenSigTimeoutTime" SG_ 409 BMS_CellVol87 500;
BA_ "InvalidValue" SG_ 409 BMS_CellVol87 1023;
BA_ "GenSigStartValue" SG_ 409 BMS_CellVol87 800;
BA_ "CycleTime" SG_ 409 BMS_CellVol94 100;
BA_ "GenSigTimeoutTime" SG_ 409 BMS_CellVol94 500;
BA_ "InvalidValue" SG_ 409 BMS_CellVol94 1023;
BA_ "GenSigStartValue" SG_ 409 BMS_CellVol94 800;
BA_ "CycleTime" SG_ 409 BMS_CellVol89 100;
BA_ "GenSigTimeoutTime" SG_ 409 BMS_CellVol89 500;
BA_ "InvalidValue" SG_ 409 BMS_CellVol89 1023;
BA_ "GenSigStartValue" SG_ 409 BMS_CellVol89 800;
BA_ "CycleTime" SG_ 409 BMS_CellVol90 100;
BA_ "GenSigTimeoutTime" SG_ 409 BMS_CellVol90 500;
BA_ "InvalidValue" SG_ 409 BMS_CellVol90 1023;
BA_ "GenSigStartValue" SG_ 409 BMS_CellVol90 800;
BA_ "CycleTime" SG_ 409 BMS_CellVol91 100;
BA_ "GenSigTimeoutTime" SG_ 409 BMS_CellVol91 500;
BA_ "InvalidValue" SG_ 409 BMS_CellVol91 1023;
BA_ "GenSigStartValue" SG_ 409 BMS_CellVol91 800;
BA_ "CycleTime" SG_ 409 BMS_CellVol92 100;
BA_ "GenSigTimeoutTime" SG_ 409 BMS_CellVol92 500;
BA_ "InvalidValue" SG_ 409 BMS_CellVol92 1023;
BA_ "GenSigStartValue" SG_ 409 BMS_CellVol92 800;
BA_ "CycleTime" SG_ 409 BMS_CellVol93 100;
BA_ "GenSigTimeoutTime" SG_ 409 BMS_CellVol93 500;
BA_ "InvalidValue" SG_ 409 BMS_CellVol93 1023;
BA_ "GenSigStartValue" SG_ 409 BMS_CellVol93 800;
BA_ "CycleTime" SG_ 409 BMS_CellVol81 100;
BA_ "GenSigTimeoutTime" SG_ 409 BMS_CellVol81 500;
BA_ "InvalidValue" SG_ 409 BMS_CellVol81 1023;
BA_ "GenSigStartValue" SG_ 409 BMS_CellVol81 800;
BA_ "CycleTime" SG_ 409 BMS_CellVol88 100;
BA_ "GenSigTimeoutTime" SG_ 409 BMS_CellVol88 500;
BA_ "InvalidValue" SG_ 409 BMS_CellVol88 1023;
BA_ "GenSigStartValue" SG_ 409 BMS_CellVol88 800;
BA_ "CycleTime" SG_ 409 BMS_CellVol80 100;
BA_ "GenSigTimeoutTime" SG_ 409 BMS_CellVol80 500;
BA_ "InvalidValue" SG_ 409 BMS_CellVol80 1023;
BA_ "GenSigStartValue" SG_ 409 BMS_CellVol80 800;
BA_ "CycleTime" SG_ 409 BMS_CellVol85 100;
BA_ "GenSigTimeoutTime" SG_ 409 BMS_CellVol85 500;
BA_ "InvalidValue" SG_ 409 BMS_CellVol85 1023;
BA_ "GenSigStartValue" SG_ 409 BMS_CellVol85 800;
BA_ "CycleTime" SG_ 409 BMS_CellVol78 100;
BA_ "GenSigTimeoutTime" SG_ 409 BMS_CellVol78 500;
BA_ "InvalidValue" SG_ 409 BMS_CellVol78 1023;
BA_ "GenSigStartValue" SG_ 409 BMS_CellVol78 800;
BA_ "CycleTime" SG_ 409 BMS_CellVol70 100;
BA_ "GenSigTimeoutTime" SG_ 409 BMS_CellVol70 500;
BA_ "InvalidValue" SG_ 409 BMS_CellVol70 1023;
BA_ "GenSigStartValue" SG_ 409 BMS_CellVol70 800;
BA_ "CycleTime" SG_ 409 BMS_CellVol67 100;
BA_ "GenSigTimeoutTime" SG_ 409 BMS_CellVol67 500;
BA_ "InvalidValue" SG_ 409 BMS_CellVol67 1023;
BA_ "GenSigStartValue" SG_ 409 BMS_CellVol67 800;
BA_ "CycleTime" SG_ 409 BMS_CellVol79 100;
BA_ "GenSigTimeoutTime" SG_ 409 BMS_CellVol79 500;
BA_ "InvalidValue" SG_ 409 BMS_CellVol79 1023;
BA_ "GenSigStartValue" SG_ 409 BMS_CellVol79 800;
BA_ "CycleTime" SG_ 409 BMS_CellVol66 100;
BA_ "GenSigTimeoutTime" SG_ 409 BMS_CellVol66 500;
BA_ "InvalidValue" SG_ 409 BMS_CellVol66 1023;
BA_ "GenSigStartValue" SG_ 409 BMS_CellVol66 800;
BA_ "CycleTime" SG_ 409 BMS_CellVol65 100;
BA_ "GenSigTimeoutTime" SG_ 409 BMS_CellVol65 500;
BA_ "InvalidValue" SG_ 409 BMS_CellVol65 1023;
BA_ "GenSigStartValue" SG_ 409 BMS_CellVol65 800;
BA_ "CycleTime" SG_ 409 BMS_CellVol64 100;
BA_ "GenSigTimeoutTime" SG_ 409 BMS_CellVol64 500;
BA_ "InvalidValue" SG_ 409 BMS_CellVol64 1023;
BA_ "GenSigStartValue" SG_ 409 BMS_CellVol64 800;
BA_ "CycleTime" SG_ 409 BMS_CellVol63 100;
BA_ "GenSigTimeoutTime" SG_ 409 BMS_CellVol63 500;
BA_ "InvalidValue" SG_ 409 BMS_CellVol63 1023;
BA_ "GenSigStartValue" SG_ 409 BMS_CellVol63 800;
BA_ "CycleTime" SG_ 409 ALV_BMS_CellVolMeas3 100;
BA_ "GenSigTimeoutTime" SG_ 409 ALV_BMS_CellVolMeas3 500;
BA_ "InvalidValue" SG_ 409 ALV_BMS_CellVolMeas3 15;
BA_ "CycleTime" SG_ 409 BMS_CellVol69 100;
BA_ "GenSigTimeoutTime" SG_ 409 BMS_CellVol69 500;
BA_ "InvalidValue" SG_ 409 BMS_CellVol69 1023;
BA_ "GenSigStartValue" SG_ 409 BMS_CellVol69 800;
BA_ "CycleTime" SG_ 409 CRC_BMS_CellVolMeas3 100;
BA_ "GenSigTimeoutTime" SG_ 409 CRC_BMS_CellVolMeas3 500;
BA_ "CycleTime" SG_ 409 BMS_CellVol71 100;
BA_ "GenSigTimeoutTime" SG_ 409 BMS_CellVol71 500;
BA_ "InvalidValue" SG_ 409 BMS_CellVol71 1023;
BA_ "GenSigStartValue" SG_ 409 BMS_CellVol71 800;
BA_ "CycleTime" SG_ 409 BMS_CellVol68 100;
BA_ "GenSigTimeoutTime" SG_ 409 BMS_CellVol68 500;
BA_ "InvalidValue" SG_ 409 BMS_CellVol68 1023;
BA_ "GenSigStartValue" SG_ 409 BMS_CellVol68 800;
BA_ "CycleTime" SG_ 409 BMS_CellVol73 100;
BA_ "GenSigTimeoutTime" SG_ 409 BMS_CellVol73 500;
BA_ "InvalidValue" SG_ 409 BMS_CellVol73 1023;
BA_ "GenSigStartValue" SG_ 409 BMS_CellVol73 800;
BA_ "CycleTime" SG_ 409 BMS_CellVol75 100;
BA_ "GenSigTimeoutTime" SG_ 409 BMS_CellVol75 500;
BA_ "InvalidValue" SG_ 409 BMS_CellVol75 1023;
BA_ "GenSigStartValue" SG_ 409 BMS_CellVol75 800;
BA_ "CycleTime" SG_ 409 BMS_CellVol72 100;
BA_ "GenSigTimeoutTime" SG_ 409 BMS_CellVol72 500;
BA_ "InvalidValue" SG_ 409 BMS_CellVol72 1023;
BA_ "GenSigStartValue" SG_ 409 BMS_CellVol72 800;
BA_ "CycleTime" SG_ 409 BMS_CellVol77 100;
BA_ "GenSigTimeoutTime" SG_ 409 BMS_CellVol77 500;
BA_ "InvalidValue" SG_ 409 BMS_CellVol77 1023;
BA_ "GenSigStartValue" SG_ 409 BMS_CellVol77 800;
BA_ "CycleTime" SG_ 409 BMS_CellVol74 100;
BA_ "GenSigTimeoutTime" SG_ 409 BMS_CellVol74 500;
BA_ "InvalidValue" SG_ 409 BMS_CellVol74 1023;
BA_ "GenSigStartValue" SG_ 409 BMS_CellVol74 800;
BA_ "CycleTime" SG_ 409 BMS_CellVol76 100;
BA_ "GenSigTimeoutTime" SG_ 409 BMS_CellVol76 500;
BA_ "InvalidValue" SG_ 409 BMS_CellVol76 1023;
BA_ "GenSigStartValue" SG_ 409 BMS_CellVol76 800;
BA_ "InvalidValue" SG_ 409 BMS_CellVol95 1023;
BA_ "InvalidValue" SG_ 409 BMS_CellVol96 1023;
BA_ "InvalidValue" SG_ 409 BMS_CellVol97 1023;
BA_ "InvalidValue" SG_ 409 BMS_CellVol98 1023;
BA_ "InvalidValue" SG_ 409 BMS_CellVol99 1023;
BA_ "InvalidValue" SG_ 409 BMS_CellVol100 1023;
BA_ "InvalidValue" SG_ 409 BMS_CellVol101 1023;
BA_ "InvalidValue" SG_ 409 BMS_CellVol102 1023;
BA_ "InvalidValue" SG_ 409 BMS_CellVol103 1023;
BA_ "InvalidValue" SG_ 409 BMS_CellVol104 1023;
BA_ "InvalidValue" SG_ 409 BMS_CellVol105 1023;
BA_ "InvalidValue" SG_ 409 BMS_CellVol106 1023;
BA_ "InvalidValue" SG_ 409 BMS_CellVol107 1023;
BA_ "InvalidValue" SG_ 409 BMS_CellVol108 1023;
BA_ "InvalidValue" SG_ 193 VCU_ChgDirType 15;
BA_ "GenSigTimeoutTime" SG_ 193 VCU_ChgDirType 50;
BA_ "CycleTime" SG_ 193 VCU_ChgDirType 10;
BA_ "GenSigTimeoutTime" SG_ 193 VCU_OBC_iOBC_Request 50;
BA_ "CycleTime" SG_ 193 VCU_OBC_iOBC_Request 10;
BA_ "InvalidValue" SG_ 193 VCU_OBC_iOBC_Request 65535;
BA_ "GenSigTimeoutTime" SG_ 193 VCU_OBC_vOBC_Request 50;
BA_ "CycleTime" SG_ 193 VCU_OBC_vOBC_Request 10;
BA_ "InvalidValue" SG_ 193 VCU_OBC_vOBC_Request 65535;
BA_ "GenSigTimeoutTime" SG_ 193 VCU_OBC_Enable 50;
BA_ "CycleTime" SG_ 193 VCU_OBC_Enable 10;
BA_ "InvalidValue" SG_ 193 VCU_OBC_Enable 3;
BA_ "GenSigTimeoutTime" SG_ 193 VCU_OBC_iLineLimit 50;
BA_ "CycleTime" SG_ 193 VCU_OBC_iLineLimit 10;
BA_ "InvalidValue" SG_ 193 VCU_OBC_iLineLimit 1023;
BA_ "CycleTime" SG_ 414 BMS_CoolantOutletTemp 100;
BA_ "GenSigTimeoutTime" SG_ 414 BMS_CoolantOutletTemp 500;
BA_ "GenSigStartValue" SG_ 414 BMS_CoolantOutletTemp 680;
BA_ "CycleTime" SG_ 414 BMS_CoolantInletTemp 100;
BA_ "GenSigTimeoutTime" SG_ 414 BMS_CoolantInletTemp 500;
BA_ "GenSigStartValue" SG_ 414 BMS_CoolantInletTemp 680;
BA_ "CycleTime" SG_ 414 ALV_BMS_CoolantInletOutletTmp 100;
BA_ "GenSigTimeoutTime" SG_ 414 ALV_BMS_CoolantInletOutletTmp 500;
BA_ "InvalidValue" SG_ 414 ALV_BMS_CoolantInletOutletTmp 15;
BA_ "CycleTime" SG_ 414 CRC_BMS_CoolantInletOutletTmp 100;
BA_ "GenSigTimeoutTime" SG_ 414 CRC_BMS_CoolantInletOutletTmp 500;
BA_ "CycleTime" SG_ 418 VCU_TargetASOC 100;
BA_ "GenSigTimeoutTime" SG_ 418 VCU_TargetASOC 500;
BA_ "InvalidValue" SG_ 418 VCU_TargetASOC 1023;
BA_ "GenSigStartValue" SG_ 418 VCU_TargetASOC 1000;
BA_ "CycleTime" SG_ 418 ALV_VCU_BMS_ChargingParams 100;
BA_ "GenSigTimeoutTime" SG_ 418 ALV_VCU_BMS_ChargingParams 500;
BA_ "InvalidValue" SG_ 418 ALV_VCU_BMS_ChargingParams 15;
BA_ "CycleTime" SG_ 418 CRC_VCU_BMS_ChargingParams 100;
BA_ "GenSigTimeoutTime" SG_ 418 CRC_VCU_BMS_ChargingParams 500;
BA_ "CycleTime" SG_ 419 BMS_PackInsuRes 100;
BA_ "GenSigTimeoutTime" SG_ 419 BMS_PackInsuRes 500;
BA_ "InvalidValue" SG_ 419 BMS_PackInsuRes 8191;
BA_ "CycleTime" SG_ 419 BMS_VCU_InsulationMonSts 100;
BA_ "GenSigTimeoutTime" SG_ 419 BMS_VCU_InsulationMonSts 500;
BA_ "CycleTime" SG_ 419 ALV_BMS_Insulation 100;
BA_ "GenSigTimeoutTime" SG_ 419 ALV_BMS_Insulation 500;
BA_ "InvalidValue" SG_ 419 ALV_BMS_Insulation 15;
BA_ "CycleTime" SG_ 419 CRC_BMS_Insulation 100;
BA_ "GenSigTimeoutTime" SG_ 419 CRC_BMS_Insulation 500;
BA_ "CycleTime" SG_ 420 ALV_VCU_BMS_ChargingControl 100;
BA_ "GenSigTimeoutTime" SG_ 420 ALV_VCU_BMS_ChargingControl 500;
BA_ "InvalidValue" SG_ 420 ALV_VCU_BMS_ChargingControl 15;
BA_ "CycleTime" SG_ 420 VCU_BMS_InsulationMonReq 100;
BA_ "GenSigTimeoutTime" SG_ 420 VCU_BMS_InsulationMonReq 500;
BA_ "CycleTime" SG_ 420 CRC_VCU_BMS_ChargingControl 100;
BA_ "GenSigTimeoutTime" SG_ 420 CRC_VCU_BMS_ChargingControl 500;
BA_ "CycleTime" SG_ 420 VCU_BMS_ChargeAllow 100;
BA_ "GenSigTimeoutTime" SG_ 420 VCU_BMS_ChargeAllow 500;
BA_ "CycleTime" SG_ 424 BMS_VCU_HeatingOnOffReq 100;
BA_ "GenSigTimeoutTime" SG_ 424 BMS_VCU_HeatingOnOffReq 500;
BA_ "CycleTime" SG_ 424 BMS_VCU_CoolingOnOffReq 100;
BA_ "GenSigTimeoutTime" SG_ 424 BMS_VCU_CoolingOnOffReq 500;
BA_ "CycleTime" SG_ 424 BMS_HeatPwrDemand 100;
BA_ "GenSigTimeoutTime" SG_ 424 BMS_HeatPwrDemand 500;
BA_ "InvalidValue" SG_ 424 BMS_HeatPwrDemand 4095;
BA_ "CycleTime" SG_ 424 BMS_FlowRateReq 100;
BA_ "GenSigTimeoutTime" SG_ 424 BMS_FlowRateReq 500;
BA_ "InvalidValue" SG_ 424 BMS_FlowRateReq 255;
BA_ "CycleTime" SG_ 424 ALV_BMS_VCU_THMReq 100;
BA_ "GenSigTimeoutTime" SG_ 424 ALV_BMS_VCU_THMReq 500;
BA_ "InvalidValue" SG_ 424 ALV_BMS_VCU_THMReq 15;
BA_ "CycleTime" SG_ 424 CRC_BMS_VCU_THMReq 100;
BA_ "GenSigTimeoutTime" SG_ 424 CRC_BMS_VCU_THMReq 1000;
BA_ "CycleTime" SG_ 424 BMS_CoolPwrDemand 100;
BA_ "GenSigTimeoutTime" SG_ 424 BMS_CoolPwrDemand 500;
BA_ "InvalidValue" SG_ 424 BMS_CoolPwrDemand 4095;
BA_ "CycleTime" SG_ 429 BMS_MaxCellVol 100;
BA_ "GenSigTimeoutTime" SG_ 429 BMS_MaxCellVol 500;
BA_ "InvalidValue" SG_ 429 BMS_MaxCellVol 8191;
BA_ "GenSigStartValue" SG_ 429 BMS_MaxCellVol 4000;
BA_ "CycleTime" SG_ 429 BMS_MinCellVol 100;
BA_ "GenSigTimeoutTime" SG_ 429 BMS_MinCellVol 500;
BA_ "InvalidValue" SG_ 429 BMS_MinCellVol 8191;
BA_ "GenSigStartValue" SG_ 429 BMS_MinCellVol 4000;
BA_ "CycleTime" SG_ 429 BMS_CellNumMaxCellVol 100;
BA_ "GenSigTimeoutTime" SG_ 429 BMS_CellNumMaxCellVol 500;
BA_ "CycleTime" SG_ 429 BMS_CellNumMinCellVol 100;
BA_ "GenSigTimeoutTime" SG_ 429 BMS_CellNumMinCellVol 500;
BA_ "CycleTime" SG_ 429 ALV_BMS_VolMeas 100;
BA_ "GenSigTimeoutTime" SG_ 429 ALV_BMS_VolMeas 500;
BA_ "InvalidValue" SG_ 429 ALV_BMS_VolMeas 15;
BA_ "CycleTime" SG_ 429 CRC_BMS_VolMeas 100;
BA_ "GenSigTimeoutTime" SG_ 429 CRC_BMS_VolMeas 500;
BA_ "CycleTime" SG_ 429 BMS_MaxMinDiffCellVol 100;
BA_ "GenSigTimeoutTime" SG_ 429 BMS_MaxMinDiffCellVol 500;
BA_ "InvalidValue" SG_ 429 BMS_MaxMinDiffCellVol 8191;
BA_ "CycleTime" SG_ 433 VCU_BMS_HVOnOffReq 100;
BA_ "GenSigTimeoutTime" SG_ 433 VCU_BMS_HVOnOffReq 500;
BA_ "CycleTime" SG_ 433 ALV_VCU_BMS_HVCoordination 100;
BA_ "GenSigTimeoutTime" SG_ 433 ALV_VCU_BMS_HVCoordination 500;
BA_ "InvalidValue" SG_ 433 ALV_VCU_BMS_HVCoordination 15;
BA_ "CycleTime" SG_ 433 CRC_VCU_BMS_HVCoordination 100;
BA_ "GenSigTimeoutTime" SG_ 433 CRC_VCU_BMS_HVCoordination 500;
BA_ "CycleTime" SG_ 450 DCDC_InternalTempC 100;
BA_ "GenSigTimeoutTime" SG_ 450 DCDC_InternalTempC 500;
BA_ "InvalidValue" SG_ 450 DCDC_InternalTempC 4095;
BA_ "GenSigStartValue" SG_ 450 DCDC_InternalTempC 1000;
BA_ "CycleTime" SG_ 450 DCDC_InternalTempB 100;
BA_ "GenSigTimeoutTime" SG_ 450 DCDC_InternalTempB 500;
BA_ "InvalidValue" SG_ 450 DCDC_InternalTempB 4095;
BA_ "GenSigStartValue" SG_ 450 DCDC_InternalTempB 1000;
BA_ "GenSigTimeoutTime" SG_ 450 DCDC_CoolPwrDemand 500;
BA_ "CycleTime" SG_ 450 DCDC_CoolPwrDemand 100;
BA_ "InvalidValue" SG_ 450 DCDC_CoolPwrDemand 255;
BA_ "GenSigTimeoutTime" SG_ 450 DCDC_FlowRateReq 500;
BA_ "CycleTime" SG_ 450 DCDC_FlowRateReq 100;
BA_ "InvalidValue" SG_ 450 DCDC_FlowRateReq 255;
BA_ "GenSigStartValue" SG_ 450 DCDC_FlowRateReq 15;
BA_ "GenSigTimeoutTime" SG_ 450 DCDC_InternalTempA 500;
BA_ "CycleTime" SG_ 450 DCDC_InternalTempA 100;
BA_ "InvalidValue" SG_ 450 DCDC_InternalTempA 4095;
BA_ "GenSigStartValue" SG_ 450 DCDC_InternalTempA 1000;
BA_ "CycleTime" SG_ 490 MILE_KM_TOT 300;
BA_ "GenSigTimeoutTime" SG_ 490 MILE_KM_TOT 1500;
BA_ "GenSigStartValue" SG_ 490 MILE_KM_TOT 4294967295;
BA_ "GenSigTimeoutTime" SG_ 197 VCU_EnableDCDC 50;
BA_ "CycleTime" SG_ 197 VCU_EnableDCDC 10;
BA_ "InvalidValue" SG_ 197 VCU_EnableDCDC 1;
BA_ "GenSigTimeoutTime" SG_ 197 VCU_OutVltgReq 50;
BA_ "CycleTime" SG_ 197 VCU_OutVltgReq 10;
BA_ "InvalidValue" SG_ 197 VCU_OutVltgReq 65535;
BA_ "GenSigTimeoutTime" SG_ 197 VCU_OutCurReq 50;
BA_ "CycleTime" SG_ 197 VCU_OutCurReq 10;
BA_ "InvalidValue" SG_ 197 VCU_OutCurReq 65535;
BA_ "CycleTime" SG_ 517 CRC_BMS_HistData 200;
BA_ "GenSigTimeoutTime" SG_ 517 CRC_BMS_HistData 1000;
BA_ "CycleTime" SG_ 517 BMS_ContactorAging 200;
BA_ "GenSigTimeoutTime" SG_ 517 BMS_ContactorAging 1000;
BA_ "InvalidValue" SG_ 517 BMS_ContactorAging 255;
BA_ "CycleTime" SG_ 517 ALV_BMS_HistData 200;
BA_ "GenSigTimeoutTime" SG_ 517 ALV_BMS_HistData 1000;
BA_ "InvalidValue" SG_ 517 ALV_BMS_HistData 15;
BA_ "CycleTime" SG_ 532 CRC_ParkByWire50msNo1 50;
BA_ "GenSigTimeoutTime" SG_ 532 CRC_ParkByWire50msNo1 250;
BA_ "InvalidValue" SG_ 532 CRC_ParkByWire50msNo1 255;
BA_ "GenSigStartValue" SG_ 532 CRC_ParkByWire50msNo1 255;
BA_ "CycleTime" SG_ 532 ALIV_ParkByWire50msNo1 50;
BA_ "GenSigTimeoutTime" SG_ 532 ALIV_ParkByWire50msNo1 250;
BA_ "InvalidValue" SG_ 532 ALIV_ParkByWire50msNo1 15;
BA_ "SigFixedValue" SG_ 532 CHL_ParkByWire50msNo1 "10";
BA_ "CycleTime" SG_ 532 CHL_ParkByWire50msNo1 50;
BA_ "GenSigTimeoutTime" SG_ 532 CHL_ParkByWire50msNo1 250;
BA_ "InvalidValue" SG_ 532 CHL_ParkByWire50msNo1 15;
BA_ "GenSigStartValue" SG_ 532 CHL_ParkByWire50msNo1 15;
BA_ "CycleTime" SG_ 532 RequestParkByWireHeat 50;
BA_ "GenSigTimeoutTime" SG_ 532 RequestParkByWireHeat 250;
BA_ "InvalidValue" SG_ 532 RequestParkByWireHeat 15;
BA_ "SigFixedValue" SG_ 630 ST_ENERG_FZM "1";
BA_ "CycleTime" SG_ 630 ST_ENERG_FZM 5000;
BA_ "GenSigTimeoutTime" SG_ 630 ST_ENERG_FZM 25000;
BA_ "InvalidValue" SG_ 630 ST_ENERG_FZM 15;
BA_ "GenSigStartValue" SG_ 630 ST_ENERG_FZM 15;
BA_ "SigFixedValue" SG_ 630 ST_ILK_ERRM_FZM "0";
BA_ "CycleTime" SG_ 630 ST_ILK_ERRM_FZM 5000;
BA_ "GenSigTimeoutTime" SG_ 630 ST_ILK_ERRM_FZM 25000;
BA_ "InvalidValue" SG_ 630 ST_ILK_ERRM_FZM 3;
BA_ "GenSigStartValue" SG_ 630 ST_ILK_ERRM_FZM 3;
BA_ "SigFixedValue" SG_ 632 ST_TRAI "0";
BA_ "CycleTime" SG_ 632 ST_TRAI 5000;
BA_ "GenSigTimeoutTime" SG_ 632 ST_TRAI 25000;
BA_ "InvalidValue" SG_ 632 ST_TRAI 3;
BA_ "GenSigStartValue" SG_ 632 ST_TRAI 3;
BA_ "GenSigTimeoutTime" SG_ 645 OBC_CoolPwrDemand 2500;
BA_ "CycleTime" SG_ 645 OBC_CoolPwrDemand 500;
BA_ "InvalidValue" SG_ 645 OBC_CoolPwrDemand 255;
BA_ "GenSigTimeoutTime" SG_ 645 OBC_FlowRateReq 2500;
BA_ "CycleTime" SG_ 645 OBC_FlowRateReq 500;
BA_ "InvalidValue" SG_ 645 OBC_FlowRateReq 255;
BA_ "GenSigStartValue" SG_ 645 OBC_FlowRateReq 15;
BA_ "GenSigTimeoutTime" SG_ 645 OBC_InternalTemp 2500;
BA_ "CycleTime" SG_ 645 OBC_InternalTemp 500;
BA_ "InvalidValue" SG_ 645 OBC_InternalTemp 4095;
BA_ "GenSigStartValue" SG_ 645 OBC_InternalTemp 500;
BA_ "CycleTime" SG_ 749 TEMP_EX 1000;
BA_ "GenSigTimeoutTime" SG_ 749 TEMP_EX 5000;
BA_ "InvalidValue" SG_ 749 TEMP_EX 255;
BA_ "GenSigStartValue" SG_ 749 TEMP_EX 255;
BA_ "CycleTime" SG_ 811 ActValVolFlowCoolantETractSys1 100;
BA_ "GenSigTimeoutTime" SG_ 811 ActValVolFlowCoolantETractSys1 500;
BA_ "InvalidValue" SG_ 811 ActValVolFlowCoolantETractSys1 255;
BA_ "GenSigStartValue" SG_ 811 ActValVolFlowCoolantETractSys1 255;
BA_ "SigFixedValue" SG_ 811 ActValVolFlowCoolantETractSys1 "600";
BA_ "CycleTime" SG_ 811 ActValVolFlowCoolantETractSys2 100;
BA_ "GenSigTimeoutTime" SG_ 811 ActValVolFlowCoolantETractSys2 500;
BA_ "InvalidValue" SG_ 811 ActValVolFlowCoolantETractSys2 255;
BA_ "GenSigStartValue" SG_ 811 ActValVolFlowCoolantETractSys2 255;
BA_ "SigFixedValue" SG_ 811 ActValVolFlowCoolantETractSys2 "600";
BA_ "CycleTime" SG_ 832 ALIV_CombinedChargerUnit100msNo1 100;
BA_ "GenSigTimeoutTime" SG_ 832 ALIV_CombinedChargerUnit100msNo1 500;
BA_ "InvalidValue" SG_ 832 ALIV_CombinedChargerUnit100msNo1 255;
BA_ "SigFixedValue" SG_ 832 RequestPowerETractSys1Loss "0";
BA_ "CycleTime" SG_ 832 RequestPowerETractSys1Loss 100;
BA_ "GenSigTimeoutTime" SG_ 832 RequestPowerETractSys1Loss 500;
BA_ "InvalidValue" SG_ 832 RequestPowerETractSys1Loss 63;
BA_ "GenSigStartValue" SG_ 832 RequestPowerETractSys1Loss 63;
BA_ "CycleTime" SG_ 832 CRC_CombinedChargerUnit100msNo1 100;
BA_ "GenSigTimeoutTime" SG_ 832 CRC_CombinedChargerUnit100msNo1 500;
BA_ "InvalidValue" SG_ 832 CRC_CombinedChargerUnit100msNo1 255;
BA_ "GenSigStartValue" SG_ 832 CRC_CombinedChargerUnit100msNo1 255;
BA_ "SigFixedValue" SG_ 832 RequestPowerETractSys2Loss "0";
BA_ "CycleTime" SG_ 832 RequestPowerETractSys2Loss 100;
BA_ "GenSigTimeoutTime" SG_ 832 RequestPowerETractSys2Loss 500;
BA_ "InvalidValue" SG_ 832 RequestPowerETractSys2Loss 63;
BA_ "GenSigStartValue" SG_ 832 RequestPowerETractSys2Loss 63;
BA_ "GenSigSendType" SG_ 896 NO_VECH_7 1;
BA_ "SigFixedValue" SG_ 896 NO_VECH_7 "48";
BA_ "CycleTime" SG_ 896 NO_VECH_7 100;
BA_ "GenSigTimeoutTime" SG_ 896 NO_VECH_7 500;
BA_ "InvalidValue" SG_ 896 NO_VECH_7 255;
BA_ "GenSigStartValue" SG_ 896 NO_VECH_7 255;
BA_ "GenSigSendType" SG_ 896 NO_VECH_6 1;
BA_ "SigFixedValue" SG_ 896 NO_VECH_6 "48";
BA_ "CycleTime" SG_ 896 NO_VECH_6 100;
BA_ "GenSigTimeoutTime" SG_ 896 NO_VECH_6 500;
BA_ "InvalidValue" SG_ 896 NO_VECH_6 255;
BA_ "GenSigStartValue" SG_ 896 NO_VECH_6 255;
BA_ "GenSigSendType" SG_ 896 NO_VECH_5 1;
BA_ "SigFixedValue" SG_ 896 NO_VECH_5 "48";
BA_ "CycleTime" SG_ 896 NO_VECH_5 100;
BA_ "GenSigTimeoutTime" SG_ 896 NO_VECH_5 500;
BA_ "InvalidValue" SG_ 896 NO_VECH_5 255;
BA_ "GenSigStartValue" SG_ 896 NO_VECH_5 255;
BA_ "GenSigSendType" SG_ 896 NO_VECH_4 1;
BA_ "SigFixedValue" SG_ 896 NO_VECH_4 "48";
BA_ "CycleTime" SG_ 896 NO_VECH_4 100;
BA_ "GenSigTimeoutTime" SG_ 896 NO_VECH_4 500;
BA_ "InvalidValue" SG_ 896 NO_VECH_4 255;
BA_ "GenSigStartValue" SG_ 896 NO_VECH_4 255;
BA_ "GenSigSendType" SG_ 896 NO_VECH_1 1;
BA_ "SigFixedValue" SG_ 896 NO_VECH_1 "48";
BA_ "CycleTime" SG_ 896 NO_VECH_1 100;
BA_ "GenSigTimeoutTime" SG_ 896 NO_VECH_1 500;
BA_ "InvalidValue" SG_ 896 NO_VECH_1 255;
BA_ "GenSigStartValue" SG_ 896 NO_VECH_1 255;
BA_ "GenSigSendType" SG_ 896 NO_VECH_2 1;
BA_ "SigFixedValue" SG_ 896 NO_VECH_2 "48";
BA_ "CycleTime" SG_ 896 NO_VECH_2 100;
BA_ "GenSigTimeoutTime" SG_ 896 NO_VECH_2 500;
BA_ "InvalidValue" SG_ 896 NO_VECH_2 255;
BA_ "GenSigStartValue" SG_ 896 NO_VECH_2 255;
BA_ "GenSigSendType" SG_ 896 NO_VECH_3 1;
BA_ "SigFixedValue" SG_ 896 NO_VECH_3 "48";
BA_ "CycleTime" SG_ 896 NO_VECH_3 100;
BA_ "GenSigTimeoutTime" SG_ 896 NO_VECH_3 500;
BA_ "InvalidValue" SG_ 896 NO_VECH_3 255;
BA_ "GenSigStartValue" SG_ 896 NO_VECH_3 255;
BA_ "SigFixedValue" SG_ 911 QU_AVL_LOGR_RW "2";
BA_ "CycleTime" SG_ 911 QU_AVL_LOGR_RW 100;
BA_ "GenSigTimeoutTime" SG_ 911 QU_AVL_LOGR_RW 500;
BA_ "InvalidValue" SG_ 911 QU_AVL_LOGR_RW 15;
BA_ "GenSigStartValue" SG_ 911 QU_AVL_LOGR_RW 15;
BA_ "CycleTime" SG_ 911 ALIV_TLT_RW 100;
BA_ "GenSigTimeoutTime" SG_ 911 ALIV_TLT_RW 500;
BA_ "InvalidValue" SG_ 911 ALIV_TLT_RW 15;
BA_ "CycleTime" SG_ 911 CRC_TLT_RW 100;
BA_ "GenSigTimeoutTime" SG_ 911 CRC_TLT_RW 500;
BA_ "InvalidValue" SG_ 911 CRC_TLT_RW 255;
BA_ "GenSigStartValue" SG_ 911 CRC_TLT_RW 255;
BA_ "SigFixedValue" SG_ 911 AVL_LOGR_RW "0";
BA_ "CycleTime" SG_ 911 AVL_LOGR_RW 100;
BA_ "GenSigTimeoutTime" SG_ 911 AVL_LOGR_RW 500;
BA_ "GenSigStartValue" SG_ 911 AVL_LOGR_RW 4095;
BA_ "SigFixedValue" SG_ 1052 MILE_KM "0";
BA_ "CycleTime" SG_ 1052 MILE_KM 10000;
BA_ "GenSigTimeoutTime" SG_ 1052 MILE_KM 50000;
BA_ "InvalidValue" SG_ 1052 MILE_KM 16777215;
BA_ "GenSigStartValue" SG_ 1052 MILE_KM 16777215;
BA_ "CycleTime" SG_ 1090 T_SEC_COU_REL 1000;
BA_ "GenSigTimeoutTime" SG_ 1090 T_SEC_COU_REL 5000;
BA_ "GenSigStartValue" SG_ 1090 T_SEC_COU_REL 4294967295;
BA_ "CycleTime" SG_ 1107 StsDisconnectingSwtHighVoltStorg 200;
BA_ "GenSigTimeoutTime" SG_ 1107 StsDisconnectingSwtHighVoltStorg 1000;
BA_ "InvalidValue" SG_ 1107 StsDisconnectingSwtHighVoltStorg 63;
BA_ "GenSigStartValue" SG_ 1107 StsDisconnectingSwtHighVoltStorg 63;
BA_ "SigFixedValue" SG_ 1107 StatusServiceDisconnectionPlug "2";
BA_ "CycleTime" SG_ 1107 StatusServiceDisconnectionPlug 200;
BA_ "GenSigTimeoutTime" SG_ 1107 StatusServiceDisconnectionPlug 1000;
BA_ "InvalidValue" SG_ 1107 StatusServiceDisconnectionPlug 3;
BA_ "GenSigStartValue" SG_ 1107 StatusServiceDisconnectionPlug 3;
BA_ "SigFixedValue" SG_ 1120 EnergyStorageClamp30VoltageValue "13.7";
BA_ "CycleTime" SG_ 1120 EnergyStorageClamp30VoltageValue 200;
BA_ "GenSigTimeoutTime" SG_ 1120 EnergyStorageClamp30VoltageValue 1000;
BA_ "InvalidValue" SG_ 1120 EnergyStorageClamp30VoltageValue 65535;
BA_ "GenSigStartValue" SG_ 1120 EnergyStorageClamp30VoltageValue 65535;
BA_ "CycleTime" SG_ 1237 TempETractSys1DirectCurrentPlug 1000;
BA_ "GenSigTimeoutTime" SG_ 1237 TempETractSys1DirectCurrentPlug 5000;
BA_ "InvalidValue" SG_ 1237 TempETractSys1DirectCurrentPlug 511;
BA_ "GenSigStartValue" SG_ 1237 TempETractSys1DirectCurrentPlug 511;
BA_ "CycleTime" SG_ 1237 StatusCrashShutDownETractSys1 1000;
BA_ "GenSigTimeoutTime" SG_ 1237 StatusCrashShutDownETractSys1 5000;
BA_ "InvalidValue" SG_ 1237 StatusCrashShutDownETractSys1 15;
BA_ "GenSigStartValue" SG_ 1237 StatusCrashShutDownETractSys1 15;
BA_ "SigFixedValue" SG_ 1237 CHL_StatusCrashIdentETractSys1 "12";
BA_ "CycleTime" SG_ 1237 CHL_StatusCrashIdentETractSys1 1000;
BA_ "GenSigTimeoutTime" SG_ 1237 CHL_StatusCrashIdentETractSys1 5000;
BA_ "InvalidValue" SG_ 1237 CHL_StatusCrashIdentETractSys1 15;
BA_ "GenSigStartValue" SG_ 1237 CHL_StatusCrashIdentETractSys1 15;
BA_ "CycleTime" SG_ 1237 ALIV_StatusCrashIdentETractSys1 1000;
BA_ "GenSigTimeoutTime" SG_ 1237 ALIV_StatusCrashIdentETractSys1 5000;
BA_ "InvalidValue" SG_ 1237 ALIV_StatusCrashIdentETractSys1 15;
BA_ "CycleTime" SG_ 1237 CRC_StatusCrashIdentETractSys1 1000;
BA_ "GenSigTimeoutTime" SG_ 1237 CRC_StatusCrashIdentETractSys1 5000;
BA_ "InvalidValue" SG_ 1237 CRC_StatusCrashIdentETractSys1 255;
BA_ "GenSigStartValue" SG_ 1237 CRC_StatusCrashIdentETractSys1 255;
BA_ "CycleTime" SG_ 1237 StsLimpHomeNotifETractSys1 1000;
BA_ "GenSigTimeoutTime" SG_ 1237 StsLimpHomeNotifETractSys1 5000;
BA_ "InvalidValue" SG_ 1237 StsLimpHomeNotifETractSys1 63;
BA_ "GenSigStartValue" SG_ 1237 StsLimpHomeNotifETractSys1 63;
BA_ "CycleTime" SG_ 1239 ALIV_StatusCrashIdentETractSys2 1000;
BA_ "GenSigTimeoutTime" SG_ 1239 ALIV_StatusCrashIdentETractSys2 5000;
BA_ "InvalidValue" SG_ 1239 ALIV_StatusCrashIdentETractSys2 15;
BA_ "SigFixedValue" SG_ 1239 CHL_StatusCrashIdentETractSys2 "15";
BA_ "CycleTime" SG_ 1239 CHL_StatusCrashIdentETractSys2 1000;
BA_ "GenSigTimeoutTime" SG_ 1239 CHL_StatusCrashIdentETractSys2 5000;
BA_ "InvalidValue" SG_ 1239 CHL_StatusCrashIdentETractSys2 15;
BA_ "GenSigStartValue" SG_ 1239 CHL_StatusCrashIdentETractSys2 15;
BA_ "CycleTime" SG_ 1239 StatusCrashShutDownETractSys2 1000;
BA_ "GenSigTimeoutTime" SG_ 1239 StatusCrashShutDownETractSys2 5000;
BA_ "InvalidValue" SG_ 1239 StatusCrashShutDownETractSys2 15;
BA_ "GenSigStartValue" SG_ 1239 StatusCrashShutDownETractSys2 15;
BA_ "CycleTime" SG_ 1239 TempETractSys2DirectCurrentPlug 1000;
BA_ "GenSigTimeoutTime" SG_ 1239 TempETractSys2DirectCurrentPlug 5000;
BA_ "InvalidValue" SG_ 1239 TempETractSys2DirectCurrentPlug 511;
BA_ "GenSigStartValue" SG_ 1239 TempETractSys2DirectCurrentPlug 511;
BA_ "CycleTime" SG_ 1239 StsLimpHomeNotifETractSys2 1000;
BA_ "GenSigTimeoutTime" SG_ 1239 StsLimpHomeNotifETractSys2 5000;
BA_ "InvalidValue" SG_ 1239 StsLimpHomeNotifETractSys2 63;
BA_ "GenSigStartValue" SG_ 1239 StsLimpHomeNotifETractSys2 63;
BA_ "CycleTime" SG_ 1239 CRC_StatusCrashIdentETractSys2 1000;
BA_ "GenSigTimeoutTime" SG_ 1239 CRC_StatusCrashIdentETractSys2 5000;
BA_ "InvalidValue" SG_ 1239 CRC_StatusCrashIdentETractSys2 255;
BA_ "GenSigStartValue" SG_ 1239 CRC_StatusCrashIdentETractSys2 255;
BA_ "CycleTime" SG_ 1272 TemperatureCoolantOutput 1000;
BA_ "GenSigTimeoutTime" SG_ 1272 TemperatureCoolantOutput 5000;
BA_ "InvalidValue" SG_ 1272 TemperatureCoolantOutput 4095;
BA_ "GenSigStartValue" SG_ 1272 TemperatureCoolantOutput 4095;
BA_ "SigFixedValue" SG_ 1296 NM3ControlBitVector "64";
BA_ "CycleTime" SG_ 1296 NM3ControlBitVector 100;
BA_ "GenSigTimeoutTime" SG_ 1296 NM3ControlBitVector 500;
BA_ "InvalidValue" SG_ 1296 NM3ControlBitVector 255;
BA_ "GenSigStartValue" SG_ 1296 NM3ControlBitVector 255;
BA_ "SigFixedValue" SG_ 1296 NM3SenderECUId "16";
BA_ "CycleTime" SG_ 1296 NM3SenderECUId 100;
BA_ "GenSigTimeoutTime" SG_ 1296 NM3SenderECUId 500;
BA_ "InvalidValue" SG_ 1296 NM3SenderECUId 255;
BA_ "GenSigStartValue" SG_ 1296 NM3SenderECUId 255;
BA_ "SigFixedValue" SG_ 1296 NM3BasePartialNetworks "0";
BA_ "CycleTime" SG_ 1296 NM3BasePartialNetworks 100;
BA_ "GenSigTimeoutTime" SG_ 1296 NM3BasePartialNetworks 500;
BA_ "InvalidValue" SG_ 1296 NM3BasePartialNetworks 65535;
BA_ "GenSigStartValue" SG_ 1296 NM3BasePartialNetworks 65535;
BA_ "SigFixedValue" SG_ 1296 NM3FunctionalPartialNetworks "98304";
BA_ "CycleTime" SG_ 1296 NM3FunctionalPartialNetworks 100;
BA_ "GenSigTimeoutTime" SG_ 1296 NM3FunctionalPartialNetworks 500;
BA_ "GenSigStartValue" SG_ 1296 NM3FunctionalPartialNetworks 4294967295;
BA_ "GenSigSendType" SG_ 1562 OBC_DiagResp_Byte1 7;
BA_ "GenSigSendType" SG_ 1562 OBC_DiagResp_Byte5 7;
BA_ "GenSigSendType" SG_ 1562 OBC_DiagResp_Byte4 7;
BA_ "GenSigSendType" SG_ 1562 OBC_DiagResp_Byte3 7;
BA_ "GenSigSendType" SG_ 1562 OBC_DiagResp_Byte2 7;
BA_ "GenSigSendType" SG_ 1562 OBC_DiagResp_Byte0 7;
BA_ "GenSigSendType" SG_ 1562 OBC_DiagResp_Byte7 7;
BA_ "GenSigSendType" SG_ 1562 OBC_DiagResp_Byte6 7;
BA_ "GenSigSendType" SG_ 1669 VCU_DiagResp_Byte1 7;
BA_ "GenSigSendType" SG_ 1669 VCU_DiagResp_Byte5 7;
BA_ "GenSigSendType" SG_ 1669 VCU_DiagResp_Byte4 7;
BA_ "GenSigSendType" SG_ 1669 VCU_DiagResp_Byte3 7;
BA_ "GenSigSendType" SG_ 1669 VCU_DiagResp_Byte2 7;
BA_ "GenSigSendType" SG_ 1669 VCU_DiagResp_Byte0 7;
BA_ "GenSigSendType" SG_ 1669 VCU_DiagResp_Byte7 7;
BA_ "GenSigSendType" SG_ 1669 VCU_DiagResp_Byte6 7;
BA_ "GenSigSendType" SG_ 1585 DCDC_DiagResp_Byte7 7;
BA_ "GenSigSendType" SG_ 1585 DCDC_DiagResp_Byte5 7;
BA_ "GenSigSendType" SG_ 1585 DCDC_DiagResp_Byte4 7;
BA_ "GenSigSendType" SG_ 1585 DCDC_DiagResp_Byte3 7;
BA_ "GenSigSendType" SG_ 1585 DCDC_DiagResp_Byte2 7;
BA_ "GenSigSendType" SG_ 1585 DCDC_DiagResp_Byte1 7;
BA_ "GenSigSendType" SG_ 1585 DCDC_DiagResp_Byte0 7;
BA_ "GenSigSendType" SG_ 1585 DCDC_DiagResp_Byte6 7;
BA_ "GenSigSendType" SG_ 1690 OBC_DiagReq_Byte0 7;
BA_ "GenSigSendType" SG_ 1690 OBC_DiagReq_Byte1 7;
BA_ "GenSigSendType" SG_ 1690 OBC_DiagReq_Byte2 7;
BA_ "GenSigSendType" SG_ 1690 OBC_DiagReq_Byte3 7;
BA_ "GenSigSendType" SG_ 1690 OBC_DiagReq_Byte4 7;
BA_ "GenSigSendType" SG_ 1690 OBC_DiagReq_Byte5 7;
BA_ "GenSigSendType" SG_ 1690 OBC_DiagReq_Byte6 7;
BA_ "GenSigSendType" SG_ 1690 OBC_DiagReq_Byte7 7;
BA_ "GenSigSendType" SG_ 1668 VCU_DiagReq_Byte0 7;
BA_ "GenSigSendType" SG_ 1668 VCU_DiagReq_Byte1 7;
BA_ "GenSigSendType" SG_ 1668 VCU_DiagReq_Byte2 7;
BA_ "GenSigSendType" SG_ 1668 VCU_DiagReq_Byte3 7;
BA_ "GenSigSendType" SG_ 1668 VCU_DiagReq_Byte4 7;
BA_ "GenSigSendType" SG_ 1668 VCU_DiagReq_Byte5 7;
BA_ "GenSigSendType" SG_ 1668 VCU_DiagReq_Byte6 7;
BA_ "GenSigSendType" SG_ 1668 VCU_DiagReq_Byte7 7;
BA_ "GenSigTimeoutTime" SG_ 1156 DCDC_Internal_Debug_Msg_Byte_0 500;
BA_ "GenSigTimeoutTime" SG_ 1156 DCDC_Internal_Debug_Msg_Byte_1 500;
BA_ "GenSigTimeoutTime" SG_ 1156 DCDC_Internal_Debug_Msg_Byte_2 500;
BA_ "GenSigTimeoutTime" SG_ 1156 DCDC_Internal_Debug_Msg_Byte_3 500;
BA_ "GenSigTimeoutTime" SG_ 1156 DCDC_Internal_Debug_Msg_Byte_4 500;
BA_ "GenSigTimeoutTime" SG_ 1156 DCDC_Internal_Debug_Msg_Byte_5 500;
BA_ "GenSigTimeoutTime" SG_ 1156 DCDC_Internal_Debug_Msg_Byte_6 500;
BA_ "GenSigTimeoutTime" SG_ 1156 DCDC_Internal_Debug_Msg_Byte_7 500;
BA_ "GenSigTimeoutTime" SG_ 1160 OBC_Internal_Debug_Msg_Byte_0 500;
BA_ "GenSigTimeoutTime" SG_ 1160 OBC_Internal_Debug_Msg_Byte_1 500;
BA_ "GenSigTimeoutTime" SG_ 1160 OBC_Internal_Debug_Msg_Byte_2 500;
BA_ "GenSigTimeoutTime" SG_ 1160 OBC_Internal_Debug_Msg_Byte_3 500;
BA_ "GenSigTimeoutTime" SG_ 1160 OBC_Internal_Debug_Msg_Byte_4 500;
BA_ "GenSigTimeoutTime" SG_ 1160 OBC_Internal_Debug_Msg_Byte_5 500;
BA_ "GenSigTimeoutTime" SG_ 1160 OBC_Internal_Debug_Msg_Byte_6 500;
BA_ "GenSigTimeoutTime" SG_ 1160 OBC_Internal_Debug_Msg_Byte_7 500;
BA_ "GenSigSendType" SG_ 1713 DCDC_DiagReq_Byte7 7;
BA_ "GenSigSendType" SG_ 1713 DCDC_DiagReq_Byte6 7;
BA_ "GenSigSendType" SG_ 1713 DCDC_DiagReq_Byte5 7;
BA_ "GenSigSendType" SG_ 1713 DCDC_DiagReq_Byte0 7;
BA_ "GenSigSendType" SG_ 1713 DCDC_DiagReq_Byte3 7;
BA_ "GenSigSendType" SG_ 1713 DCDC_DiagReq_Byte2 7;
BA_ "GenSigSendType" SG_ 1713 DCDC_DiagReq_Byte4 7;
BA_ "GenSigSendType" SG_ 1713 DCDC_DiagReq_Byte1 7;
VAL_ 293 PowerETractSys1LimMotMax 65533 "Func_interface_is_not_avail" 65534 "Function_reports_error" 65535 "Signal_unfilled" ;
VAL_ 293 PowerETractSys1LimGenMax 65533 "Func_interface_is_not_avail" 65534 "Function_reports_error" 65535 "Signal_unfilled" ;
VAL_ 293 PowerETractSys2LimGenMax 65533 "Func_interface_is_not_avail" 65534 "Function_reports_error" 65535 "Signal_unfilled" ;
VAL_ 293 OperatingModeEANActualValue 0 "initialization" 1 "E_motor_off" 2 "E_motor_standby" 3 "E_motor_ready to drive" 4 "loading" 5 "E_Drive_Shut_Off_Path_Test" 6 "E_drive_shtdwn_ISO_msrmt" 7 "E_drive_shtdwn_0_electricity" 8 "No_release_eDrive_EWS_lock" 9 "Critical_tailgate_open" 15 "E_drive_error" 253 "Func_interface_is_not_avail" 254 "Function_reports_error" 255 "signal_unfilled" ;
VAL_ 293 PowerETractSys2LimMotMax 65533 "Func_interface_is_not_avail" 65534 "Function_reports_error" 65535 "Signal_unfilled" ;
VAL_ 293 RequestExtraBoostETractSys2 0 "No_boost_requested" 1 "Boost_requested" 3 "signal_unfilled" ;
VAL_ 293 RequestExtraBoostETractSys1 0 "No_boost_requested" 1 "Boost_requested" 3 "signal_unfilled" ;
VAL_ 296 TAR_RPM_MAX_FTAX 65533 "Func_interface_is_not_avail" 65534 "Function_reports_error" 65535 "Signal_unfilled" ;
VAL_ 296 TAR_RPM_MIN_FTAX 65533 "Func_interface_is_not_avail" 65534 "Function_reports_error" 65535 "Signal_unfilled" ;
VAL_ 296 ST_TAR_RPM_FTAX 3 "Speed_limit_lower_thresh_active" 0 "speed_limit_upr_thresh_passive" 1 "speed_limit_lwr_thresh_passive" 2 "speed_limit_upper_thresh_active" 4 "fallback level" 13 "Func_interface_is_not_available" 14 "Function_reports_error" 15 "Signal_unfilled" ;
VAL_ 296 StatusSlipThresholdsFrontAxle 0 "slip_limit_not_exceeded" 1 "lower_slip_limit_exceed_comfort" 2 "Lower_slip_limit_exceed_warning" 3 "Lower_slip_limit_exceed_critical" 5 "Upper_slip_limit_exceed_comfort" 6 "Upper_slip_limit_exceed_warning" 7 "Upper_slip_limit_exceed_critical" 13 "Func_interface_not_available" 14 "Function_reports_error" 15 "signal_unfilled" ;
VAL_ 296 StatusSlipThresholdsRearAxle 0 "slip_limit_not_exceeded" 1 "lower_slip_limit_exceed_comfort" 2 "Lower_slip_limit_exceed_warning" 3 "Lower_slip_limit_exceed_critical" 5 "Upper_slip_limit_exceed_comfort" 6 "Upper_slip_limit_exceed_warning" 7 "Upper_slip_limit_exceed_critical" 13 "Func_interface_not_available" 14 "Function_reports_error" 15 "signal_unfilled" ;
VAL_ 296 AVL_BRTORQ_WHL_FS_LH_EXT 65533 "Func_interface_is_not_available" 65534 "Function_reports_error" 65535 "Signal_unfilled" ;
VAL_ 296 AVL_BRTORQ_WHL_FS_RH_EXT 65533 "Func_interface_is_not_available" 65534 "Function_reports_error" 65535 "Signal_unfilled" ;
VAL_ 296 TAR_RPM_MAX_BAX 65533 "Func_interface_is_not_avail" 65534 "Function_reports_error" 65535 "Signal_unfilled" ;
VAL_ 296 TAR_RPM_MIN_BAX 65533 "Func_interface_is_not_avail" 65534 "Function_reports_error" 65535 "Signal_unfilled" ;
VAL_ 296 ST_TAR_RPM_BAX 3 "Speed_limit_lwr_thresh_active" 0 "speed_limit_upr_thresh_notactive" 1 "speed_limit_lwr_thresh_notactive" 2 "speed_limit_upr_thresh_active" 4 "fallback level" 13 "Func_interface_is_not_available" 14 "Function_reports_error" 15 "Signal_unfilled" ;
VAL_ 296 TAR_STIF_SPCO 13 "Reserved Not Available" 14 "Reserved error" 15 "signal_unfilled" ;
VAL_ 296 AVL_BRTORQ_WHL_RS_RH_EXT 65533 "Func_interface_is_not_available" 65534 "Function_reports_error" 65535 "Signal_unfilled" ;
VAL_ 296 AVL_BRTORQ_WHL_RS_LH_EXT 65533 "Func_interface_is_not_available" 65534 "Function_reports_error" 65535 "Signal_unfilled" ;
VAL_ 297 QU_ACLNY_COG 1 "Sig val valid secured plausible" 2 "Signal value is valid" 3 "Signal quality or monit restrict" 4 "Reserved" 6 "Signal value is invalid" 7 "Reserved" 8 "Initialization" 9 "sig val valid secured stat temp" 10 "signal val valid, cond stat temp" 11 "Signal quality restrict, temp" 12 "Sub val set signal stat temp" 14 "Signal value invalid stat temp" 15 "Signal invalid" ;
VAL_ 297 QU_ACLNX_COG 1 "Reserved" 2 "Signal value is valid" 3 "Signal quality or monit restrict" 4 "Reserved" 6 "Signal value is invalid" 7 "Reserved" 8 "Initialization" 9 "signal valid secure stat temp" 10 "signal val valid, cond stat temp" 11 "Signal quality restrict temp" 12 "Sub val set signal stat temp" 14 "Signal value invalid stat temp" 15 "Signal invalid" ;
VAL_ 314 StatusETractSys1Degradation -1 "Signal_unfilled" -2 "Function_reports_error" -3 "Func interface_is_not_avail" ;
VAL_ 314 TETractSys1InverterActVal 253 "Func_interface_is_not_avail" 254 "Function_reports_error" 255 "signal_unfilled" ;
VAL_ 314 TETractSys1EmStatorActVal 253 "Func_interface_is_not_avail" 254 "Function_reports_error" 255 "signal_unfilled" ;
VAL_ 314 ThermalStressLevelETractSys1 253 "Func_interface_is_not_avail" 254 "Function_reports_error" 255 "signal_unfilled" ;
VAL_ 314 TETractSys1EmRotorActVal 253 "Func_interface_is_not_avail" 254 "Function_reports_error" 255 "signal_unfilled" ;
VAL_ 314 StatusExtraBoostETractSys1 0 "Boost_not_possible" 1 "Boost_possible" 3 "signal_unfilled" ;
VAL_ 314 PercentUsedExtraBoostETractSys1 1021 "Func_interface_is_not_avail" 1022 "Function_reports_error" 1023 "Signal_unfilled" ;
VAL_ 314 TETractSys1GbxOilActVal 253 "Func_interface_is_not_avail" 254 "Function_reports_error" 255 "signal_unfilled" ;
VAL_ 314 WhlRatElAxlEtractSys1ActVal 65533 "Func_interface_is_not_avail" 65534 "Function_reports_error" 65535 "signal_unfilled" ;
VAL_ 314 StatusETractSys1LossActive 0 "trimming_off" 1 "trim_on" 2 "Trimming_enabled" 13 "Func_interface_is_not_avail" 14 "Function_reports_error" 15 "Signal_unfilled" ;
VAL_ 314 OpModETractSys1ActVal 0 "standby" 1 "Torque control" 2 "zero torque control" 3 "DC_Voltage Control" 5 "Speed ctrl_with_torque pre ctrl" 6 "IHVBCTL_with_torque pre-control" 7 "VoKo_trimming" 8 "Insulation test" 10 "Freewheel" 11 "HEAT_is_initialized" 12 "Failed_safe_st_ext_req_safe_st" 13 "Initialization" 14 "DC link pre-charge" 15 "Intermediate circuit discharge" 16 "Crash_KL30C_Shutdown" 20 "Learning_active" 21 "Locked_Standby" 22 "Works job_controlled" 30 "Shut_off_path_test_running" 31 "Shut_off_path_test_completed" 32 "Shut_off_path_test_aborted" 33 "Spt_laeuft_HV_Zuschalt_freifrei" 40 "Factory mode_active" 186 "speed control" 253 "Func_interface_is_not_avail" 254 "Function_reports_error" 255 "signal_unfilled" ;
VAL_ 314 StatusETractSys1CoolingActVal 0 "low temperature shutdown" 1 "Performance restriction_too_cold" 2 "power restriction_cold" 3 "thermal_utilization_0_percent" 4 "thermal_utilization_25_percent" 5 "thermal_utilization_50_percent" 6 "thermal_utilization_65_percent" 7 "thermal_utilization_80_percent" 8 "thermal_utilization_90_percent" 9 "thermal_utilization_95_percent" 10 "thermal_utilization_98_percent" 11 "thermal_utilization_100_percent" 12 "Overtemperature shutdown" 13 "Func_interface_is_not_avail" 14 "Function_reports_error" 15 "signal_unfilled" ;
VAL_ 314 TETractSys1CoolantWaterInpActVal 253 "Func_interface_is_not_avail" 254 "Function_reports_error" 255 "signal_unfilled" ;
VAL_ 314 ActStatMeclLossesGbxETractSys1 4093 "Func_interface_is_not_avail" 4094 "Function_reports_error" 4095 "Signal_unfilled" ;
VAL_ 314 PowerETractSys1MaximumLossActive 1021 "Func_interface_is_not_avail" 1022 "Function_reports_error" 1023 "Signal_unfilled" ;
VAL_ 326 StatusETractSys2Degradation -1 "Signal_unfilled" -2 "Function_reports_error" -3 "Func interface_is_not_avail" ;
VAL_ 326 ActStatMeclLossesGbxETractSys2 4093 "Func_interface_is_not_avail" 4094 "Function_reports_error" 4095 "Signal_unfilled" ;
VAL_ 326 TETractSys2CoolantWaterInpActVal 253 "Func_interface_is_not_avail" 254 "Function_reports_error" 255 "signal_unfilled" ;
VAL_ 326 OpModETractSys2ActVal 0 "standby" 1 "Torque control" 2 "zero torque control" 3 "DC_Voltage Control" 5 "Speed ctrl_with_torque pre ctrl" 6 "IHVBCTL_with_torque pre-control" 7 "VoKo_trimming" 8 "Insulation test" 10 "Freewheel" 11 "HEAT_is_initialized" 12 "Failed_safe_st_ext_req_safe_st" 13 "Initialization" 14 "DC link pre-charge" 15 "Intermediate circuit discharge" 16 "Crash_KL30C_Shutdown" 20 "Learning_active" 21 "Locked_Standby" 22 "Works job_controlled" 30 "Shut_off_path_test_running" 31 "Shut_off_path_test_completed" 32 "Shut_off_path_test_aborted" 33 "Spt_laeuft_HV_Zuschalt_freifrei" 40 "Factory mode_active" 186 "speed control" 253 "Func_interface_is_not_avail" 254 "Function_reports_error" 255 "signal_unfilled" ;
VAL_ 326 StatusETractSys2LossActive 0 "trimming_off" 1 "trim_on" 2 "Trimming_enabled" 13 "Func_interface_is_not_avail" 14 "Function_reports_error" 15 "Signal_unfilled" ;
VAL_ 326 PowerETractSys2MaximumLossActive 1021 "Func_interface_is_not_avail" 1022 "Function_reports_error" 1023 "Signal_unfilled" ;
VAL_ 326 WhlRatElAxlEtractSys2ActVal 65533 "Func_interface_is_not_avail" 65534 "Function_reports_error" 65535 "signal_unfilled" ;
VAL_ 326 PercentUsedExtraBoostETractSys2 1021 "Func_interface_is_not_avail" 1022 "Function_reports_error" 1023 "Signal_unfilled" ;
VAL_ 326 StatusETractSys2CoolingActVal 0 "low temperature shutdown" 1 "Performance restriction_too_cold" 2 "power restriction_cold" 3 "thermal_utilization_0_percent" 4 "thermal_utilization_25_percent" 5 "thermal_utilization_50_percent" 6 "thermal_utilization_65_percent" 7 "thermal_utilization_80_percent" 8 "thermal_utilization_90_percent" 9 "thermal_utilization_95_percent" 10 "thermal_utilization_98_percent" 11 "thermal_utilization_100_percent" 12 "Overtemperature shutdown" 13 "Func_interface_is_not_avail" 14 "Function_reports_error" 15 "signal_unfilled" ;
VAL_ 326 TETractSys2EmRotorActVal 253 "Func_interface_is_not_avail" 254 "Function_reports_error" 255 "signal_unfilled" ;
VAL_ 326 ThermalStressLevelETractSys2 253 "Func_interface_is_not_avail" 254 "Function_reports_error" 255 "signal_unfilled" ;
VAL_ 326 TETractSys2EmStatorActVal 253 "Func_interface_is_not_avail" 254 "Function_reports_error" 255 "signal_unfilled" ;
VAL_ 326 TETractSys2InverterActVal 253 "Func_interface_is_not_avail" 254 "Function_reports_error" 255 "signal_unfilled" ;
VAL_ 326 TETractSys2GbxOilActVal 253 "Func_interface_is_not_avail" 254 "Function_reports_error" 255 "signal_unfilled" ;
VAL_ 326 StatusExtraBoostETractSys2 0 "Boost_not_possible" 1 "Boost_possible" 3 "signal_unfilled" ;
VAL_ 385 VCU_BMS_ActCoolingSts 0 "Turned Off" 1 "Turned On" ;
VAL_ 385 VCU_BMS_HeatingSts 0 "Turned Off" 1 "Turned On PTC" 2 "Turned on Heat-pump" ;
VAL_ 405 OBC_VCU_Status 0 "Normal" 1 "De-Rating" 2 "Fault" 3 "Invalid Signal" ;
VAL_ 193 VCU_ChgDirType 15 "Invalid" 14 "Reserved" 13 "Reserved" 12 "Reserved" 11 "Reserved" 10 "Reserved" 9 "Reserved" 8 "Reserved" 7 "Reserved" 6 "Reserved" 5 "Reserved" 4 "Reserved" 3 "Reserved" 2 "Discharging" 1 "Charging" 0 "Default" ;
VAL_ 193 VCU_OBC_Enable 3 "Signal Invalid" 2 "Reserved" 0 "Off" 1 "On" ;
VAL_ 419 BMS_VCU_InsulationMonSts 0 "ON" 1 "OFF (Insulation res func)" ;
VAL_ 420 VCU_BMS_InsulationMonReq 0 "On" 1 "forbid insulation resist func" ;
VAL_ 420 VCU_BMS_ChargeAllow 0 "Not allow" 1 "Allow" ;
VAL_ 424 BMS_VCU_HeatingOnOffReq 0 "OFF" 1 "ON" ;
VAL_ 424 BMS_VCU_CoolingOnOffReq 0 "OFF" 1 "ON" ;
VAL_ 433 VCU_BMS_HVOnOffReq 0 "forbid" 1 "allow" ;
VAL_ 490 MILE_KM_TOT -1 "Signal_unfilled" -2 "Function_reports_error" -3 "Value_not_available" ;
VAL_ 197 VCU_EnableDCDC 1 "Enabled" 0 "Disabled" ;
VAL_ 517 BMS_ContactorAging 0 "Normal" 1 "Warning counter reach 90%" 2 "Fault counter reach 98%" ;
VAL_ 532 RequestParkByWireHeat 0 "initialize" 1 "lock Park Lock" 2 "unlock Park Lock" 3 "no_action" 13 "Func_interface_is_not_avail" 14 "Function_reports_error" 15 "Signal_unfilled" ;
VAL_ 630 ST_ENERG_FZM 0 "ENSTATE_GOOD" 1 "ENSTATE_OK" 2 "ENSTATE_SHORTAGE" 3 "ENSTATE_SEVERE_SHORTAGE" 15 "Signal invalid" ;
VAL_ 630 ST_ILK_ERRM_FZM 0 "Error memory enable" 1 "Error memory lock" 2 "reserve" 3 "signal invalid" ;
VAL_ 632 ST_TRAI 0 "No trailer present" 1 "Trailer present" 3 "signal invalid" ;
VAL_ 811 ActValVolFlowCoolantETractSys1 253 "Func_interface_is_not_avail" 254 "Function_reports_error" 255 "signal_unfilled" ;
VAL_ 811 ActValVolFlowCoolantETractSys2 253 "Func_interface_is_not_avail" 254 "Function_reports_error" 255 "signal_unfilled" ;
VAL_ 832 RequestPowerETractSys1Loss 1021 "Func_interface_is_not_avail" 1022 "Function_reports_error" 1023 "Signal_unfilled" ;
VAL_ 832 RequestPowerETractSys2Loss 1021 "Func_interface_is_not_avail" 1022 "Function_reports_error" 1023 "Signal_unfilled" ;
VAL_ 911 QU_AVL_LOGR_RW 1 "Reserved" 2 "Signal value is valid" 3 "Reserved" 4 "Reserved" 6 "Reserved" 7 "Reserved" 8 "Initialization" 9 "Reserved" 10 "signal val valid, cond stat temp" 11 "Signal quality restrict, temp" 12 "Sub val stat temp" 14 "Signal value invalid stat temp" 15 "Signal invalid" ;
VAL_ 1107 StsDisconnectingSwtHighVoltStorg 0 "HV_OFF" 1 "HV_Precharge" 2 "HV_ON" 4 "positive_path_stick_closed" 8 "negative_path_stick_closed" 16 "Last_opng_contactor_without_diag" 61 "Func_interface_is_not_avail" 62 "Function_reports_error" 63 "signal_unfilled" ;
VAL_ 1107 StatusServiceDisconnectionPlug 1 "Service_Disconnector_open" 2 "Service_Disconnector_closed" 3 "signal_unfilled" ;
VAL_ 1120 EnergyStorageClamp30VoltageValue 65533 "Func_interface_is_not_avail" 65534 "Function_reports_error" 65535 "signal_unfilled" ;
VAL_ 1237 TempETractSys1DirectCurrentPlug 509 "Func_interface_is_not_avail" 510 "Function_reports_error" 511 "signal_unfilled" ;
VAL_ 1237 StatusCrashShutDownETractSys1 0 "crash_function_available" 2 "error_in_test_sequence" 3 "No_test_sequence_received" 4 "Error_in_C_plus_C_minus_Signal" 5 "error_in_crash_function" 13 "Func_interface_is_not_avail" 14 "Function_reports_error" 15 "signal_unfilled" ;
VAL_ 1237 StsLimpHomeNotifETractSys1 0 "No_ASIL_Reduction" 1 "Reduction_to_ASIL_B" 2 "VMAX_constraint" 4 "Shutoff_Path_Test_failed" 8 "Trq capping_restrict_ASIL_Int" 16 "Reserved2" 61 "Func_interface_is_not_avail" 62 "Function_reports_error" 63 "signal_unfilled" ;
VAL_ 1239 StatusCrashShutDownETractSys2 0 "crash_function_available" 2 "error_in_test_sequence" 3 "No_test_sequence_received" 4 "Error_in_C_plus_C_minus_Signal" 5 "error_in_crash_function" 13 "Func_interface_is_not_avail" 14 "Function_reports_error" 15 "signal_unfilled" ;
VAL_ 1239 TempETractSys2DirectCurrentPlug 509 "Func_interface_is_not_avail" 510 "Function_reports_error" 511 "signal_unfilled" ;
VAL_ 1239 StsLimpHomeNotifETractSys2 0 "No_ASIL_Reduction" 1 "Reduction_to_ASIL_B" 2 "VMAX_constraint" 4 "Shutoff_Path_Test_failed" 8 "Trq capping_restrict_ASIL_Int" 16 "Reserved2" 61 "Func_interface_is_not_avail" 62 "Function_reports_error" 63 "signal_unfilled" ;
VAL_ 1272 TemperatureCoolantOutput 4093 "Func_interface_is_not_avail" 4094 "Function_reports_error" 4095 "Signal_unfilled" ;
VAL_ 1296 NM3ControlBitVector 64 "NM_message_contains_subnet_info" 255 "signal_unfilled" ;
VAL_ 1296 NM3SenderECUId 255 "signal_unfilled" ;
VAL_ 1296 NM3BasePartialNetworks 0 "no_communication" 1 "Com parking BN not ok" 2 "Com parking BN OK" 4 "Comstand func cstmr not in FZG" 8 "No_communication" 16 "Com_Living" 32 "No_communication" 64 "Com_Check_Analysis_Diagnose" 128 "Make_ready_to_drive_comm" 256 "No_communication" 512 "Com_Drive" 1024 "No_communication" 2048 "Com_Ready_to_End" 4096 "No_communication" 8192 "No_communication" 65535 "signal_unfilled" ;
VAL_ 1296 NM3FunctionalPartialNetworks 0 "Configuration off" 1 "Configuration on" 2 "Ethernet infrastructure on" 4 "data_comm_on" 8 "remote maintenance_on" 16 "Climate_Base_on" 32 "Safe_Exit_on" 64 "RSU_high-voltage support_on" 128 "Autonomous_Driving_Ready_on" 256 "Air conditioning mode on" 512 "Entertainment mode on" 1024 "External_communication on" 2048 "Entertainmentbetrieb_Fond_ein" 4096 "Assistance_Parking_high on" 8192 "Autonomous_Drv_Sec_Pwr_Supply_on" 16384 "High_volt_batt_air_condition_on" 32768 "Loading" 65536 "Vehicle infrastructure on" 131072 "light_on" 262144 "TN_48V_on" -2147483648 "Signal_unfilled" ;
